VERSION ""

NS_ :

BS_:

BU_: WCM VPM VLM VKM UVM TIM TEST_TOOL_2 TEST_TOOL_1 TCP TCM TCCM3 TCCM STC SRR_SRR SRR_SLR SRR_RR SRR_RF SRR_LR_CR SRR_LF SIB SDM SCL SBZA_R SBZA_L SBM SADS RadioLow RSC RDCM PTM PDR PA NVM MTCM_R MTCM_L MSM_RR MSM_P MSM_LR MSM_D MSB2 MSB1 MRCM_R MRCM_L MFC LRR_HC LRR LIB1 IPC ICS_Info ICCM HVAC_FP_R HVAC_FP_F HUD_CAN HDLM FCM_LC FCM EPS EOCM_HCP2 EOCM_HCP1 EOCM ELM ECP_X1 ECP_MC ECP_E ECM EBCM DMS DEFC DCM CSM CMMb CMMa CGM BSM_MH BSM BCM ARS ARB APA AOS AMP ALC AHS AHL_AFL AGC

BO_ 212 C8_SRRSLRODP_First_Frame_PDU: 48 SRR_SLR
 SG_ SRRSLRODPB1P_MAC : 7|32@0+ (1,0) [0|4.29497e+009] "" EOCM_HCP1,EOCM_HCP2
 SG_ SRRSLRODPB1P_FCnt : 39|5@0+ (1,0) [0|31] "" EOCM_HCP1,EOCM_HCP2
 SG_ SRRSLRODPB1P_AcqTmStmAuth : 45|11@0+ (1,0) [0|2047] "ms" EOCM_HCP1,EOCM_HCP2
 SG_ SRRSLRODPB1P_BrstID : 47|2@0+ (1,0) [0|3] "" EOCM_HCP1,EOCM_HCP2
 SG_ SRRSLRODPB1P_CnstrArDtnCnfdAuth : 49|2@0+ (1,0) [0|3] "" EOCM_HCP1,EOCM_HCP2
 SG_ SRRSLRODPB1P_AcqTmStmAuth_Inv : 50|1@0+ (1,0) [0|1] "" EOCM_HCP1,EOCM_HCP2
 SG_ SRRSLRODPB1P_POTk1DynPrpAuth : 57|3@0+ (1,0) [0|4] "" EOCM_HCP1,EOCM_HCP2
 SG_ SRRSLRODPB1P_POTk1CnfdStsAuth : 59|2@0+ (1,0) [0|3] "" EOCM_HCP1,EOCM_HCP2
 SG_ SRRSLRODPB1P_MdCmdStsAuth : 61|2@0+ (1,0) [0|2] "" EOCM_HCP1,EOCM_HCP2
 SG_ SRRSLRODPB1P_CnstrArDtnStsAuth : 63|2@0+ (1,0) [0|2] "" EOCM_HCP1,EOCM_HCP2
 SG_ SRRSLRODPB1P_POTk1IDAuth : 70|7@0+ (1,0) [0|127] "" EOCM_HCP1,EOCM_HCP2
 SG_ SRRSLRODPB1P_POTk1MStsAuth : 73|2@0+ (1,0) [0|3] "" EOCM_HCP1,EOCM_HCP2
 SG_ SRRSLRODPB1P_POTk1InPthPotAuth : 79|6@0+ (2,0) [0|126] "%" EOCM_HCP1,EOCM_HCP2
 SG_ SRRSLRODPB1P_POTk1PoILAAuth : 87|9@0- (0.125,0) [-32|31.875] "m/s^2" EOCM_HCP1,EOCM_HCP2
 SG_ SRRSLRODPB1P_POTk1PoILgAAuth : 94|9@0- (0.125,0) [-32|31.875] "m/s^2" EOCM_HCP1,EOCM_HCP2
 SG_ SRRSLRODPB1P_POTk1PoILgPsAuth : 101|11@0- (0.125,0) [-128|127.875] "m" EOCM_HCP1,EOCM_HCP2
 SG_ SRRSLRODPB1P_POTk1PoILgVAuth : 106|10@0- (0.125,0) [-64|63.875] "m/s" EOCM_HCP1,EOCM_HCP2
 SG_ SRRSLRODPB1P_POTk1PoILPsAuth : 112|10@0- (0.125,0) [-64|63.875] "m" EOCM_HCP1,EOCM_HCP2
 SG_ SRRSLRODPB1P_POTk1PoILVAuth : 134|9@0- (0.125,0) [-32|31.875] "m/s" EOCM_HCP1,EOCM_HCP2
 SG_ SRRSLRODPB1P_POTk2CnfdStsAuth : 137|2@0+ (1,0) [0|3] "" EOCM_HCP1,EOCM_HCP2
 SG_ SRRSLRODPB1P_POTk1TypCnfdAuth : 139|2@0+ (1,0) [0|3] "" EOCM_HCP1,EOCM_HCP2
 SG_ SRRSLRODPB1P_POTk1TypAuth : 141|2@0+ (1,0) [0|2] "" EOCM_HCP1,EOCM_HCP2
 SG_ SRRSLRODPB1P_POTk2IDAuth : 148|7@0+ (1,0) [0|127] "" EOCM_HCP1,EOCM_HCP2
 SG_ SRRSLRODPB1P_POTk2DynPrpAuth : 151|3@0+ (1,0) [0|4] "" EOCM_HCP1,EOCM_HCP2
 SG_ SRRSLRODPB1P_POTk2InPthPotAuth : 157|6@0+ (2,0) [0|126] "%" EOCM_HCP1,EOCM_HCP2
 SG_ SRRSLRODPB1P_POTk2PoILAAuth : 165|9@0- (0.125,0) [-32|31.875] "m/s^2" EOCM_HCP1,EOCM_HCP2
 SG_ SRRSLRODPB1P_POTk2MStsAuth : 167|2@0+ (1,0) [0|3] "" EOCM_HCP1,EOCM_HCP2
 SG_ SRRSLRODPB1P_POTk2PoILgAAuth : 172|9@0- (0.125,0) [-32|31.875] "m/s^2" EOCM_HCP1,EOCM_HCP2
 SG_ SRRSLRODPB1P_POTk2PoILgPsAuth : 179|11@0- (0.125,0) [-128|127.875] "m" EOCM_HCP1,EOCM_HCP2
 SG_ SRRSLRODPB1P_POTk2PoILgVAuth : 184|10@0- (0.125,0) [-64|63.875] "m/s" EOCM_HCP1,EOCM_HCP2
 SG_ SRRSLRODPB1P_POTk2PoILPsAuth : 206|10@0- (0.125,0) [-64|63.875] "m" EOCM_HCP1,EOCM_HCP2
 SG_ SRRSLRODPB1P_POTk2PoILVAuth : 212|9@0- (0.125,0) [-32|31.875] "m/s" EOCM_HCP1,EOCM_HCP2
 SG_ SRRSLRODPB1P_POTk2TypCnfdAuth : 217|2@0+ (1,0) [0|3] "" EOCM_HCP1,EOCM_HCP2
 SG_ SRRSLRODPB1P_POTk2TypAuth : 219|2@0+ (1,0) [0|2] "" EOCM_HCP1,EOCM_HCP2
 SG_ SRRSLRODPB1P_SnsrUnvAuth : 224|1@0+ (1,0) [0|1] "" EOCM_HCP1,EOCM_HCP2
 SG_ SRRSLRODPB1P_SnsrBlckdAuth : 225|1@0+ (1,0) [0|1] "" EOCM_HCP1,EOCM_HCP2
 SG_ SRRSLRODPB1P_ServRqrdAuth : 226|1@0+ (1,0) [0|1] "" EOCM_HCP1,EOCM_HCP2
 SG_ SRRSLRODPB1P_RdTypCnfdAuth : 228|2@0+ (1,0) [0|3] "" EOCM_HCP1,EOCM_HCP2
 SG_ SRRSLRODPB1P_RdTypAuth : 231|3@0+ (1,0) [0|7] "" EOCM_HCP1,EOCM_HCP2
 SG_ SRRSLRODPB1P_VOTk1CICOPotAuth : 237|6@0+ (2,0) [0|126] "%" EOCM_HCP1,EOCM_HCP2
 SG_ SRRSLRODPB1P_SwpBndwdthStsAuth : 239|2@0+ (1,0) [0|3] "" EOCM_HCP1,EOCM_HCP2
 SG_ SRRSLRODPB1P_VOTk1IDAuth : 241|7@0+ (1,0) [0|127] "" EOCM_HCP1,EOCM_HCP2
 SG_ SRRSLRODPB1P_VOTk1DynPrpStsAuth : 242|1@0+ (1,0) [0|1] "" EOCM_HCP1,EOCM_HCP2
 SG_ SRRSLRODPB1P_VOTk1DynPrpAuth : 245|3@0+ (1,0) [0|4] "" EOCM_HCP1,EOCM_HCP2
 SG_ SRRSLRODPB1P_VOTk1CnfdStsAuth : 247|2@0+ (1,0) [0|3] "" EOCM_HCP1,EOCM_HCP2
 SG_ SRRSLRODPB1P_VOTk1PoILAAuth : 248|9@0- (0.125,0) [-32|31.875] "m/s^2" EOCM_HCP1,EOCM_HCP2
 SG_ SRRSLRODPB1P_VOTk1MStsAuth : 250|2@0+ (1,0) [0|3] "" EOCM_HCP1,EOCM_HCP2
 SG_ SRRSLRODPB1P_VOTk1PoILgAAuth : 271|9@0- (0.125,0) [-32|31.875] "m/s^2" EOCM_HCP1,EOCM_HCP2
 SG_ SRRSLRODPB1P_VOTk1PoILgPsAuth : 278|11@0- (0.125,0) [-128|127.875] "m" EOCM_HCP1,EOCM_HCP2
 SG_ SRRSLRODPB1P_VOTk1PoILgPsCAuth : 283|16@0+ (0.01,0) [0|655.35] "m^2" EOCM_HCP1,EOCM_HCP2
 SG_ SRRSLRODPB1P_VOTk1PoILgthAuth : 299|8@0+ (0.125,0) [0|31.875] "m" EOCM_HCP1,EOCM_HCP2
 SG_ SRRSLRODPB1P_VOTk1PoILgVAuth : 307|11@0- (0.125,0) [-128|127.875] "m/s" EOCM_HCP1,EOCM_HCP2
 SG_ SRRSLRODPB1P_VOTk1PoILgVCAuth : 312|10@0+ (0.125,0) [0|127.875] "(m/s)^2" EOCM_HCP1,EOCM_HCP2
 SG_ SRRSLRODPB1P_VOTk1PoILPsAuth : 334|10@0- (0.125,0) [-64|63.875] "m" EOCM_HCP1,EOCM_HCP2
 SG_ SRRSLRODPB1P_VOTk1PoILPsCAuth : 340|14@0+ (0.01,0) [0|163.83] "m^2" EOCM_HCP1,EOCM_HCP2
 SG_ SRRSLRODPB1P_VOTk1PoILVAuth : 358|9@0- (0.125,0) [-32|31.875] "m/s" EOCM_HCP1,EOCM_HCP2
 SG_ SRRSLRODPB1P_VOTk1PoILVCAuth : 365|10@0+ (0.125,0) [0|127.875] "(m/s)^2" EOCM_HCP1,EOCM_HCP2
 SG_ SRRSLRODPB1P_VOTk2PoILgthAuth : 369|8@0+ (0.125,0) [0|31.875] "m" EOCM_HCP1,EOCM_HCP2
 SG_ SRRSLRODPB1P_VOTk1TypCnfdAuth : 371|2@0+ (1,0) [0|3] "" EOCM_HCP1,EOCM_HCP2
 SG_ SRRSLRODPB1P_ARC : 377|2@0+ (1,0) [0|3] "" EOCM_HCP1,EOCM_HCP2

BO_ 217 C8_SRRSLRODP_Last_Frame_PDU: 48 SRR_SLR
 SG_ SRRSLRODPB6P_IOTk10PolLPsAuth : 5|10@0- (0.125,0) [-64|63.875] "m" EOCM_HCP1,EOCM_HCP2
 SG_ SRRSLRODPB6P_BrstID : 7|2@0+ (1,0) [0|3] "" EOCM_HCP1,EOCM_HCP2
 SG_ SRRSLRODPB6P_IOTk1PoILPsAuth : 11|10@0- (0.125,0) [-64|63.875] "m" EOCM_HCP1,EOCM_HCP2
 SG_ SRRSLRODPB6P_IOTk2PolLPsAuth : 17|10@0- (0.125,0) [-64|63.875] "m" EOCM_HCP1,EOCM_HCP2
 SG_ SRRSLRODPB6P_IOTk3PolLPsAuth : 39|10@0- (0.125,0) [-64|63.875] "m" EOCM_HCP1,EOCM_HCP2
 SG_ SRRSLRODPB6P_IOTk4PolLPsAuth : 45|10@0- (0.125,0) [-64|63.875] "m" EOCM_HCP1,EOCM_HCP2
 SG_ SRRSLRODPB6P_IOTk5PolLPsAuth : 51|10@0- (0.125,0) [-64|63.875] "m" EOCM_HCP1,EOCM_HCP2
 SG_ SRRSLRODPB6P_IOTk6PolLPsAuth : 57|10@0- (0.125,0) [-64|63.875] "m" EOCM_HCP1,EOCM_HCP2
 SG_ SRRSLRODPB6P_IOTk7PolLPsAuth : 79|10@0- (0.125,0) [-64|63.875] "m" EOCM_HCP1,EOCM_HCP2
 SG_ SRRSLRODPB6P_IOTk8PolLPsAuth : 85|10@0- (0.125,0) [-64|63.875] "m" EOCM_HCP1,EOCM_HCP2
 SG_ SRRSLRODPB6P_IOTk9PolLPsAuth : 91|10@0- (0.125,0) [-64|63.875] "m" EOCM_HCP1,EOCM_HCP2
 SG_ SRRSLRODPB6P_REOTk1CnfdStsAuth : 97|2@0+ (1,0) [0|3] "" EOCM_HCP1,EOCM_HCP2
 SG_ SRRSLRODPB6P_REOTk1CrvAuth : 111|16@0- (9.77e-07,0) [-0.0320143|0.0320134] "1/m" EOCM_HCP1,EOCM_HCP2
 SG_ SRRSLRODPB6P_REOTk1CrvDrvtAuth : 127|16@0- (3.73e-09,0) [-0.000122225|0.000122221] "1/m2" EOCM_HCP1,EOCM_HCP2
 SG_ SRRSLRODPB6P_REOTk1HdgAuth : 143|10@0- (0.000977,0) [-0.500224|0.499247] "rad" EOCM_HCP1,EOCM_HCP2
 SG_ SRRSLRODPB6P_REOTk1OfstAuth : 149|9@0- (0.125,0) [-32|31.875] "m" EOCM_HCP1,EOCM_HCP2
 SG_ SRRSLRODPB6P_REOTk1PsEndAuth : 156|11@0- (0.125,0) [-128|127.875] "m" EOCM_HCP1,EOCM_HCP2
 SG_ SRRSLRODPB6P_REOTk1PsStrtAuth : 161|11@0- (0.125,0) [-128|127.875] "m" EOCM_HCP1,EOCM_HCP2
 SG_ SRRSLRODPB6P_REOTk2CnfdStsAuth : 177|2@0+ (1,0) [0|3] "" EOCM_HCP1,EOCM_HCP2
 SG_ SRRSLRODPB6P_REOTk1TypCnfdAuth : 179|2@0+ (1,0) [0|3] "" EOCM_HCP1,EOCM_HCP2
 SG_ SRRSLRODPB6P_REOTk1TypAuth : 182|3@0+ (1,0) [0|5] "" EOCM_HCP1,EOCM_HCP2
 SG_ SRRSLRODPB6P_REOTk2CrvAuth : 191|16@0- (9.77e-07,0) [-0.0320143|0.0320134] "1/m" EOCM_HCP1,EOCM_HCP2
 SG_ SRRSLRODPB6P_REOTk2CrvDrvtAuth : 207|16@0- (3.73e-09,0) [-0.000122225|0.000122221] "1/m2" EOCM_HCP1,EOCM_HCP2
 SG_ SRRSLRODPB6P_REOTk2HdgAuth : 223|10@0- (0.000977,0) [-0.500224|0.499247] "rad" EOCM_HCP1,EOCM_HCP2
 SG_ SRRSLRODPB6P_REOTk2OfstAuth : 229|9@0- (0.125,0) [-32|31.875] "m" EOCM_HCP1,EOCM_HCP2
 SG_ SRRSLRODPB6P_REOTk2PsEndAuth : 236|11@0- (0.125,0) [-128|127.875] "m" EOCM_HCP1,EOCM_HCP2
 SG_ SRRSLRODPB6P_REOTk2PsStrtAuth : 241|11@0- (0.125,0) [-128|127.875] "m" EOCM_HCP1,EOCM_HCP2
 SG_ SRRSLRODPB6P_REOTk3CnfdStsAuth : 257|2@0+ (1,0) [0|3] "" EOCM_HCP1,EOCM_HCP2
 SG_ SRRSLRODPB6P_REOTk2TypCnfdAuth : 259|2@0+ (1,0) [0|3] "" EOCM_HCP1,EOCM_HCP2
 SG_ SRRSLRODPB6P_REOTk2TypAuth : 262|3@0+ (1,0) [0|5] "" EOCM_HCP1,EOCM_HCP2
 SG_ SRRSLRODPB6P_REOTk3CrvAuth : 271|16@0- (9.77e-07,0) [-0.0320143|0.0320134] "1/m" EOCM_HCP1,EOCM_HCP2
 SG_ SRRSLRODPB6P_REOTk3CrvDrvtAuth : 287|16@0- (3.73e-09,0) [-0.000122225|0.000122221] "1/m2" EOCM_HCP1,EOCM_HCP2
 SG_ SRRSLRODPB6P_REOTk3HdgAuth : 303|10@0- (0.000977,0) [-0.500224|0.499247] "rad" EOCM_HCP1,EOCM_HCP2
 SG_ SRRSLRODPB6P_REOTk3OfstAuth : 309|9@0- (0.125,0) [-32|31.875] "m" EOCM_HCP1,EOCM_HCP2
 SG_ SRRSLRODPB6P_REOTk3PsEndAuth : 316|11@0- (0.125,0) [-128|127.875] "m" EOCM_HCP1,EOCM_HCP2
 SG_ SRRSLRODPB6P_REOTk3PsStrtAuth : 321|11@0- (0.125,0) [-128|127.875] "m" EOCM_HCP1,EOCM_HCP2
 SG_ SRRSLRODPB6P_REOTk3TypCnfdAuth : 339|2@0+ (1,0) [0|3] "" EOCM_HCP1,EOCM_HCP2
 SG_ SRRSLRODPB6P_REOTk3TypAuth : 342|3@0+ (1,0) [0|5] "" EOCM_HCP1,EOCM_HCP2

BO_ 219 C8_SRRSRRODP_Consecutive_Frame_N: 64 SRR_SRR
 SG_ SRRSRRODPB2P_POTk3IDAuth : 0|7@0+ (1,0) [0|127] "" EOCM_HCP1,EOCM_HCP2
 SG_ SRRSRRODPB2P_POTk3DynPrpAuth : 3|3@0+ (1,0) [0|4] "" EOCM_HCP1,EOCM_HCP2
 SG_ SRRSRRODPB2P_POTk3CnfdStsAuth : 5|2@0+ (1,0) [0|3] "" EOCM_HCP1,EOCM_HCP2
 SG_ SRRSRRODPB2P_BrstID : 7|2@0+ (1,0) [0|3] "" EOCM_HCP1,EOCM_HCP2
 SG_ SRRSRRODPB2P_POTk3InPthPotAuth : 9|6@0+ (2,0) [0|126] "%" EOCM_HCP1,EOCM_HCP2
 SG_ SRRSRRODPB2P_POTk3PoILAAuth : 17|9@0- (0.125,0) [-32|31.875] "m/s^2" EOCM_HCP1,EOCM_HCP2
 SG_ SRRSRRODPB2P_POTk3MStsAuth : 19|2@0+ (1,0) [0|3] "" EOCM_HCP1,EOCM_HCP2
 SG_ SRRSRRODPB2P_POTk3PoILgAAuth : 24|9@0- (0.125,0) [-32|31.875] "m/s^2" EOCM_HCP1,EOCM_HCP2
 SG_ SRRSRRODPB2P_POTk3PoILgPsAuth : 47|11@0- (0.125,0) [-128|127.875] "m" EOCM_HCP1,EOCM_HCP2
 SG_ SRRSRRODPB2P_POTk3PoILgVAuth : 52|10@0- (0.125,0) [-64|63.875] "m/s" EOCM_HCP1,EOCM_HCP2
 SG_ SRRSRRODPB2P_POTk3PoILPsAuth : 58|10@0- (0.125,0) [-64|63.875] "m" EOCM_HCP1,EOCM_HCP2
 SG_ SRRSRRODPB2P_POTk3PoILVAuth : 64|9@0- (0.125,0) [-32|31.875] "m/s" EOCM_HCP1,EOCM_HCP2
 SG_ SRRSRRODPB2P_VOTk2CICOPotAuth : 83|6@0+ (2,0) [0|126] "%" EOCM_HCP1,EOCM_HCP2
 SG_ SRRSRRODPB2P_POTk3TypCnfdAuth : 85|2@0+ (1,0) [0|3] "" EOCM_HCP1,EOCM_HCP2
 SG_ SRRSRRODPB2P_POTk3TypAuth : 87|2@0+ (1,0) [0|2] "" EOCM_HCP1,EOCM_HCP2
 SG_ SRRSRRODPB2P_VOTk2DynPrpStsAuth : 88|1@0+ (1,0) [0|1] "" EOCM_HCP1,EOCM_HCP2
 SG_ SRRSRRODPB2P_VOTk2DynPrpAuth : 91|3@0+ (1,0) [0|4] "" EOCM_HCP1,EOCM_HCP2
 SG_ SRRSRRODPB2P_VOTk2CnfdStsAuth : 93|2@0+ (1,0) [0|3] "" EOCM_HCP1,EOCM_HCP2
 SG_ SRRSRRODPB2P_VOTk2MStsAuth : 96|2@0+ (1,0) [0|3] "" EOCM_HCP1,EOCM_HCP2
 SG_ SRRSRRODPB2P_VOTk2IDAuth : 103|7@0+ (1,0) [0|127] "" EOCM_HCP1,EOCM_HCP2
 SG_ SRRSRRODPB2P_VOTk2PoILAAuth : 110|9@0- (0.125,0) [-32|31.875] "m/s^2" EOCM_HCP1,EOCM_HCP2
 SG_ SRRSRRODPB2P_VOTk2PoILgAAuth : 117|9@0- (0.125,0) [-32|31.875] "m/s^2" EOCM_HCP1,EOCM_HCP2
 SG_ SRRSRRODPB2P_VOTk2PoILgPsAuth : 124|11@0- (0.125,0) [-128|127.875] "m" EOCM_HCP1,EOCM_HCP2
 SG_ SRRSRRODPB2P_VOTk2PoILgPsCAuth : 129|16@0+ (0.01,0) [0|655.35] "m^2" EOCM_HCP1,EOCM_HCP2
 SG_ SRRSRRODPB2P_VOTk2PoILgVAuth : 145|11@0- (0.125,0) [-128|127.875] "m/s" EOCM_HCP1,EOCM_HCP2
 SG_ SRRSRRODPB2P_VOTk2PoILgVCAuth : 166|10@0+ (0.125,0) [0|127.875] "(m/s)^2" EOCM_HCP1,EOCM_HCP2
 SG_ SRRSRRODPB2P_VOTk2PoILPsAuth : 172|10@0- (0.125,0) [-64|63.875] "m" EOCM_HCP1,EOCM_HCP2
 SG_ SRRSRRODPB2P_VOTk2PoILPsCAuth : 178|14@0+ (0.01,0) [0|163.83] "m^2" EOCM_HCP1,EOCM_HCP2
 SG_ SRRSRRODPB2P_VOTk2PoILVAuth : 196|9@0- (0.125,0) [-32|31.875] "m/s" EOCM_HCP1,EOCM_HCP2
 SG_ SRRSRRODPB2P_VOTk2PoILVCAuth : 203|10@0+ (0.125,0) [0|127.875] "(m/s)^2" EOCM_HCP1,EOCM_HCP2
 SG_ SRRSRRODPB2P_VOTk2TypCnfdAuth : 209|2@0+ (1,0) [0|3] "" EOCM_HCP1,EOCM_HCP2
 SG_ SRRSRRODPB2P_VOTk3CnfdStsAuth : 217|2@0+ (1,0) [0|3] "" EOCM_HCP1,EOCM_HCP2
 SG_ SRRSRRODPB2P_VOTk3CICOPotAuth : 223|6@0+ (2,0) [0|126] "%" EOCM_HCP1,EOCM_HCP2
 SG_ SRRSRRODPB2P_VOTk3IDAuth : 227|7@0+ (1,0) [0|127] "" EOCM_HCP1,EOCM_HCP2
 SG_ SRRSRRODPB2P_VOTk3DynPrpStsAuth : 228|1@0+ (1,0) [0|1] "" EOCM_HCP1,EOCM_HCP2
 SG_ SRRSRRODPB2P_VOTk3DynPrpAuth : 231|3@0+ (1,0) [0|4] "" EOCM_HCP1,EOCM_HCP2
 SG_ SRRSRRODPB2P_VOTk3PoILAAuth : 234|9@0- (0.125,0) [-32|31.875] "m/s^2" EOCM_HCP1,EOCM_HCP2
 SG_ SRRSRRODPB2P_VOTk3MStsAuth : 236|2@0+ (1,0) [0|3] "" EOCM_HCP1,EOCM_HCP2
 SG_ SRRSRRODPB2P_VOTk3PoILgAAuth : 241|9@0- (0.125,0) [-32|31.875] "m/s^2" EOCM_HCP1,EOCM_HCP2
 SG_ SRRSRRODPB2P_VOTk3PoILgPsAuth : 248|11@0- (0.125,0) [-128|127.875] "m" EOCM_HCP1,EOCM_HCP2
 SG_ SRRSRRODPB2P_VOTk3PoILgPsCAuth : 269|16@0+ (0.01,0) [0|655.35] "m^2" EOCM_HCP1,EOCM_HCP2
 SG_ SRRSRRODPB2P_VOTk3PoILgthAuth : 285|8@0+ (0.125,0) [0|31.875] "m" EOCM_HCP1,EOCM_HCP2
 SG_ SRRSRRODPB2P_VOTk3PoILgVAuth : 293|11@0- (0.125,0) [-128|127.875] "m/s" EOCM_HCP1,EOCM_HCP2
 SG_ SRRSRRODPB2P_VOTk3PoILgVCAuth : 298|10@0+ (0.125,0) [0|127.875] "(m/s)^2" EOCM_HCP1,EOCM_HCP2
 SG_ SRRSRRODPB2P_VOTk3PoILPsAuth : 304|10@0- (0.125,0) [-64|63.875] "m" EOCM_HCP1,EOCM_HCP2
 SG_ SRRSRRODPB2P_VOTk3PoILPsCAuth : 326|14@0+ (0.01,0) [0|163.83] "m^2" EOCM_HCP1,EOCM_HCP2
 SG_ SRRSRRODPB2P_VOTk3PoILVAuth : 328|9@0- (0.125,0) [-32|31.875] "m/s" EOCM_HCP1,EOCM_HCP2
 SG_ SRRSRRODPB2P_VOTk3PoILVCAuth : 351|10@0+ (0.125,0) [0|127.875] "(m/s)^2" EOCM_HCP1,EOCM_HCP2
 SG_ SRRSRRODPB2P_VOTk4CICOPotAuth : 355|6@0+ (2,0) [0|126] "%" EOCM_HCP1,EOCM_HCP2
 SG_ SRRSRRODPB2P_VOTk3TypCnfdAuth : 357|2@0+ (1,0) [0|3] "" EOCM_HCP1,EOCM_HCP2
 SG_ SRRSRRODPB2P_VOTk4DynPrpStsAuth : 360|1@0+ (1,0) [0|1] "" EOCM_HCP1,EOCM_HCP2
 SG_ SRRSRRODPB2P_VOTk4DynPrpAuth : 363|3@0+ (1,0) [0|4] "" EOCM_HCP1,EOCM_HCP2
 SG_ SRRSRRODPB2P_VOTk4CnfdStsAuth : 365|2@0+ (1,0) [0|3] "" EOCM_HCP1,EOCM_HCP2
 SG_ SRRSRRODPB2P_VOTk4MStsAuth : 368|2@0+ (1,0) [0|3] "" EOCM_HCP1,EOCM_HCP2
 SG_ SRRSRRODPB2P_VOTk4IDAuth : 375|7@0+ (1,0) [0|127] "" EOCM_HCP1,EOCM_HCP2
 SG_ SRRSRRODPB2P_VOTk4PoILAAuth : 382|9@0- (0.125,0) [-32|31.875] "m/s^2" EOCM_HCP1,EOCM_HCP2
 SG_ SRRSRRODPB2P_VOTk4PoILgAAuth : 389|9@0- (0.125,0) [-32|31.875] "m/s^2" EOCM_HCP1,EOCM_HCP2
 SG_ SRRSRRODPB2P_VOTk4PoILgPsAuth : 396|11@0- (0.125,0) [-128|127.875] "m" EOCM_HCP1,EOCM_HCP2
 SG_ SRRSRRODPB2P_VOTk4PoILgPsCAuth : 401|16@0+ (0.01,0) [0|655.35] "m^2" EOCM_HCP1,EOCM_HCP2
 SG_ SRRSRRODPB2P_VOTk4PoILgthAuth : 417|8@0+ (0.125,0) [0|31.875] "m" EOCM_HCP1,EOCM_HCP2
 SG_ SRRSRRODPB2P_VOTk4PoILgVAuth : 425|11@0- (0.125,0) [-128|127.875] "m/s" EOCM_HCP1,EOCM_HCP2
 SG_ SRRSRRODPB2P_VOTk4PoILgVCAuth : 446|10@0+ (0.125,0) [0|127.875] "(m/s)^2" EOCM_HCP1,EOCM_HCP2
 SG_ SRRSRRODPB2P_VOTk4PoILPsAuth : 452|10@0- (0.125,0) [-64|63.875] "m" EOCM_HCP1,EOCM_HCP2
 SG_ SRRSRRODPB2P_VOTk4PoILPsCAuth : 458|14@0+ (0.01,0) [0|163.83] "m^2" EOCM_HCP1,EOCM_HCP2
 SG_ SRRSRRODPB2P_VOTk4PoILVAuth : 476|9@0- (0.125,0) [-32|31.875] "m/s" EOCM_HCP1,EOCM_HCP2
 SG_ SRRSRRODPB2P_VOTk4PoILVCAuth : 483|10@0+ (0.125,0) [0|127.875] "(m/s)^2" EOCM_HCP1,EOCM_HCP2
 SG_ SRRSRRODPB2P_VOTk4TypCnfdAuth : 489|2@0+ (1,0) [0|3] "" EOCM_HCP1,EOCM_HCP2
 SG_ SRRSRRODPB2P_VOTk5PoILgthAuth : 503|8@0+ (0.125,0) [0|31.875] "m" EOCM_HCP1,EOCM_HCP2

BO_ 220 C8_SRRSRRODP_Consecutive_Frame01: 64 SRR_SRR
 SG_ SRRSRRODPB3P_POTk4IDAuth : 0|7@0+ (1,0) [0|127] "" EOCM_HCP1,EOCM_HCP2
 SG_ SRRSRRODPB3P_POTk4DynPrpAuth : 3|3@0+ (1,0) [0|4] "" EOCM_HCP1,EOCM_HCP2
 SG_ SRRSRRODPB3P_POTk4CnfdStsAuth : 5|2@0+ (1,0) [0|3] "" EOCM_HCP1,EOCM_HCP2
 SG_ SRRSRRODPB3P_BrstID : 7|2@0+ (1,0) [0|3] "" EOCM_HCP1,EOCM_HCP2
 SG_ SRRSRRODPB3P_POTk4InPthPotAuth : 9|6@0+ (2,0) [0|126] "%" EOCM_HCP1,EOCM_HCP2
 SG_ SRRSRRODPB3P_POTk4PoILAAuth : 17|9@0- (0.125,0) [-32|31.875] "m/s^2" EOCM_HCP1,EOCM_HCP2
 SG_ SRRSRRODPB3P_POTk4MStsAuth : 19|2@0+ (1,0) [0|3] "" EOCM_HCP1,EOCM_HCP2
 SG_ SRRSRRODPB3P_POTk4PoILgAAuth : 24|9@0- (0.125,0) [-32|31.875] "m/s^2" EOCM_HCP1,EOCM_HCP2
 SG_ SRRSRRODPB3P_POTk4PoILgPsAuth : 47|11@0- (0.125,0) [-128|127.875] "m" EOCM_HCP1,EOCM_HCP2
 SG_ SRRSRRODPB3P_POTk4PoILgVAuth : 52|10@0- (0.125,0) [-64|63.875] "m/s" EOCM_HCP1,EOCM_HCP2
 SG_ SRRSRRODPB3P_POTk4PoILPsAuth : 58|10@0- (0.125,0) [-64|63.875] "m" EOCM_HCP1,EOCM_HCP2
 SG_ SRRSRRODPB3P_POTk4PoILVAuth : 64|9@0- (0.125,0) [-32|31.875] "m/s" EOCM_HCP1,EOCM_HCP2
 SG_ SRRSRRODPB3P_VOTk5CICOPotAuth : 83|6@0+ (2,0) [0|126] "%" EOCM_HCP1,EOCM_HCP2
 SG_ SRRSRRODPB3P_POTk4TypCnfdAuth : 85|2@0+ (1,0) [0|3] "" EOCM_HCP1,EOCM_HCP2
 SG_ SRRSRRODPB3P_POTk4TypAuth : 87|2@0+ (1,0) [0|2] "" EOCM_HCP1,EOCM_HCP2
 SG_ SRRSRRODPB3P_VOTk5DynPrpStsAuth : 88|1@0+ (1,0) [0|1] "" EOCM_HCP1,EOCM_HCP2
 SG_ SRRSRRODPB3P_VOTk5DynPrpAuth : 91|3@0+ (1,0) [0|4] "" EOCM_HCP1,EOCM_HCP2
 SG_ SRRSRRODPB3P_VOTk5CnfdStsAuth : 93|2@0+ (1,0) [0|3] "" EOCM_HCP1,EOCM_HCP2
 SG_ SRRSRRODPB3P_VOTk5MStsAuth : 96|2@0+ (1,0) [0|3] "" EOCM_HCP1,EOCM_HCP2
 SG_ SRRSRRODPB3P_VOTk5IDAuth : 103|7@0+ (1,0) [0|127] "" EOCM_HCP1,EOCM_HCP2
 SG_ SRRSRRODPB3P_VOTk5PoILAAuth : 110|9@0- (0.125,0) [-32|31.875] "m/s^2" EOCM_HCP1,EOCM_HCP2
 SG_ SRRSRRODPB3P_VOTk5PoILgAAuth : 117|9@0- (0.125,0) [-32|31.875] "m/s^2" EOCM_HCP1,EOCM_HCP2
 SG_ SRRSRRODPB3P_VOTk5PoILgPsAuth : 124|11@0- (0.125,0) [-128|127.875] "m" EOCM_HCP1,EOCM_HCP2
 SG_ SRRSRRODPB3P_VOTk5PoILgPsCAuth : 129|16@0+ (0.01,0) [0|655.35] "m^2" EOCM_HCP1,EOCM_HCP2
 SG_ SRRSRRODPB3P_VOTk5PoILgVAuth : 145|11@0- (0.125,0) [-128|127.875] "m/s" EOCM_HCP1,EOCM_HCP2
 SG_ SRRSRRODPB3P_VOTk5PoILgVCAuth : 166|10@0+ (0.125,0) [0|127.875] "(m/s)^2" EOCM_HCP1,EOCM_HCP2
 SG_ SRRSRRODPB3P_VOTk5PoILPsAuth : 172|10@0- (0.125,0) [-64|63.875] "m" EOCM_HCP1,EOCM_HCP2
 SG_ SRRSRRODPB3P_VOTk5PoILPsCAuth : 178|14@0+ (0.01,0) [0|163.83] "m^2" EOCM_HCP1,EOCM_HCP2
 SG_ SRRSRRODPB3P_VOTk5PoILVAuth : 196|9@0- (0.125,0) [-32|31.875] "m/s" EOCM_HCP1,EOCM_HCP2
 SG_ SRRSRRODPB3P_VOTk5PoILVCAuth : 203|10@0+ (0.125,0) [0|127.875] "(m/s)^2" EOCM_HCP1,EOCM_HCP2
 SG_ SRRSRRODPB3P_VOTk5TypCnfdAuth : 209|2@0+ (1,0) [0|3] "" EOCM_HCP1,EOCM_HCP2
 SG_ SRRSRRODPB3P_VOTk6CnfdStsAuth : 217|2@0+ (1,0) [0|3] "" EOCM_HCP1,EOCM_HCP2
 SG_ SRRSRRODPB3P_VOTk6CICOPotAuth : 223|6@0+ (2,0) [0|126] "%" EOCM_HCP1,EOCM_HCP2
 SG_ SRRSRRODPB3P_VOTk6IDAuth : 227|7@0+ (1,0) [0|127] "" EOCM_HCP1,EOCM_HCP2
 SG_ SRRSRRODPB3P_VOTk6DynPrpStsAuth : 228|1@0+ (1,0) [0|1] "" EOCM_HCP1,EOCM_HCP2
 SG_ SRRSRRODPB3P_VOTk6DynPrpAuth : 231|3@0+ (1,0) [0|4] "" EOCM_HCP1,EOCM_HCP2
 SG_ SRRSRRODPB3P_VOTk6PoILAAuth : 234|9@0- (0.125,0) [-32|31.875] "m/s^2" EOCM_HCP1,EOCM_HCP2
 SG_ SRRSRRODPB3P_VOTk6MStsAuth : 236|2@0+ (1,0) [0|3] "" EOCM_HCP1,EOCM_HCP2
 SG_ SRRSRRODPB3P_VOTk6PoILgAAuth : 241|9@0- (0.125,0) [-32|31.875] "m/s^2" EOCM_HCP1,EOCM_HCP2
 SG_ SRRSRRODPB3P_VOTk6PoILgPsAuth : 248|11@0- (0.125,0) [-128|127.875] "m" EOCM_HCP1,EOCM_HCP2
 SG_ SRRSRRODPB3P_VOTk6PoILgPsCAuth : 269|16@0+ (0.01,0) [0|655.35] "m^2" EOCM_HCP1,EOCM_HCP2
 SG_ SRRSRRODPB3P_VOTk6PoILgthAuth : 285|8@0+ (0.125,0) [0|31.875] "m" EOCM_HCP1,EOCM_HCP2
 SG_ SRRSRRODPB3P_VOTk6PoILgVAuth : 293|11@0- (0.125,0) [-128|127.875] "m/s" EOCM_HCP1,EOCM_HCP2
 SG_ SRRSRRODPB3P_VOTk6PoILgVCAuth : 298|10@0+ (0.125,0) [0|127.875] "(m/s)^2" EOCM_HCP1,EOCM_HCP2
 SG_ SRRSRRODPB3P_VOTk6PoILPsAuth : 304|10@0- (0.125,0) [-64|63.875] "m" EOCM_HCP1,EOCM_HCP2
 SG_ SRRSRRODPB3P_VOTk6PoILPsCAuth : 326|14@0+ (0.01,0) [0|163.83] "m^2" EOCM_HCP1,EOCM_HCP2
 SG_ SRRSRRODPB3P_VOTk6PoILVAuth : 328|9@0- (0.125,0) [-32|31.875] "m/s" EOCM_HCP1,EOCM_HCP2
 SG_ SRRSRRODPB3P_VOTk6PoILVCAuth : 351|10@0+ (0.125,0) [0|127.875] "(m/s)^2" EOCM_HCP1,EOCM_HCP2
 SG_ SRRSRRODPB3P_VOTk7CICOPotAuth : 355|6@0+ (2,0) [0|126] "%" EOCM_HCP1,EOCM_HCP2
 SG_ SRRSRRODPB3P_VOTk6TypCnfdAuth : 357|2@0+ (1,0) [0|3] "" EOCM_HCP1,EOCM_HCP2
 SG_ SRRSRRODPB3P_VOTk7DynPrpStsAuth : 360|1@0+ (1,0) [0|1] "" EOCM_HCP1,EOCM_HCP2
 SG_ SRRSRRODPB3P_VOTk7DynPrpAuth : 363|3@0+ (1,0) [0|4] "" EOCM_HCP1,EOCM_HCP2
 SG_ SRRSRRODPB3P_VOTk7CnfdStsAuth : 365|2@0+ (1,0) [0|3] "" EOCM_HCP1,EOCM_HCP2
 SG_ SRRSRRODPB3P_VOTk7MStsAuth : 368|2@0+ (1,0) [0|3] "" EOCM_HCP1,EOCM_HCP2
 SG_ SRRSRRODPB3P_VOTk7IDAuth : 375|7@0+ (1,0) [0|127] "" EOCM_HCP1,EOCM_HCP2
 SG_ SRRSRRODPB3P_VOTk7PoILAAuth : 382|9@0- (0.125,0) [-32|31.875] "m/s^2" EOCM_HCP1,EOCM_HCP2
 SG_ SRRSRRODPB3P_VOTk7PoILgAAuth : 389|9@0- (0.125,0) [-32|31.875] "m/s^2" EOCM_HCP1,EOCM_HCP2
 SG_ SRRSRRODPB3P_VOTk7PoILgPsAuth : 396|11@0- (0.125,0) [-128|127.875] "m" EOCM_HCP1,EOCM_HCP2
 SG_ SRRSRRODPB3P_VOTk7PoILgPsCAuth : 401|16@0+ (0.01,0) [0|655.35] "m^2" EOCM_HCP1,EOCM_HCP2
 SG_ SRRSRRODPB3P_VOTk7PoILgthAuth : 417|8@0+ (0.125,0) [0|31.875] "m" EOCM_HCP1,EOCM_HCP2
 SG_ SRRSRRODPB3P_VOTk7PoILgVAuth : 425|11@0- (0.125,0) [-128|127.875] "m/s" EOCM_HCP1,EOCM_HCP2
 SG_ SRRSRRODPB3P_VOTk7PoILgVCAuth : 446|10@0+ (0.125,0) [0|127.875] "(m/s)^2" EOCM_HCP1,EOCM_HCP2
 SG_ SRRSRRODPB3P_VOTk7PoILPsAuth : 452|10@0- (0.125,0) [-64|63.875] "m" EOCM_HCP1,EOCM_HCP2
 SG_ SRRSRRODPB3P_VOTk7PoILPsCAuth : 458|14@0+ (0.01,0) [0|163.83] "m^2" EOCM_HCP1,EOCM_HCP2
 SG_ SRRSRRODPB3P_VOTk7PoILVAuth : 476|9@0- (0.125,0) [-32|31.875] "m/s" EOCM_HCP1,EOCM_HCP2
 SG_ SRRSRRODPB3P_VOTk7PoILVCAuth : 483|10@0+ (0.125,0) [0|127.875] "(m/s)^2" EOCM_HCP1,EOCM_HCP2
 SG_ SRRSRRODPB3P_VOTk7TypCnfdAuth : 489|2@0+ (1,0) [0|3] "" EOCM_HCP1,EOCM_HCP2
 SG_ SRRSRRODPB3P_VOTk8PoILgthAuth : 503|8@0+ (0.125,0) [0|31.875] "m" EOCM_HCP1,EOCM_HCP2

BO_ 221 C8_SRRSRRODP_Consecutive_Frame02: 64 SRR_SRR
 SG_ SRRSRRODPB4P_POTk5IDAuth : 0|7@0+ (1,0) [0|127] "" EOCM_HCP1,EOCM_HCP2
 SG_ SRRSRRODPB4P_POTk5DynPrpAuth : 3|3@0+ (1,0) [0|4] "" EOCM_HCP1,EOCM_HCP2
 SG_ SRRSRRODPB4P_POTk5CnfdStsAuth : 5|2@0+ (1,0) [0|3] "" EOCM_HCP1,EOCM_HCP2
 SG_ SRRSRRODPB4P_BrstID : 7|2@0+ (1,0) [0|3] "" EOCM_HCP1,EOCM_HCP2
 SG_ SRRSRRODPB4P_POTk5InPthPotAuth : 9|6@0+ (2,0) [0|126] "%" EOCM_HCP1,EOCM_HCP2
 SG_ SRRSRRODPB4P_POTk5PoILAAuth : 17|9@0- (0.125,0) [-32|31.875] "m/s^2" EOCM_HCP1,EOCM_HCP2
 SG_ SRRSRRODPB4P_POTk5MStsAuth : 19|2@0+ (1,0) [0|3] "" EOCM_HCP1,EOCM_HCP2
 SG_ SRRSRRODPB4P_POTk5PoILgAAuth : 24|9@0- (0.125,0) [-32|31.875] "m/s^2" EOCM_HCP1,EOCM_HCP2
 SG_ SRRSRRODPB4P_POTk5PoILgPsAuth : 47|11@0- (0.125,0) [-128|127.875] "m" EOCM_HCP1,EOCM_HCP2
 SG_ SRRSRRODPB4P_POTk5PoILgVAuth : 52|10@0- (0.125,0) [-64|63.875] "m/s" EOCM_HCP1,EOCM_HCP2
 SG_ SRRSRRODPB4P_POTk5PoILPsAuth : 58|10@0- (0.125,0) [-64|63.875] "m" EOCM_HCP1,EOCM_HCP2
 SG_ SRRSRRODPB4P_POTk5PoILVAuth : 64|9@0- (0.125,0) [-32|31.875] "m/s" EOCM_HCP1,EOCM_HCP2
 SG_ SRRSRRODPB4P_VOTk10CICOPotAuth : 83|6@0+ (2,0) [0|126] "%" EOCM_HCP1,EOCM_HCP2
 SG_ SRRSRRODPB4P_POTk5TypCnfdAuth : 85|2@0+ (1,0) [0|3] "" EOCM_HCP1,EOCM_HCP2
 SG_ SRRSRRODPB4P_POTk5TypAuth : 87|2@0+ (1,0) [0|2] "" EOCM_HCP1,EOCM_HCP2
 SG_ SRRSRRODPB4P_VOTk10DynPrpStAuth : 88|1@0+ (1,0) [0|1] "" EOCM_HCP1,EOCM_HCP2
 SG_ SRRSRRODPB4P_VOTk10DynPrpAuth : 91|3@0+ (1,0) [0|4] "" EOCM_HCP1,EOCM_HCP2
 SG_ SRRSRRODPB4P_VOTk10CnfdStsAuth : 93|2@0+ (1,0) [0|3] "" EOCM_HCP1,EOCM_HCP2
 SG_ SRRSRRODPB4P_VOTk10MStsAuth : 96|2@0+ (1,0) [0|3] "" EOCM_HCP1,EOCM_HCP2
 SG_ SRRSRRODPB4P_VOTk10IDAuth : 103|7@0+ (1,0) [0|127] "" EOCM_HCP1,EOCM_HCP2
 SG_ SRRSRRODPB4P_VOTk10PoILAAuth : 110|9@0- (0.125,0) [-32|31.875] "m/s^2" EOCM_HCP1,EOCM_HCP2
 SG_ SRRSRRODPB4P_VOTk10PoILgAAuth : 117|9@0- (0.125,0) [-32|31.875] "m/s^2" EOCM_HCP1,EOCM_HCP2
 SG_ SRRSRRODPB4P_VOTk10PoILgPsAuth : 124|11@0- (0.125,0) [-128|127.875] "m" EOCM_HCP1,EOCM_HCP2
 SG_ SRRSRRODPB4P_VOTk10PoILgPsCAuth : 129|16@0+ (0.01,0) [0|655.35] "m^2" EOCM_HCP1,EOCM_HCP2
 SG_ SRRSRRODPB4P_VOTk10PoILgthAuth : 145|8@0+ (0.125,0) [0|31.875] "m" EOCM_HCP1,EOCM_HCP2
 SG_ SRRSRRODPB4P_VOTk10PoILgVAuth : 153|11@0- (0.125,0) [-128|127.875] "m/s" EOCM_HCP1,EOCM_HCP2
 SG_ SRRSRRODPB4P_VOTk10PoILgVCAuth : 174|10@0+ (0.125,0) [0|127.875] "(m/s)^2" EOCM_HCP1,EOCM_HCP2
 SG_ SRRSRRODPB4P_VOTk10PoILPsAuth : 180|10@0- (0.125,0) [-64|63.875] "m" EOCM_HCP1,EOCM_HCP2
 SG_ SRRSRRODPB4P_VOTk10PoILPsCAuth : 186|14@0+ (0.01,0) [0|163.83] "m^2" EOCM_HCP1,EOCM_HCP2
 SG_ SRRSRRODPB4P_VOTk10PoILVAuth : 204|9@0- (0.125,0) [-32|31.875] "m/s" EOCM_HCP1,EOCM_HCP2
 SG_ SRRSRRODPB4P_VOTk10PoILVCAuth : 211|10@0+ (0.125,0) [0|127.875] "(m/s)^2" EOCM_HCP1,EOCM_HCP2
 SG_ SRRSRRODPB4P_VOTk10TypCnfdAuth : 217|2@0+ (1,0) [0|3] "" EOCM_HCP1,EOCM_HCP2
 SG_ SRRSRRODPB4P_VOTk8CnfdStsAuth : 225|2@0+ (1,0) [0|3] "" EOCM_HCP1,EOCM_HCP2
 SG_ SRRSRRODPB4P_VOTk8CICOPotAuth : 231|6@0+ (2,0) [0|126] "%" EOCM_HCP1,EOCM_HCP2
 SG_ SRRSRRODPB4P_VOTk8IDAuth : 235|7@0+ (1,0) [0|127] "" EOCM_HCP1,EOCM_HCP2
 SG_ SRRSRRODPB4P_VOTk8DynPrpStsAuth : 236|1@0+ (1,0) [0|1] "" EOCM_HCP1,EOCM_HCP2
 SG_ SRRSRRODPB4P_VOTk8DynPrpAuth : 239|3@0+ (1,0) [0|4] "" EOCM_HCP1,EOCM_HCP2
 SG_ SRRSRRODPB4P_VOTk8PoILAAuth : 242|9@0- (0.125,0) [-32|31.875] "m/s^2" EOCM_HCP1,EOCM_HCP2
 SG_ SRRSRRODPB4P_VOTk8MStsAuth : 244|2@0+ (1,0) [0|3] "" EOCM_HCP1,EOCM_HCP2
 SG_ SRRSRRODPB4P_VOTk8PoILgAAuth : 249|9@0- (0.125,0) [-32|31.875] "m/s^2" EOCM_HCP1,EOCM_HCP2
 SG_ SRRSRRODPB4P_VOTk8PoILgPsAuth : 256|11@0- (0.125,0) [-128|127.875] "m" EOCM_HCP1,EOCM_HCP2
 SG_ SRRSRRODPB4P_VOTk8PoILgPsCAuth : 277|16@0+ (0.01,0) [0|655.35] "m^2" EOCM_HCP1,EOCM_HCP2
 SG_ SRRSRRODPB4P_VOTk8PoILgVAuth : 293|11@0- (0.125,0) [-128|127.875] "m/s" EOCM_HCP1,EOCM_HCP2
 SG_ SRRSRRODPB4P_VOTk8PoILgVCAuth : 298|10@0+ (0.125,0) [0|127.875] "(m/s)^2" EOCM_HCP1,EOCM_HCP2
 SG_ SRRSRRODPB4P_VOTk8PoILPsAuth : 304|10@0- (0.125,0) [-64|63.875] "m" EOCM_HCP1,EOCM_HCP2
 SG_ SRRSRRODPB4P_VOTk8PoILPsCAuth : 326|14@0+ (0.01,0) [0|163.83] "m^2" EOCM_HCP1,EOCM_HCP2
 SG_ SRRSRRODPB4P_VOTk8PoILVAuth : 328|9@0- (0.125,0) [-32|31.875] "m/s" EOCM_HCP1,EOCM_HCP2
 SG_ SRRSRRODPB4P_VOTk8PoILVCAuth : 351|10@0+ (0.125,0) [0|127.875] "(m/s)^2" EOCM_HCP1,EOCM_HCP2
 SG_ SRRSRRODPB4P_VOTk9CICOPotAuth : 355|6@0+ (2,0) [0|126] "%" EOCM_HCP1,EOCM_HCP2
 SG_ SRRSRRODPB4P_VOTk8TypCnfdAuth : 357|2@0+ (1,0) [0|3] "" EOCM_HCP1,EOCM_HCP2
 SG_ SRRSRRODPB4P_VOTk9DynPrpStsAuth : 360|1@0+ (1,0) [0|1] "" EOCM_HCP1,EOCM_HCP2
 SG_ SRRSRRODPB4P_VOTk9DynPrpAuth : 363|3@0+ (1,0) [0|4] "" EOCM_HCP1,EOCM_HCP2
 SG_ SRRSRRODPB4P_VOTk9CnfdStsAuth : 365|2@0+ (1,0) [0|3] "" EOCM_HCP1,EOCM_HCP2
 SG_ SRRSRRODPB4P_VOTk9MStsAuth : 368|2@0+ (1,0) [0|3] "" EOCM_HCP1,EOCM_HCP2
 SG_ SRRSRRODPB4P_VOTk9IDAuth : 375|7@0+ (1,0) [0|127] "" EOCM_HCP1,EOCM_HCP2
 SG_ SRRSRRODPB4P_VOTk9PoILAAuth : 382|9@0- (0.125,0) [-32|31.875] "m/s^2" EOCM_HCP1,EOCM_HCP2
 SG_ SRRSRRODPB4P_VOTk9PoILgAAuth : 389|9@0- (0.125,0) [-32|31.875] "m/s^2" EOCM_HCP1,EOCM_HCP2
 SG_ SRRSRRODPB4P_VOTk9PoILgPsAuth : 396|11@0- (0.125,0) [-128|127.875] "m" EOCM_HCP1,EOCM_HCP2
 SG_ SRRSRRODPB4P_VOTk9PoILgPsCAuth : 401|16@0+ (0.01,0) [0|655.35] "m^2" EOCM_HCP1,EOCM_HCP2
 SG_ SRRSRRODPB4P_VOTk9PoILgthAuth : 417|8@0+ (0.125,0) [0|31.875] "m" EOCM_HCP1,EOCM_HCP2
 SG_ SRRSRRODPB4P_VOTk9PoILgVAuth : 425|11@0- (0.125,0) [-128|127.875] "m/s" EOCM_HCP1,EOCM_HCP2
 SG_ SRRSRRODPB4P_VOTk9PoILgVCAuth : 446|10@0+ (0.125,0) [0|127.875] "(m/s)^2" EOCM_HCP1,EOCM_HCP2
 SG_ SRRSRRODPB4P_VOTk9PoILPsAuth : 452|10@0- (0.125,0) [-64|63.875] "m" EOCM_HCP1,EOCM_HCP2
 SG_ SRRSRRODPB4P_VOTk9PoILPsCAuth : 458|14@0+ (0.01,0) [0|163.83] "m^2" EOCM_HCP1,EOCM_HCP2
 SG_ SRRSRRODPB4P_VOTk9PoILVAuth : 476|9@0- (0.125,0) [-32|31.875] "m/s" EOCM_HCP1,EOCM_HCP2
 SG_ SRRSRRODPB4P_VOTk9PoILVCAuth : 483|10@0+ (0.125,0) [0|127.875] "(m/s)^2" EOCM_HCP1,EOCM_HCP2
 SG_ SRRSRRODPB4P_VOTk9TypCnfdAuth : 489|2@0+ (1,0) [0|3] "" EOCM_HCP1,EOCM_HCP2

BO_ 222 C8_SRRSRRODP_Consecutive_Frame03: 64 SRR_SRR
 SG_ SRRSRRODPB5P_IOTk10IDAuth : 1|7@0+ (1,0) [0|127] "" EOCM_HCP1,EOCM_HCP2
 SG_ SRRSRRODPB5P_IOTk10ElvtnAuth : 3|2@0+ (1,0) [0|3] "" EOCM_HCP1,EOCM_HCP2
 SG_ SRRSRRODPB5P_IOTk10CnfdStsAuth : 5|2@0+ (1,0) [0|3] "" EOCM_HCP1,EOCM_HCP2
 SG_ SRRSRRODPB5P_BrstID : 7|2@0+ (1,0) [0|3] "" EOCM_HCP1,EOCM_HCP2
 SG_ SRRSRRODPB5P_IOTk10PolLgPsAuth : 8|11@0- (0.125,0) [-128|127.875] "m" EOCM_HCP1,EOCM_HCP2
 SG_ SRRSRRODPB5P_IOTk10MStsAuth : 10|2@0+ (1,0) [0|3] "" EOCM_HCP1,EOCM_HCP2
 SG_ SRRSRRODPB5P_IOTk1CnfdStsAuth : 24|2@0+ (1,0) [0|3] "" EOCM_HCP1,EOCM_HCP2
 SG_ SRRSRRODPB5P_IOTk10TypCnfdAuth : 26|2@0+ (1,0) [0|3] "" EOCM_HCP1,EOCM_HCP2
 SG_ SRRSRRODPB5P_IOTk10TypAuth : 29|3@0+ (1,0) [0|5] "" EOCM_HCP1,EOCM_HCP2
 SG_ SRRSRRODPB5P_IOTk1IDAuth : 36|7@0+ (1,0) [0|127] "" EOCM_HCP1,EOCM_HCP2
 SG_ SRRSRRODPB5P_IOTk1ElvtnAuth : 38|2@0+ (1,0) [0|3] "" EOCM_HCP1,EOCM_HCP2
 SG_ SRRSRRODPB5P_IOTk1PoILgPsAuth : 43|11@0- (0.125,0) [-128|127.875] "m" EOCM_HCP1,EOCM_HCP2
 SG_ SRRSRRODPB5P_IOTk1MStsAuth : 45|2@0+ (1,0) [0|3] "" EOCM_HCP1,EOCM_HCP2
 SG_ SRRSRRODPB5P_IOTk1TypAuth : 48|3@0+ (1,0) [0|5] "" EOCM_HCP1,EOCM_HCP2
 SG_ SRRSRRODPB5P_IOTk2ElvtnAuth : 57|2@0+ (1,0) [0|3] "" EOCM_HCP1,EOCM_HCP2
 SG_ SRRSRRODPB5P_IOTk2CnfdStsAuth : 59|2@0+ (1,0) [0|3] "" EOCM_HCP1,EOCM_HCP2
 SG_ SRRSRRODPB5P_IOTk1TypCnfdAuth : 61|2@0+ (1,0) [0|3] "" EOCM_HCP1,EOCM_HCP2
 SG_ SRRSRRODPB5P_IOTk2MStsAuth : 64|2@0+ (1,0) [0|3] "" EOCM_HCP1,EOCM_HCP2
 SG_ SRRSRRODPB5P_IOTk2IDAuth : 71|7@0+ (1,0) [0|127] "" EOCM_HCP1,EOCM_HCP2
 SG_ SRRSRRODPB5P_IOTk2PolLgPsAuth : 78|11@0- (0.125,0) [-128|127.875] "m" EOCM_HCP1,EOCM_HCP2
 SG_ SRRSRRODPB5P_IOTk2TypCnfdAuth : 80|2@0+ (1,0) [0|3] "" EOCM_HCP1,EOCM_HCP2
 SG_ SRRSRRODPB5P_IOTk2TypAuth : 83|3@0+ (1,0) [0|5] "" EOCM_HCP1,EOCM_HCP2
 SG_ SRRSRRODPB5P_IOTk3IDAuth : 90|7@0+ (1,0) [0|127] "" EOCM_HCP1,EOCM_HCP2
 SG_ SRRSRRODPB5P_IOTk3ElvtnAuth : 92|2@0+ (1,0) [0|3] "" EOCM_HCP1,EOCM_HCP2
 SG_ SRRSRRODPB5P_IOTk3CnfdStsAuth : 94|2@0+ (1,0) [0|3] "" EOCM_HCP1,EOCM_HCP2
 SG_ SRRSRRODPB5P_IOTk3PolLgPsAuth : 97|11@0- (0.125,0) [-128|127.875] "m" EOCM_HCP1,EOCM_HCP2
 SG_ SRRSRRODPB5P_IOTk3MStsAuth : 99|2@0+ (1,0) [0|3] "" EOCM_HCP1,EOCM_HCP2
 SG_ SRRSRRODPB5P_IOTk4CnfdStsAuth : 113|2@0+ (1,0) [0|3] "" EOCM_HCP1,EOCM_HCP2
 SG_ SRRSRRODPB5P_IOTk3TypCnfdAuth : 115|2@0+ (1,0) [0|3] "" EOCM_HCP1,EOCM_HCP2
 SG_ SRRSRRODPB5P_IOTk3TypAuth : 118|3@0+ (1,0) [0|5] "" EOCM_HCP1,EOCM_HCP2
 SG_ SRRSRRODPB5P_IOTk4IDAuth : 125|7@0+ (1,0) [0|127] "" EOCM_HCP1,EOCM_HCP2
 SG_ SRRSRRODPB5P_IOTk4ElvtnAuth : 127|2@0+ (1,0) [0|3] "" EOCM_HCP1,EOCM_HCP2
 SG_ SRRSRRODPB5P_IOTk4PolLgPsAuth : 132|11@0- (0.125,0) [-128|127.875] "m" EOCM_HCP1,EOCM_HCP2
 SG_ SRRSRRODPB5P_IOTk4MStsAuth : 134|2@0+ (1,0) [0|3] "" EOCM_HCP1,EOCM_HCP2
 SG_ SRRSRRODPB5P_IOTk4TypAuth : 137|3@0+ (1,0) [0|5] "" EOCM_HCP1,EOCM_HCP2
 SG_ SRRSRRODPB5P_IOTk5IDAuth : 144|7@0+ (1,0) [0|127] "" EOCM_HCP1,EOCM_HCP2
 SG_ SRRSRRODPB5P_IOTk5ElvtnAuth : 146|2@0+ (1,0) [0|3] "" EOCM_HCP1,EOCM_HCP2
 SG_ SRRSRRODPB5P_IOTk5CnfdStsAuth : 148|2@0+ (1,0) [0|3] "" EOCM_HCP1,EOCM_HCP2
 SG_ SRRSRRODPB5P_IOTk4TypCnfdAuth : 150|2@0+ (1,0) [0|3] "" EOCM_HCP1,EOCM_HCP2
 SG_ SRRSRRODPB5P_IOTk5MStsAuth : 153|2@0+ (1,0) [0|3] "" EOCM_HCP1,EOCM_HCP2
 SG_ SRRSRRODPB5P_IOTk5PolLgPsAuth : 167|11@0- (0.125,0) [-128|127.875] "m" EOCM_HCP1,EOCM_HCP2
 SG_ SRRSRRODPB5P_IOTk5TypCnfdAuth : 169|2@0+ (1,0) [0|3] "" EOCM_HCP1,EOCM_HCP2
 SG_ SRRSRRODPB5P_IOTk5TypAuth : 172|3@0+ (1,0) [0|5] "" EOCM_HCP1,EOCM_HCP2
 SG_ SRRSRRODPB5P_IOTk6IDAuth : 179|7@0+ (1,0) [0|127] "" EOCM_HCP1,EOCM_HCP2
 SG_ SRRSRRODPB5P_IOTk6ElvtnAuth : 181|2@0+ (1,0) [0|3] "" EOCM_HCP1,EOCM_HCP2
 SG_ SRRSRRODPB5P_IOTk6CnfdStsAuth : 183|2@0+ (1,0) [0|3] "" EOCM_HCP1,EOCM_HCP2
 SG_ SRRSRRODPB5P_IOTk6PolLgPsAuth : 186|11@0- (0.125,0) [-128|127.875] "m" EOCM_HCP1,EOCM_HCP2
 SG_ SRRSRRODPB5P_IOTk6MStsAuth : 188|2@0+ (1,0) [0|3] "" EOCM_HCP1,EOCM_HCP2
 SG_ SRRSRRODPB5P_IOTk7ElvtnAuth : 200|2@0+ (1,0) [0|3] "" EOCM_HCP1,EOCM_HCP2
 SG_ SRRSRRODPB5P_IOTk7CnfdStsAuth : 202|2@0+ (1,0) [0|3] "" EOCM_HCP1,EOCM_HCP2
 SG_ SRRSRRODPB5P_IOTk6TypCnfdAuth : 204|2@0+ (1,0) [0|3] "" EOCM_HCP1,EOCM_HCP2
 SG_ SRRSRRODPB5P_IOTk6TypAuth : 207|3@0+ (1,0) [0|5] "" EOCM_HCP1,EOCM_HCP2
 SG_ SRRSRRODPB5P_IOTk7IDAuth : 214|7@0+ (1,0) [0|127] "" EOCM_HCP1,EOCM_HCP2
 SG_ SRRSRRODPB5P_IOTk7PolLgPsAuth : 221|11@0- (0.125,0) [-128|127.875] "m" EOCM_HCP1,EOCM_HCP2
 SG_ SRRSRRODPB5P_IOTk7MStsAuth : 223|2@0+ (1,0) [0|3] "" EOCM_HCP1,EOCM_HCP2
 SG_ SRRSRRODPB5P_IOTk7TypAuth : 226|3@0+ (1,0) [0|5] "" EOCM_HCP1,EOCM_HCP2
 SG_ SRRSRRODPB5P_IOTk8IDAuth : 233|7@0+ (1,0) [0|127] "" EOCM_HCP1,EOCM_HCP2
 SG_ SRRSRRODPB5P_IOTk8ElvtnAuth : 235|2@0+ (1,0) [0|3] "" EOCM_HCP1,EOCM_HCP2
 SG_ SRRSRRODPB5P_IOTk8CnfdStsAuth : 237|2@0+ (1,0) [0|3] "" EOCM_HCP1,EOCM_HCP2
 SG_ SRRSRRODPB5P_IOTk7TypCnfdAuth : 239|2@0+ (1,0) [0|3] "" EOCM_HCP1,EOCM_HCP2
 SG_ SRRSRRODPB5P_IOTk8PolLgPsAuth : 240|11@0- (0.125,0) [-128|127.875] "m" EOCM_HCP1,EOCM_HCP2
 SG_ SRRSRRODPB5P_IOTk8MStsAuth : 242|2@0+ (1,0) [0|3] "" EOCM_HCP1,EOCM_HCP2
 SG_ SRRSRRODPB5P_IOTk9CnfdStsAuth : 256|2@0+ (1,0) [0|3] "" EOCM_HCP1,EOCM_HCP2
 SG_ SRRSRRODPB5P_IOTk8TypCnfdAuth : 258|2@0+ (1,0) [0|3] "" EOCM_HCP1,EOCM_HCP2
 SG_ SRRSRRODPB5P_IOTk8TypAuth : 261|3@0+ (1,0) [0|5] "" EOCM_HCP1,EOCM_HCP2
 SG_ SRRSRRODPB5P_IOTk9IDAuth : 268|7@0+ (1,0) [0|127] "" EOCM_HCP1,EOCM_HCP2
 SG_ SRRSRRODPB5P_IOTk9ElvtnAuth : 270|2@0+ (1,0) [0|3] "" EOCM_HCP1,EOCM_HCP2
 SG_ SRRSRRODPB5P_IOTk9PolLgPsAuth : 275|11@0- (0.125,0) [-128|127.875] "m" EOCM_HCP1,EOCM_HCP2
 SG_ SRRSRRODPB5P_IOTk9MStsAuth : 277|2@0+ (1,0) [0|3] "" EOCM_HCP1,EOCM_HCP2
 SG_ SRRSRRODPB5P_IOTk9TypAuth : 280|3@0+ (1,0) [0|5] "" EOCM_HCP1,EOCM_HCP2
 SG_ SRRSRRODPB5P_VOTk9PoI2LgPsAuth : 291|11@0- (0.125,0) [-128|127.875] "m" EOCM_HCP1,EOCM_HCP2
 SG_ SRRSRRODPB5P_IOTk9TypCnfdAuth : 293|2@0+ (1,0) [0|3] "" EOCM_HCP1,EOCM_HCP2
 SG_ SRRSRRODPB5P_VOTk9PoI2LPsAuth : 296|10@0- (0.125,0) [-64|63.875] "m" EOCM_HCP1,EOCM_HCP2
 SG_ SRRSRRODPB5P_VOTk1PoI2LgPsAuth : 318|11@0- (0.125,0) [-128|127.875] "m" EOCM_HCP1,EOCM_HCP2
 SG_ SRRSRRODPB5P_VOTk1PoI2LPsAuth : 323|10@0- (0.125,0) [-64|63.875] "m" EOCM_HCP1,EOCM_HCP2
 SG_ SRRSRRODPB5P_VOTk2PoI2LgPsAuth : 329|11@0- (0.125,0) [-128|127.875] "m" EOCM_HCP1,EOCM_HCP2
 SG_ SRRSRRODPB5P_VOTk2PoI2LPsAuth : 350|10@0- (0.125,0) [-64|63.875] "m" EOCM_HCP1,EOCM_HCP2
 SG_ SRRSRRODPB5P_VOTk3PoI2LgPsAuth : 356|11@0- (0.125,0) [-128|127.875] "m" EOCM_HCP1,EOCM_HCP2
 SG_ SRRSRRODPB5P_VOTk3PoI2LPsAuth : 361|10@0- (0.125,0) [-64|63.875] "m" EOCM_HCP1,EOCM_HCP2
 SG_ SRRSRRODPB5P_VOTk4PoI2LgPsAuth : 383|11@0- (0.125,0) [-128|127.875] "m" EOCM_HCP1,EOCM_HCP2
 SG_ SRRSRRODPB5P_VOTk4PoI2LPsAuth : 388|10@0- (0.125,0) [-64|63.875] "m" EOCM_HCP1,EOCM_HCP2
 SG_ SRRSRRODPB5P_VOTk5Pol2LgPsAuth : 394|11@0- (0.125,0) [-128|127.875] "m" EOCM_HCP1,EOCM_HCP2
 SG_ SRRSRRODPB5P_VOTk5Pol2LPsAuth : 415|10@0- (0.125,0) [-64|63.875] "m" EOCM_HCP1,EOCM_HCP2
 SG_ SRRSRRODPB5P_VOTk6PoI2LgPsAuth : 421|11@0- (0.125,0) [-128|127.875] "m" EOCM_HCP1,EOCM_HCP2
 SG_ SRRSRRODPB5P_VOTk6PoI2LPsAuth : 426|10@0- (0.125,0) [-64|63.875] "m" EOCM_HCP1,EOCM_HCP2
 SG_ SRRSRRODPB5P_VOTk7PoI2LgPsAuth : 432|11@0- (0.125,0) [-128|127.875] "m" EOCM_HCP1,EOCM_HCP2
 SG_ SRRSRRODPB5P_VOTk7PoI2LPsAuth : 453|10@0- (0.125,0) [-64|63.875] "m" EOCM_HCP1,EOCM_HCP2
 SG_ SRRSRRODPB5P_VOTk8PoI2LgPsAuth : 459|11@0- (0.125,0) [-128|127.875] "m" EOCM_HCP1,EOCM_HCP2
 SG_ SRRSRRODPB5P_VOTk8PoI2LPsAuth : 464|10@0- (0.125,0) [-64|63.875] "m" EOCM_HCP1,EOCM_HCP2
 SG_ SRRSRRODPB5P_VOTk10PoI2LgPsAuth : 486|11@0- (0.125,0) [-128|127.875] "m" EOCM_HCP1,EOCM_HCP2
 SG_ SRRSRRODPB5P_VOTk10PoI2LPsAuth : 491|10@0- (0.125,0) [-64|63.875] "m" EOCM_HCP1,EOCM_HCP2

BO_ 218 C8_SRRSRRODP_First_Frame_PDU: 48 SRR_SRR
 SG_ SRRSRRODPB1P_MAC : 7|32@0+ (1,0) [0|4.29497e+009] "" EOCM_HCP1,EOCM_HCP2
 SG_ SRRSRRODPB1P_FCnt : 39|5@0+ (1,0) [0|31] "" EOCM_HCP1,EOCM_HCP2
 SG_ SRRSRRODPB1P_AcqTmStmAuth : 45|11@0+ (1,0) [0|2047] "ms" EOCM_HCP1,EOCM_HCP2
 SG_ SRRSRRODPB1P_BrstID : 47|2@0+ (1,0) [0|3] "" EOCM_HCP1,EOCM_HCP2
 SG_ SRRSRRODPB1P_CnstrArDtnCnfdAuth : 49|2@0+ (1,0) [0|3] "" EOCM_HCP1,EOCM_HCP2
 SG_ SRRSRRODPB1P_AcqTmStmAuth_Inv : 50|1@0+ (1,0) [0|1] "" EOCM_HCP1,EOCM_HCP2
 SG_ SRRSRRODPB1P_POTk1DynPrpAuth : 57|3@0+ (1,0) [0|4] "" EOCM_HCP1,EOCM_HCP2
 SG_ SRRSRRODPB1P_POTk1CnfdStsAuth : 59|2@0+ (1,0) [0|3] "" EOCM_HCP1,EOCM_HCP2
 SG_ SRRSRRODPB1P_MdCmdStsAuth : 61|2@0+ (1,0) [0|2] "" EOCM_HCP1,EOCM_HCP2
 SG_ SRRSRRODPB1P_CnstrArDtnStsAuth : 63|2@0+ (1,0) [0|2] "" EOCM_HCP1,EOCM_HCP2
 SG_ SRRSRRODPB1P_POTk1IDAuth : 70|7@0+ (1,0) [0|127] "" EOCM_HCP1,EOCM_HCP2
 SG_ SRRSRRODPB1P_POTk1MStsAuth : 73|2@0+ (1,0) [0|3] "" EOCM_HCP1,EOCM_HCP2
 SG_ SRRSRRODPB1P_POTk1InPthPotAuth : 79|6@0+ (2,0) [0|126] "%" EOCM_HCP1,EOCM_HCP2
 SG_ SRRSRRODPB1P_POTk1PoILAAuth : 87|9@0- (0.125,0) [-32|31.875] "m/s^2" EOCM_HCP1,EOCM_HCP2
 SG_ SRRSRRODPB1P_POTk1PoILgAAuth : 94|9@0- (0.125,0) [-32|31.875] "m/s^2" EOCM_HCP1,EOCM_HCP2
 SG_ SRRSRRODPB1P_POTk1PoILgPsAuth : 101|11@0- (0.125,0) [-128|127.875] "m" EOCM_HCP1,EOCM_HCP2
 SG_ SRRSRRODPB1P_POTk1PoILgVAuth : 106|10@0- (0.125,0) [-64|63.875] "m/s" EOCM_HCP1,EOCM_HCP2
 SG_ SRRSRRODPB1P_POTk1PoILPsAuth : 112|10@0- (0.125,0) [-64|63.875] "m" EOCM_HCP1,EOCM_HCP2
 SG_ SRRSRRODPB1P_POTk1PoILVAuth : 134|9@0- (0.125,0) [-32|31.875] "m/s" EOCM_HCP1,EOCM_HCP2
 SG_ SRRSRRODPB1P_POTk2CnfdStsAuth : 137|2@0+ (1,0) [0|3] "" EOCM_HCP1,EOCM_HCP2
 SG_ SRRSRRODPB1P_POTk1TypCnfdAuth : 139|2@0+ (1,0) [0|3] "" EOCM_HCP1,EOCM_HCP2
 SG_ SRRSRRODPB1P_POTk1TypAuth : 141|2@0+ (1,0) [0|2] "" EOCM_HCP1,EOCM_HCP2
 SG_ SRRSRRODPB1P_POTk2IDAuth : 148|7@0+ (1,0) [0|127] "" EOCM_HCP1,EOCM_HCP2
 SG_ SRRSRRODPB1P_POTk2DynPrpAuth : 151|3@0+ (1,0) [0|4] "" EOCM_HCP1,EOCM_HCP2
 SG_ SRRSRRODPB1P_POTk2InPthPotAuth : 157|6@0+ (2,0) [0|126] "%" EOCM_HCP1,EOCM_HCP2
 SG_ SRRSRRODPB1P_POTk2PoILAAuth : 165|9@0- (0.125,0) [-32|31.875] "m/s^2" EOCM_HCP1,EOCM_HCP2
 SG_ SRRSRRODPB1P_POTk2MStsAuth : 167|2@0+ (1,0) [0|3] "" EOCM_HCP1,EOCM_HCP2
 SG_ SRRSRRODPB1P_POTk2PoILgAAuth : 172|9@0- (0.125,0) [-32|31.875] "m/s^2" EOCM_HCP1,EOCM_HCP2
 SG_ SRRSRRODPB1P_POTk2PoILgPsAuth : 179|11@0- (0.125,0) [-128|127.875] "m" EOCM_HCP1,EOCM_HCP2
 SG_ SRRSRRODPB1P_POTk2PoILgVAuth : 184|10@0- (0.125,0) [-64|63.875] "m/s" EOCM_HCP1,EOCM_HCP2
 SG_ SRRSRRODPB1P_POTk2PoILPsAuth : 206|10@0- (0.125,0) [-64|63.875] "m" EOCM_HCP1,EOCM_HCP2
 SG_ SRRSRRODPB1P_POTk2PoILVAuth : 212|9@0- (0.125,0) [-32|31.875] "m/s" EOCM_HCP1,EOCM_HCP2
 SG_ SRRSRRODPB1P_POTk2TypCnfdAuth : 217|2@0+ (1,0) [0|3] "" EOCM_HCP1,EOCM_HCP2
 SG_ SRRSRRODPB1P_POTk2TypAuth : 219|2@0+ (1,0) [0|2] "" EOCM_HCP1,EOCM_HCP2
 SG_ SRRSRRODPB1P_SnsrUnvAuth : 224|1@0+ (1,0) [0|1] "" EOCM_HCP1,EOCM_HCP2
 SG_ SRRSRRODPB1P_SnsrBlckdAuth : 225|1@0+ (1,0) [0|1] "" EOCM_HCP1,EOCM_HCP2
 SG_ SRRSRRODPB1P_ServRqrdAuth : 226|1@0+ (1,0) [0|1] "" EOCM_HCP1,EOCM_HCP2
 SG_ SRRSRRODPB1P_RdTypCnfdAuth : 228|2@0+ (1,0) [0|3] "" EOCM_HCP1,EOCM_HCP2
 SG_ SRRSRRODPB1P_RdTypAuth : 231|3@0+ (1,0) [0|7] "" EOCM_HCP1,EOCM_HCP2
 SG_ SRRSRRODPB1P_VOTk1CICOPotAuth : 237|6@0+ (2,0) [0|126] "%" EOCM_HCP1,EOCM_HCP2
 SG_ SRRSRRODPB1P_SwpBndwdthStsAuth : 239|2@0+ (1,0) [0|3] "" EOCM_HCP1,EOCM_HCP2
 SG_ SRRSRRODPB1P_VOTk1IDAuth : 241|7@0+ (1,0) [0|127] "" EOCM_HCP1,EOCM_HCP2
 SG_ SRRSRRODPB1P_VOTk1DynPrpStsAuth : 242|1@0+ (1,0) [0|1] "" EOCM_HCP1,EOCM_HCP2
 SG_ SRRSRRODPB1P_VOTk1DynPrpAuth : 245|3@0+ (1,0) [0|4] "" EOCM_HCP1,EOCM_HCP2
 SG_ SRRSRRODPB1P_VOTk1CnfdStsAuth : 247|2@0+ (1,0) [0|3] "" EOCM_HCP1,EOCM_HCP2
 SG_ SRRSRRODPB1P_VOTk1PoILAAuth : 248|9@0- (0.125,0) [-32|31.875] "m/s^2" EOCM_HCP1,EOCM_HCP2
 SG_ SRRSRRODPB1P_VOTk1MStsAuth : 250|2@0+ (1,0) [0|3] "" EOCM_HCP1,EOCM_HCP2
 SG_ SRRSRRODPB1P_VOTk1PoILgAAuth : 271|9@0- (0.125,0) [-32|31.875] "m/s^2" EOCM_HCP1,EOCM_HCP2
 SG_ SRRSRRODPB1P_VOTk1PoILgPsAuth : 278|11@0- (0.125,0) [-128|127.875] "m" EOCM_HCP1,EOCM_HCP2
 SG_ SRRSRRODPB1P_VOTk1PoILgPsCAuth : 283|16@0+ (0.01,0) [0|655.35] "m^2" EOCM_HCP1,EOCM_HCP2
 SG_ SRRSRRODPB1P_VOTk1PoILgthAuth : 299|8@0+ (0.125,0) [0|31.875] "m" EOCM_HCP1,EOCM_HCP2
 SG_ SRRSRRODPB1P_VOTk1PoILgVAuth : 307|11@0- (0.125,0) [-128|127.875] "m/s" EOCM_HCP1,EOCM_HCP2
 SG_ SRRSRRODPB1P_VOTk1PoILgVCAuth : 312|10@0+ (0.125,0) [0|127.875] "(m/s)^2" EOCM_HCP1,EOCM_HCP2
 SG_ SRRSRRODPB1P_VOTk1PoILPsAuth : 334|10@0- (0.125,0) [-64|63.875] "m" EOCM_HCP1,EOCM_HCP2
 SG_ SRRSRRODPB1P_VOTk1PoILPsCAuth : 340|14@0+ (0.01,0) [0|163.83] "m^2" EOCM_HCP1,EOCM_HCP2
 SG_ SRRSRRODPB1P_VOTk1PoILVAuth : 358|9@0- (0.125,0) [-32|31.875] "m/s" EOCM_HCP1,EOCM_HCP2
 SG_ SRRSRRODPB1P_VOTk1PoILVCAuth : 365|10@0+ (0.125,0) [0|127.875] "(m/s)^2" EOCM_HCP1,EOCM_HCP2
 SG_ SRRSRRODPB1P_VOTk2PoILgthAuth : 369|8@0+ (0.125,0) [0|31.875] "m" EOCM_HCP1,EOCM_HCP2
 SG_ SRRSRRODPB1P_VOTk1TypCnfdAuth : 371|2@0+ (1,0) [0|3] "" EOCM_HCP1,EOCM_HCP2
 SG_ SRRSRRODPB1P_ARC : 377|2@0+ (1,0) [0|3] "" EOCM_HCP1,EOCM_HCP2

BO_ 223 C8_SRRSRRODP_Last_Frame_PDU: 48 SRR_SRR
 SG_ SRRSRRODPB6P_IOTk10PolLPsAuth : 5|10@0- (0.125,0) [-64|63.875] "m" EOCM_HCP1,EOCM_HCP2
 SG_ SRRSRRODPB6P_BrstID : 7|2@0+ (1,0) [0|3] "" EOCM_HCP1,EOCM_HCP2
 SG_ SRRSRRODPB6P_IOTk1PoILPsAuth : 11|10@0- (0.125,0) [-64|63.875] "m" EOCM_HCP1,EOCM_HCP2
 SG_ SRRSRRODPB6P_IOTk2PolLPsAuth : 17|10@0- (0.125,0) [-64|63.875] "m" EOCM_HCP1,EOCM_HCP2
 SG_ SRRSRRODPB6P_IOTk3PolLPsAuth : 39|10@0- (0.125,0) [-64|63.875] "m" EOCM_HCP1,EOCM_HCP2
 SG_ SRRSRRODPB6P_IOTk4PolLPsAuth : 45|10@0- (0.125,0) [-64|63.875] "m" EOCM_HCP1,EOCM_HCP2
 SG_ SRRSRRODPB6P_IOTk5PolLPsAuth : 51|10@0- (0.125,0) [-64|63.875] "m" EOCM_HCP1,EOCM_HCP2
 SG_ SRRSRRODPB6P_IOTk6PolLPsAuth : 57|10@0- (0.125,0) [-64|63.875] "m" EOCM_HCP1,EOCM_HCP2
 SG_ SRRSRRODPB6P_IOTk7PolLPsAuth : 79|10@0- (0.125,0) [-64|63.875] "m" EOCM_HCP1,EOCM_HCP2
 SG_ SRRSRRODPB6P_IOTk8PolLPsAuth : 85|10@0- (0.125,0) [-64|63.875] "m" EOCM_HCP1,EOCM_HCP2
 SG_ SRRSRRODPB6P_IOTk9PolLPsAuth : 91|10@0- (0.125,0) [-64|63.875] "m" EOCM_HCP1,EOCM_HCP2
 SG_ SRRSRRODPB6P_REOTk1CnfdStsAuth : 97|2@0+ (1,0) [0|3] "" EOCM_HCP1,EOCM_HCP2
 SG_ SRRSRRODPB6P_REOTk1CrvAuth : 111|16@0- (9.77e-07,0) [-0.0320143|0.0320134] "1/m" EOCM_HCP1,EOCM_HCP2
 SG_ SRRSRRODPB6P_REOTk1CrvDrvtAuth : 127|16@0- (3.73e-09,0) [-0.000122225|0.000122221] "1/m2" EOCM_HCP1,EOCM_HCP2
 SG_ SRRSRRODPB6P_REOTk1HdgAuth : 143|10@0- (0.000977,0) [-0.500224|0.499247] "rad" EOCM_HCP1,EOCM_HCP2
 SG_ SRRSRRODPB6P_REOTk1OfstAuth : 149|9@0- (0.125,0) [-32|31.875] "m" EOCM_HCP1,EOCM_HCP2
 SG_ SRRSRRODPB6P_REOTk1PsEndAuth : 156|11@0- (0.125,0) [-128|127.875] "m" EOCM_HCP1,EOCM_HCP2
 SG_ SRRSRRODPB6P_REOTk1PsStrtAuth : 161|11@0- (0.125,0) [-128|127.875] "m" EOCM_HCP1,EOCM_HCP2
 SG_ SRRSRRODPB6P_REOTk2CnfdStsAuth : 177|2@0+ (1,0) [0|3] "" EOCM_HCP1,EOCM_HCP2
 SG_ SRRSRRODPB6P_REOTk1TypCnfdAuth : 179|2@0+ (1,0) [0|3] "" EOCM_HCP1,EOCM_HCP2
 SG_ SRRSRRODPB6P_REOTk1TypAuth : 182|3@0+ (1,0) [0|5] "" EOCM_HCP1,EOCM_HCP2
 SG_ SRRSRRODPB6P_REOTk2CrvAuth : 191|16@0- (9.77e-07,0) [-0.0320143|0.0320134] "1/m" EOCM_HCP1,EOCM_HCP2
 SG_ SRRSRRODPB6P_REOTk2CrvDrvtAuth : 207|16@0- (3.73e-09,0) [-0.000122225|0.000122221] "1/m2" EOCM_HCP1,EOCM_HCP2
 SG_ SRRSRRODPB6P_REOTk2HdgAuth : 223|10@0- (0.000977,0) [-0.500224|0.499247] "rad" EOCM_HCP1,EOCM_HCP2
 SG_ SRRSRRODPB6P_REOTk2OfstAuth : 229|9@0- (0.125,0) [-32|31.875] "m" EOCM_HCP1,EOCM_HCP2
 SG_ SRRSRRODPB6P_REOTk2PsEndAuth : 236|11@0- (0.125,0) [-128|127.875] "m" EOCM_HCP1,EOCM_HCP2
 SG_ SRRSRRODPB6P_REOTk2PsStrtAuth : 241|11@0- (0.125,0) [-128|127.875] "m" EOCM_HCP1,EOCM_HCP2
 SG_ SRRSRRODPB6P_REOTk3CnfdStsAuth : 257|2@0+ (1,0) [0|3] "" EOCM_HCP1,EOCM_HCP2
 SG_ SRRSRRODPB6P_REOTk2TypCnfdAuth : 259|2@0+ (1,0) [0|3] "" EOCM_HCP1,EOCM_HCP2
 SG_ SRRSRRODPB6P_REOTk2TypAuth : 262|3@0+ (1,0) [0|5] "" EOCM_HCP1,EOCM_HCP2
 SG_ SRRSRRODPB6P_REOTk3CrvAuth : 271|16@0- (9.77e-07,0) [-0.0320143|0.0320134] "1/m" EOCM_HCP1,EOCM_HCP2
 SG_ SRRSRRODPB6P_REOTk3CrvDrvtAuth : 287|16@0- (3.73e-09,0) [-0.000122225|0.000122221] "1/m2" EOCM_HCP1,EOCM_HCP2
 SG_ SRRSRRODPB6P_REOTk3HdgAuth : 303|10@0- (0.000977,0) [-0.500224|0.499247] "rad" EOCM_HCP1,EOCM_HCP2
 SG_ SRRSRRODPB6P_REOTk3OfstAuth : 309|9@0- (0.125,0) [-32|31.875] "m" EOCM_HCP1,EOCM_HCP2
 SG_ SRRSRRODPB6P_REOTk3PsEndAuth : 316|11@0- (0.125,0) [-128|127.875] "m" EOCM_HCP1,EOCM_HCP2
 SG_ SRRSRRODPB6P_REOTk3PsStrtAuth : 321|11@0- (0.125,0) [-128|127.875] "m" EOCM_HCP1,EOCM_HCP2
 SG_ SRRSRRODPB6P_REOTk3TypCnfdAuth : 339|2@0+ (1,0) [0|3] "" EOCM_HCP1,EOCM_HCP2
 SG_ SRRSRRODPB6P_REOTk3TypAuth : 342|3@0+ (1,0) [0|5] "" EOCM_HCP1,EOCM_HCP2

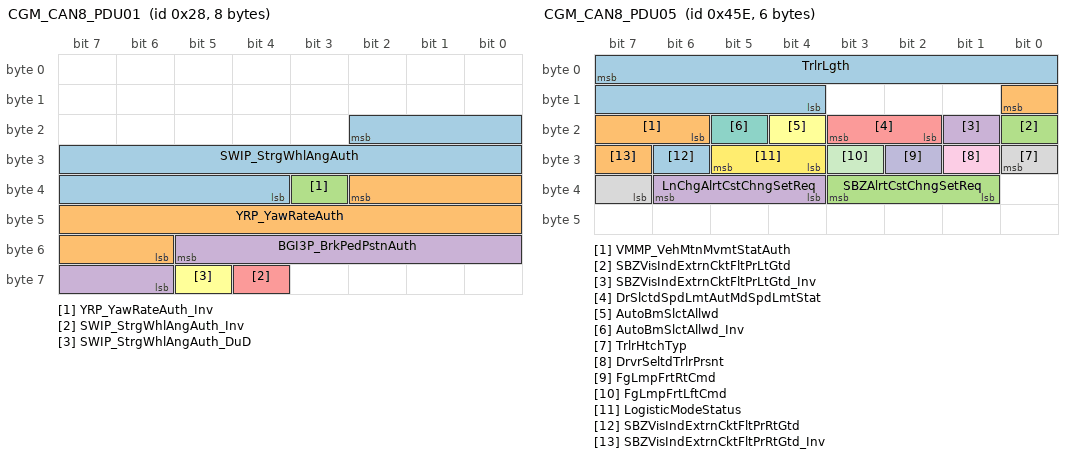
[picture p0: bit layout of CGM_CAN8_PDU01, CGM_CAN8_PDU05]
BO_ 40 CGM_CAN8_PDU01: 8 CGM
 SG_ SWIP_StrgWhlAngAuth : 18|15@0- (0.0625,0) [-1024|1023.94] "deg" FCM_LC,SRR_LR_CR,SRR_RR,SRR_SLR,SRR_SRR
 SG_ YRP_YawRateAuth : 34|13@0- (0.024,0) [-98.304|98.28] "Deg/Sec" FCM_LC,SRR_LR_CR,SRR_RR,SRR_SLR,SRR_SRR
 SG_ YRP_YawRateAuth_Inv : 35|1@0+ (1,0) [0|1] "" FCM_LC,SRR_LR_CR,SRR_RR
 SG_ BGI3P_BrkPedPstnAuth : 53|8@0+ (0.392157,0) [0|100] "%" FCM_LC
 SG_ SWIP_StrgWhlAngAuth_Inv : 60|1@0+ (1,0) [0|1] "" FCM_LC
 SG_ SWIP_StrgWhlAngAuth_DuD : 61|1@0+ (1,0) [0|1] "" FCM_LC

BO_ 607 CGM_CAN8_PDU02: 6 CGM
 SG_ DRCDNDP_DRCAvgDrvnAuth : 23|13@0+ (0.125,0) [0|1023.88] "m" SRR_LR_CR,SRR_RR,SRR_SLR,SRR_SRR
 SG_ DRCDNDP_DRCAvgDrvnAuth_Inv : 26|1@0+ (1,0) [0|1] "" SRR_LR_CR,SRR_RR,SRR_SLR,SRR_SRR

BO_ 1116 CGM_CAN8_PDU03: 16 CGM
 SG_ TmSyncMsg : 7|40@0+ (100,0) [0|1.09951e+014] "ms" EOCM_HCP2,FCM_LC,HDLM,LRR,LRR_HC,SRR_LF,SRR_LR_CR,SRR_RF,SRR_RR,SRR_SLR,SRR_SRR
 SG_ VODVP_VehOdoDispValAuth : 47|28@0+ (0.015625,0) [0|4.1943e+006] "km" FCM_LC,LRR,SRR_LF,SRR_LR_CR,SRR_RF,SRR_RR,SRR_SLR,SRR_SRR
 SG_ CldrYr : 67|8@0+ (1,2000) [2000|2255] "year" FCM_LC
 SG_ OATP_OtsAirTmpCrValAuth : 75|8@0+ (0.5,-40) [-40|87.5] "Deg C" FCM_LC,LRR,SRR_LF,SRR_LR_CR,SRR_RF,SRR_RR,SRR_SLR,SRR_SRR
 SG_ MinOfHr : 83|6@0+ (1,0) [0|63] "minutes" FCM_LC
 SG_ SecOfMin : 93|6@0+ (1,0) [0|63] "seconds" FCM_LC
 SG_ HrOfDay : 98|5@0+ (1,0) [0|31] "hour" FCM_LC
 SG_ CldrDay : 103|5@0+ (1,0) [0|31] "day" FCM_LC
 SG_ VODVP_VehOdoDispValAuth_Inv : 104|1@0+ (1,0) [0|1] "" FCM_LC
 SG_ OATP_OtsAirTmpCrValAuth_Inv : 105|1@0+ (1,0) [0|1] "" FCM_LC,LRR
 SG_ CldrMth : 109|4@0+ (1,0) [0|12] "" FCM_LC

BO_ 1117 CGM_CAN8_PDU04: 6 CGM
 SG_ ELWWIP_WprFrtFtrReqAuth : 7|4@0+ (1,0) [0|12] "" FCM_LC,LRR,SRR_LF,SRR_LR_CR,SRR_RF,SRR_RR,SRR_SLR,SRR_SRR

BO_ 1118 CGM_CAN8_PDU05: 6 CGM
 SG_ TrlrLgth : 7|12@0+ (1,0) [0|4095] "cm" SRR_LR_CR,SRR_RR,SRR_SLR,SRR_SRR
 SG_ VMMP_VehMtnMvmtStatAuth : 8|3@0+ (1,0) [0|4] "" FCM_LC,SRR_LR_CR,SRR_RR,SRR_SLR,SRR_SRR
 SG_ SBZVisIndExtrnCktFltPrLtGtd : 16|1@0+ (1,0) [0|1] "" SRR_SLR
 SG_ SBZVisIndExtrnCktFltPrLtGtd_Inv : 17|1@0+ (1,0) [0|1] "" SRR_SLR
 SG_ DrSlctdSpdLmtAutMdSpdLmtStat : 19|2@0+ (1,0) [0|3] "" FCM_LC
 SG_ AutoBmSlctAllwd : 20|1@0+ (1,0) [0|1] "" FCM_LC
 SG_ AutoBmSlctAllwd_Inv : 21|1@0+ (1,0) [0|1] "" FCM_LC
 SG_ TrlrHtchTyp : 24|2@0+ (1,0) [0|3] "" SRR_LR_CR,SRR_RR,SRR_SLR,SRR_SRR
 SG_ DrvrSeltdTrlrPrsnt : 25|1@0+ (1,0) [0|1] "" SRR_LR_CR,SRR_RR,SRR_SLR,SRR_SRR
 SG_ FgLmpFrtRtCmd : 26|1@0+ (1,0) [0|1] "" FCM_LC
 SG_ FgLmpFrtLftCmd : 27|1@0+ (1,0) [0|1] "" FCM_LC
 SG_ LogisticModeStatus : 29|2@0+ (1,0) [0|3] "" HDLM
 SG_ SBZVisIndExtrnCktFltPrRtGtd : 30|1@0+ (1,0) [0|1] "" SRR_SRR
 SG_ SBZVisIndExtrnCktFltPrRtGtd_Inv : 31|1@0+ (1,0) [0|1] "" SRR_SRR
 SG_ SBZAlrtCstChngSetReq : 35|3@0+ (1,0) [0|7] "" SRR_SLR
 SG_ LnChgAlrtCstChngSetReq : 38|3@0+ (1,0) [0|7] "" SRR_SLR

BO_ 1121 CGM_CAN8_PDU06: 6 CGM
 SG_ APASP_APAStsAuth : 2|3@0+ (1,0) [0|7] "" Vector__XXX
 SG_ HSP_DrvAlrtTypCstCurrSetValAuth : 5|3@0+ (1,0) [0|2] "" SRR_SLR,SRR_SRR
 SG_ HSP_HptcStOprtlStsAuth : 7|2@0+ (1,0) [0|2] "" SRR_SLR,SRR_SRR
 SG_ TrffcLgtAsstCstChgSetReq : 9|3@0+ (1,0) [0|7] "" FCM_LC
 SG_ RrCrsTrfcAlrtCstChngSetReq : 12|3@0+ (1,0) [0|7] "" SRR_SLR
 SG_ GlrFrHgBmRspTypCstChgSetReq : 15|3@0+ (1,0) [0|7] "" FCM_LC
 SG_ TSMWrngPopUpSts : 16|1@0+ (1,0) [0|1] "" FCM_LC
 SG_ TSMSgnNtfnWrnDispd : 17|1@0+ (1,0) [0|1] "" FCM_LC
 SG_ TSMPageDispActv : 18|1@0+ (1,0) [0|1] "" FCM_LC
 SG_ TSMCustRstReq : 19|1@0+ (1,0) [0|1] "" FCM_LC
 SG_ RstrCstDfltReq : 20|1@0+ (1,0) [0|1] "" FCM_LC,SRR_SLR
 SG_ DispMeasSysExtnd : 22|2@0+ (1,0) [0|3] "" FCM_LC
 SG_ BGI1P_OutsdAmbtLgtLvlStsAuth : 24|2@0+ (1,0) [0|2] "" FCM_LC
 SG_ LowBmAct : 25|1@0+ (1,0) [0|1] "" FCM_LC
 SG_ HighBmAct : 26|1@0+ (1,0) [0|1] "" FCM_LC
 SG_ TrnSigSwRtActv : 27|1@0+ (1,0) [0|1] "" FCM_LC,SRR_SRR
 SG_ TrnSigSwLtActv : 28|1@0+ (1,0) [0|1] "" FCM_LC,SRR_SLR
 SG_ TrlrConnStat : 29|1@0+ (1,0) [0|1] "" FCM_LC,SRR_LR_CR,SRR_RR,SRR_SLR,SRR_SRR
 SG_ TimeDispFormat : 30|1@0+ (1,0) [0|1] "" FCM_LC
 SG_ TDAP_TeenDrvrActvAuth : 31|1@0+ (1,0) [0|1] "" FCM_LC,SRR_SLR
 SG_ RrCrsTrfcBrkgSysSts : 35|2@0+ (1,0) [0|2] "" SRR_SLR
 SG_ TDAP_DrvrIdfrAuth : 38|3@0+ (1,0) [0|7] "" FCM_LC

BO_ 608 CGM_CAN8_PDU08: 6 CGM
 SG_ VSANDP_VehSpdAvgNDrvnAuth : 7|15@0+ (0.015625,0) [0|511.984] "Km/h" FCM_LC

BO_ 609 CGM_CAN8_PDU09: 6 CGM
 SG_ BkUpPwrMdRnCrnkOutSt : 1|1@0+ (1,0) [0|1] "" FCM_LC,LRR,SRR_LF,SRR_LR_CR,SRR_RF,SRR_RR

BO_ 325 CGM_NM_PDU_On_CAN_8_Cluster: 8 CGM
 SG_ ISignal_CGM_CAN_8_Cluster : 23|48@0+ (1,0) [0|281474976710655] "" EOCM,EOCM_HCP1,EOCM_HCP2,FCM_LC,HDLM,LRR,LRR_HC,SRR_LF,SRR_LR_CR,SRR_RF,SRR_RR,SRR_SLR,SRR_SRR

BA_DEF_ SG_  "SignalType" STRING ;
BA_DEF_ SG_  "SignalLongName" STRING ;
BA_DEF_ BO_  "GenMsgCycleTime" INT 0 10000;
BA_DEF_ BO_  "GenMsgSendType" ENUM "cyclicX","spontanX","cyclicIfActiveX","spontanWithDelay","cyclicAndSpontanX","cyclicAndSpontanWithDelay","spontanWithRepetition","cyclicIfActiveAndSpontanWD";
BA_DEF_ BO_  "VFrameFormat" ENUM  "StandardCAN","ExtendedCAN","reserved","reserved","reserved","reserved","reserved","reserved","reserved","reserved","reserved","reserved","reserved","reserved","StandardCAN_FD","ExtendedCAN_FD";
BA_DEF_DEF_  "SignalType" "";
BA_DEF_DEF_  "SignalLongName" "";
BA_DEF_DEF_  "GenMsgCycleTime" 0;
BA_DEF_DEF_  "GenMsgSendType" "cyclicX";
BA_DEF_DEF_  "VFrameFormat" "StandardCAN";
BA_ "VFrameFormat" BO_ 212 14;
BA_ "VFrameFormat" BO_ 217 14;
BA_ "VFrameFormat" BO_ 219 14;
BA_ "VFrameFormat" BO_ 220 14;
BA_ "VFrameFormat" BO_ 221 14;
BA_ "VFrameFormat" BO_ 222 14;
BA_ "VFrameFormat" BO_ 218 14;
BA_ "VFrameFormat" BO_ 223 14;
BA_ "GenMsgCycleTime" BO_ 40 10;
BA_ "VFrameFormat" BO_ 40 14;
BA_ "GenMsgCycleTime" BO_ 607 100;
BA_ "VFrameFormat" BO_ 607 14;
BA_ "GenMsgCycleTime" BO_ 1116 1000;
BA_ "VFrameFormat" BO_ 1116 14;
BA_ "GenMsgCycleTime" BO_ 1117 1000;
BA_ "VFrameFormat" BO_ 1117 14;
BA_ "GenMsgCycleTime" BO_ 1118 1000;
BA_ "VFrameFormat" BO_ 1118 14;
BA_ "GenMsgCycleTime" BO_ 1121 1000;
BA_ "VFrameFormat" BO_ 1121 14;
BA_ "GenMsgCycleTime" BO_ 608 250;
BA_ "VFrameFormat" BO_ 608 14;
BA_ "GenMsgCycleTime" BO_ 609 250;
BA_ "VFrameFormat" BO_ 609 14;
BA_ "SignalLongName" SG_ 212 SRRSLRODPB1P_MAC "Short Range Radar Side Left Rear Object Detection and Processing Burst 1 Protected : MAC";
BA_ "SignalLongName" SG_ 212 SRRSLRODPB1P_FCnt "Short Range Radar Side Left Rear Object Detection and Processing Burst 1 Protected : Freshness Counter";
BA_ "SignalLongName" SG_ 212 SRRSLRODPB1P_AcqTmStmAuth "Short Range Radar Side Left Rear Object Detection and Processing Burst 1 Protected : Acquisition Time Stamp Authenticated";
BA_ "SignalLongName" SG_ 212 SRRSLRODPB1P_BrstID "Short Range Radar Side Left Rear Object Detection and Processing Burst 1 Protected : Burst ID";
BA_ "SignalType" SG_ 212 SRRSLRODPB1P_CnstrArDtnCnfdAuth "ENM";
BA_ "SignalLongName" SG_ 212 SRRSLRODPB1P_CnstrArDtnCnfdAuth "Short Range Radar Side Left Rear Object Detection and Processing Burst 1 Protected : Construction Area Detection Confidence Authenticated";
BA_ "SignalType" SG_ 212 SRRSLRODPB1P_AcqTmStmAuth_Inv "ENM";
BA_ "SignalLongName" SG_ 212 SRRSLRODPB1P_AcqTmStmAuth_Inv "Short Range Radar Side Left Rear Object Detection and Processing Burst 1 Protected : Acquisition Time Stamp Authenticated Invalid";
BA_ "SignalType" SG_ 212 SRRSLRODPB1P_POTk1DynPrpAuth "ENM";
BA_ "SignalLongName" SG_ 212 SRRSLRODPB1P_POTk1DynPrpAuth "Short Range Radar Side Left Rear Object Detection and Processing Burst 1 Protected : Pedestrian Object Track 1 Dynamic Property Authenticated";
BA_ "SignalType" SG_ 212 SRRSLRODPB1P_POTk1CnfdStsAuth "ENM";
BA_ "SignalLongName" SG_ 212 SRRSLRODPB1P_POTk1CnfdStsAuth "Short Range Radar Side Left Rear Object Detection and Processing Burst 1 Protected : Pedestrian Object Track 1 Confidence Status Authenticated";
BA_ "SignalType" SG_ 212 SRRSLRODPB1P_MdCmdStsAuth "ENM";
BA_ "SignalLongName" SG_ 212 SRRSLRODPB1P_MdCmdStsAuth "Short Range Radar Side Left Rear Object Detection and Processing Burst 1 Protected : Mode Command Status Authenticated";
BA_ "SignalType" SG_ 212 SRRSLRODPB1P_CnstrArDtnStsAuth "ENM";
BA_ "SignalLongName" SG_ 212 SRRSLRODPB1P_CnstrArDtnStsAuth "Short Range Radar Side Left Rear Object Detection and Processing Burst 1 Protected : Construction Area Detection Status Authenticated";
BA_ "SignalLongName" SG_ 212 SRRSLRODPB1P_POTk1IDAuth "Short Range Radar Side Left Rear Object Detection and Processing Burst 1 Protected : Pedestrian Object Track 1 ID Authenticated";
BA_ "SignalType" SG_ 212 SRRSLRODPB1P_POTk1MStsAuth "ENM";
BA_ "SignalLongName" SG_ 212 SRRSLRODPB1P_POTk1MStsAuth "Short Range Radar Side Left Rear Object Detection and Processing Burst 1 Protected : Pedestrian Object Track 1 Measurement Status Authenticated";
BA_ "SignalLongName" SG_ 212 SRRSLRODPB1P_POTk1InPthPotAuth "Short Range Radar Side Left Rear Object Detection and Processing Burst 1 Protected : Pedestrian Object Track 1 In Path Potential Authenticated";
BA_ "SignalLongName" SG_ 212 SRRSLRODPB1P_POTk1PoILAAuth "Short Range Radar Side Left Rear Object Detection and Processing Burst 1 Protected : Pedestrian Object Track 1 Point of Interest Lateral Acceleration Authenticated";
BA_ "SignalLongName" SG_ 212 SRRSLRODPB1P_POTk1PoILgAAuth "Short Range Radar Side Left Rear Object Detection and Processing Burst 1 Protected : Pedestrian Object Track 1 Point of Interest Longitudinal Acceleration Authenticated";
BA_ "SignalLongName" SG_ 212 SRRSLRODPB1P_POTk1PoILgPsAuth "Short Range Radar Side Left Rear Object Detection and Processing Burst 1 Protected : Pedestrian Object Track 1 Point of Interest Longitudinal Position Authenticated";
BA_ "SignalLongName" SG_ 212 SRRSLRODPB1P_POTk1PoILgVAuth "Short Range Radar Side Left Rear Object Detection and Processing Burst 1 Protected : Pedestrian Object Track 1 Point of Interest Longitudinal Velocity Authenticated";
BA_ "SignalLongName" SG_ 212 SRRSLRODPB1P_POTk1PoILPsAuth "Short Range Radar Side Left Rear Object Detection and Processing Burst 1 Protected : Pedestrian Object Track 1 Point of Interest Lateral Position Authenticated";
BA_ "SignalLongName" SG_ 212 SRRSLRODPB1P_POTk1PoILVAuth "Short Range Radar Side Left Rear Object Detection and Processing Burst 1 Protected : Pedestrian Object Track 1 Point of Interest Lateral Velocity Authenticated";
BA_ "SignalType" SG_ 212 SRRSLRODPB1P_POTk2CnfdStsAuth "ENM";
BA_ "SignalLongName" SG_ 212 SRRSLRODPB1P_POTk2CnfdStsAuth "Short Range Radar Side Left Rear Object Detection and Processing Burst 1 Protected : Pedestrian Object Track 2 Confidence Status Authenticated";
BA_ "SignalType" SG_ 212 SRRSLRODPB1P_POTk1TypCnfdAuth "ENM";
BA_ "SignalLongName" SG_ 212 SRRSLRODPB1P_POTk1TypCnfdAuth "Short Range Radar Side Left Rear Object Detection and Processing Burst 1 Protected : Pedestrian Object Track 1 Type Confidence Authenticated";
BA_ "SignalType" SG_ 212 SRRSLRODPB1P_POTk1TypAuth "ENM";
BA_ "SignalLongName" SG_ 212 SRRSLRODPB1P_POTk1TypAuth "Short Range Radar Side Left Rear Object Detection and Processing Burst 1 Protected : Pedestrian Object Track 1 Type Authenticated";
BA_ "SignalLongName" SG_ 212 SRRSLRODPB1P_POTk2IDAuth "Short Range Radar Side Left Rear Object Detection and Processing Burst 1 Protected : Pedestrian Object Track 2 ID Authenticated";
BA_ "SignalType" SG_ 212 SRRSLRODPB1P_POTk2DynPrpAuth "ENM";
BA_ "SignalLongName" SG_ 212 SRRSLRODPB1P_POTk2DynPrpAuth "Short Range Radar Side Left Rear Object Detection and Processing Burst 1 Protected : Pedestrian Object Track 2 Dynamic Property Authenticated";
BA_ "SignalLongName" SG_ 212 SRRSLRODPB1P_POTk2InPthPotAuth "Short Range Radar Side Left Rear Object Detection and Processing Burst 1 Protected : Pedestrian Object Track 2 In Path Potential Authenticated";
BA_ "SignalLongName" SG_ 212 SRRSLRODPB1P_POTk2PoILAAuth "Short Range Radar Side Left Rear Object Detection and Processing Burst 1 Protected : Pedestrian Object Track 2 Point of Interest Lateral Acceleration Authenticated";
BA_ "SignalType" SG_ 212 SRRSLRODPB1P_POTk2MStsAuth "ENM";
BA_ "SignalLongName" SG_ 212 SRRSLRODPB1P_POTk2MStsAuth "Short Range Radar Side Left Rear Object Detection and Processing Burst 1 Protected : Pedestrian Object Track 2 Measurement Status Authenticated";
BA_ "SignalLongName" SG_ 212 SRRSLRODPB1P_POTk2PoILgAAuth "Short Range Radar Side Left Rear Object Detection and Processing Burst 1 Protected : Pedestrian Object Track 2 Point of Interest Longitudinal Acceleration Authenticated";
BA_ "SignalLongName" SG_ 212 SRRSLRODPB1P_POTk2PoILgPsAuth "Short Range Radar Side Left Rear Object Detection and Processing Burst 1 Protected : Pedestrian Object Track 2 Point of Interest Longitudinal Position Authenticated";
BA_ "SignalLongName" SG_ 212 SRRSLRODPB1P_POTk2PoILgVAuth "Short Range Radar Side Left Rear Object Detection and Processing Burst 1 Protected : Pedestrian Object Track 2 Point of Interest Longitudinal Velocity Authenticated";
BA_ "SignalLongName" SG_ 212 SRRSLRODPB1P_POTk2PoILPsAuth "Short Range Radar Side Left Rear Object Detection and Processing Burst 1 Protected : Pedestrian Object Track 2 Point of Interest Lateral Position Authenticated";
BA_ "SignalLongName" SG_ 212 SRRSLRODPB1P_POTk2PoILVAuth "Short Range Radar Side Left Rear Object Detection and Processing Burst 1 Protected : Pedestrian Object Track 2 Point of Interest Lateral Velocity Authenticated";
BA_ "SignalType" SG_ 212 SRRSLRODPB1P_POTk2TypCnfdAuth "ENM";
BA_ "SignalLongName" SG_ 212 SRRSLRODPB1P_POTk2TypCnfdAuth "Short Range Radar Side Left Rear Object Detection and Processing Burst 1 Protected : Pedestrian Object Track 2 Type Confidence Authenticated";
BA_ "SignalType" SG_ 212 SRRSLRODPB1P_POTk2TypAuth "ENM";
BA_ "SignalLongName" SG_ 212 SRRSLRODPB1P_POTk2TypAuth "Short Range Radar Side Left Rear Object Detection and Processing Burst 1 Protected : Pedestrian Object Track 2 Type Authenticated";
BA_ "SignalType" SG_ 212 SRRSLRODPB1P_SnsrUnvAuth "ENM";
BA_ "SignalLongName" SG_ 212 SRRSLRODPB1P_SnsrUnvAuth "Short Range Radar Side Left Rear Object Detection and Processing Burst 1 Protected : Sensor Unavailable Authenticated";
BA_ "SignalType" SG_ 212 SRRSLRODPB1P_SnsrBlckdAuth "ENM";
BA_ "SignalLongName" SG_ 212 SRRSLRODPB1P_SnsrBlckdAuth "Short Range Radar Side Left Rear Object Detection and Processing Burst 1 Protected : Sensor Blocked Authenticated";
BA_ "SignalType" SG_ 212 SRRSLRODPB1P_ServRqrdAuth "ENM";
BA_ "SignalLongName" SG_ 212 SRRSLRODPB1P_ServRqrdAuth "Short Range Radar Side Left Rear Object Detection and Processing Burst 1 Protected : Service Required Authenticated";
BA_ "SignalType" SG_ 212 SRRSLRODPB1P_RdTypCnfdAuth "ENM";
BA_ "SignalLongName" SG_ 212 SRRSLRODPB1P_RdTypCnfdAuth "Short Range Radar Side Left Rear Object Detection and Processing Burst 1 Protected : Road Type Confidence Authenticated";
BA_ "SignalType" SG_ 212 SRRSLRODPB1P_RdTypAuth "ENM";
BA_ "SignalLongName" SG_ 212 SRRSLRODPB1P_RdTypAuth "Short Range Radar Side Left Rear Object Detection and Processing Burst 1 Protected : Road Type Authenticated";
BA_ "SignalLongName" SG_ 212 SRRSLRODPB1P_VOTk1CICOPotAuth "Short Range Radar Side Left Rear Object Detection and Processing Burst 1 Protected : Vehicle Object Track 1 Cut In Cut Out Potential Authenticated";
BA_ "SignalType" SG_ 212 SRRSLRODPB1P_SwpBndwdthStsAuth "ENM";
BA_ "SignalLongName" SG_ 212 SRRSLRODPB1P_SwpBndwdthStsAuth "Short Range Radar Side Left Rear Object Detection and Processing Burst 1 Protected : Sweep Bandwidth Status Authenticated";
BA_ "SignalLongName" SG_ 212 SRRSLRODPB1P_VOTk1IDAuth "Short Range Radar Side Left Rear Object Detection and Processing Burst 1 Protected : Vehicle Object Track 1 ID Authenticated";
BA_ "SignalType" SG_ 212 SRRSLRODPB1P_VOTk1DynPrpStsAuth "ENM";
BA_ "SignalLongName" SG_ 212 SRRSLRODPB1P_VOTk1DynPrpStsAuth "Short Range Radar Side Left Rear Object Detection and Processing Burst 1 Protected : Vehicle Object Track 1 Dynamic Property Status Authenticated";
BA_ "SignalType" SG_ 212 SRRSLRODPB1P_VOTk1DynPrpAuth "ENM";
BA_ "SignalLongName" SG_ 212 SRRSLRODPB1P_VOTk1DynPrpAuth "Short Range Radar Side Left Rear Object Detection and Processing Burst 1 Protected : Vehicle Object Track 1 Dynamic Property Authenticated";
BA_ "SignalType" SG_ 212 SRRSLRODPB1P_VOTk1CnfdStsAuth "ENM";
BA_ "SignalLongName" SG_ 212 SRRSLRODPB1P_VOTk1CnfdStsAuth "Short Range Radar Side Left Rear Object Detection and Processing Burst 1 Protected : Vehicle Object Track 1 Confidence Status Authenticated";
BA_ "SignalLongName" SG_ 212 SRRSLRODPB1P_VOTk1PoILAAuth "Short Range Radar Side Left Rear Object Detection and Processing Burst 1 Protected : Vehicle Object Track 1 Point of Interest Lateral Acceleration Authenticated";
BA_ "SignalType" SG_ 212 SRRSLRODPB1P_VOTk1MStsAuth "ENM";
BA_ "SignalLongName" SG_ 212 SRRSLRODPB1P_VOTk1MStsAuth "Short Range Radar Side Left Rear Object Detection and Processing Burst 1 Protected : Vehicle Object Track 1 Measurement Status Authenticated";
BA_ "SignalLongName" SG_ 212 SRRSLRODPB1P_VOTk1PoILgAAuth "Short Range Radar Side Left Rear Object Detection and Processing Burst 1 Protected : Vehicle Object Track 1 Point of Interest Longitudinal Acceleration Authenticated";
BA_ "SignalLongName" SG_ 212 SRRSLRODPB1P_VOTk1PoILgPsAuth "Short Range Radar Side Left Rear Object Detection and Processing Burst 1 Protected : Vehicle Object Track 1 Point of Interest Longitudinal Position Authenticated";
BA_ "SignalLongName" SG_ 212 SRRSLRODPB1P_VOTk1PoILgPsCAuth "Short Range Radar Side Left Rear Object Detection and Processing Burst 1 Protected : Vehicle Object Track 1 Point of Interest Longitudinal Position Covariance Authenticated";
BA_ "SignalLongName" SG_ 212 SRRSLRODPB1P_VOTk1PoILgthAuth "Short Range Radar Side Left Rear Object Detection and Processing Burst 1 Protected : Vehicle Object Track 1 Point of Interest Length Authenticated";
BA_ "SignalLongName" SG_ 212 SRRSLRODPB1P_VOTk1PoILgVAuth "Short Range Radar Side Left Rear Object Detection and Processing Burst 1 Protected : Vehicle Object Track 1 Point of Interest Longitudinal Velocity Authenticated";
BA_ "SignalLongName" SG_ 212 SRRSLRODPB1P_VOTk1PoILgVCAuth "Short Range Radar Side Left Rear Object Detection and Processing Burst 1 Protected : Vehicle Object Track 1 Point of Interest Longitudinal Velocity Covariance Authenticated";
BA_ "SignalLongName" SG_ 212 SRRSLRODPB1P_VOTk1PoILPsAuth "Short Range Radar Side Left Rear Object Detection and Processing Burst 1 Protected : Vehicle Object Track 1 Point of Interest Lateral Position Authenticated";
BA_ "SignalLongName" SG_ 212 SRRSLRODPB1P_VOTk1PoILPsCAuth "Short Range Radar Side Left Rear Object Detection and Processing Burst 1 Protected : Vehicle Object Track 1 Point of Interest Lateral Position Covariance Authenticated";
BA_ "SignalLongName" SG_ 212 SRRSLRODPB1P_VOTk1PoILVAuth "Short Range Radar Side Left Rear Object Detection and Processing Burst 1 Protected : Vehicle Object Track 1 Point of Interest Lateral Velocity Authenticated";
BA_ "SignalLongName" SG_ 212 SRRSLRODPB1P_VOTk1PoILVCAuth "Short Range Radar Side Left Rear Object Detection and Processing Burst 1 Protected : Vehicle Object Track 1 Point of Interest Lateral Velocity Covariance Authenticated";
BA_ "SignalLongName" SG_ 212 SRRSLRODPB1P_VOTk2PoILgthAuth "Short Range Radar Side Left Rear Object Detection and Processing Burst 1 Protected : Vehicle Object Track 2 Point of Interest Length Authenticated";
BA_ "SignalType" SG_ 212 SRRSLRODPB1P_VOTk1TypCnfdAuth "ENM";
BA_ "SignalLongName" SG_ 212 SRRSLRODPB1P_VOTk1TypCnfdAuth "Short Range Radar Side Left Rear Object Detection and Processing Burst 1 Protected : Vehicle Object Track 1 Type Confidence Authenticated";
BA_ "SignalLongName" SG_ 212 SRRSLRODPB1P_ARC "Short Range Radar Side Left Rear Object Detection and Processing Burst 1 Protected : Alive Rolling Count";
BA_ "SignalLongName" SG_ 217 SRRSLRODPB6P_IOTk10PolLPsAuth "Short Range Radar Side Left Rear Object Detection and Processing Burst 6 Protected : Infrastructure Object Track 10 Point of Interest Lateral Position Authenticated";
BA_ "SignalLongName" SG_ 217 SRRSLRODPB6P_BrstID "Short Range Radar Side Left Rear Object Detection and Processing Burst 6 Protected : Burst ID";
BA_ "SignalLongName" SG_ 217 SRRSLRODPB6P_IOTk1PoILPsAuth "Short Range Radar Side Left Rear Object Detection and Processing Burst 6 Protected : Infrastructure Object Track 1 Point of Interest Lateral Position Authenticated";
BA_ "SignalLongName" SG_ 217 SRRSLRODPB6P_IOTk2PolLPsAuth "Short Range Radar Side Left Rear Object Detection and Processing Burst 6 Protected : Infrastructure Object Track 2 Point of Interest Lateral Position Authenticated";
BA_ "SignalLongName" SG_ 217 SRRSLRODPB6P_IOTk3PolLPsAuth "Short Range Radar Side Left Rear Object Detection and Processing Burst 6 Protected : Infrastructure Object Track 3 Point of Interest Lateral Position Authenticated";
BA_ "SignalLongName" SG_ 217 SRRSLRODPB6P_IOTk4PolLPsAuth "Short Range Radar Side Left Rear Object Detection and Processing Burst 6 Protected : Infrastructure Object Track 4 Point of Interest Lateral Position Authenticated";
BA_ "SignalLongName" SG_ 217 SRRSLRODPB6P_IOTk5PolLPsAuth "Short Range Radar Side Left Rear Object Detection and Processing Burst 6 Protected : Infrastructure Object Track 5 Point of Interest Lateral Position Authenticated";
BA_ "SignalLongName" SG_ 217 SRRSLRODPB6P_IOTk6PolLPsAuth "Short Range Radar Side Left Rear Object Detection and Processing Burst 6 Protected : Infrastructure Object Track 6 Point of Interest Lateral Position Authenticated";
BA_ "SignalLongName" SG_ 217 SRRSLRODPB6P_IOTk7PolLPsAuth "Short Range Radar Side Left Rear Object Detection and Processing Burst 6 Protected : Infrastructure Object Track 7 Point of Interest Lateral Position Authenticated";
BA_ "SignalLongName" SG_ 217 SRRSLRODPB6P_IOTk8PolLPsAuth "Short Range Radar Side Left Rear Object Detection and Processing Burst 6 Protected : Infrastructure Object Track 8 Point of Interest Lateral Position Authenticated";
BA_ "SignalLongName" SG_ 217 SRRSLRODPB6P_IOTk9PolLPsAuth "Short Range Radar Side Left Rear Object Detection and Processing Burst 6 Protected : Infrastructure Object Track 9 Point of Interest Lateral Position Authenticated";
BA_ "SignalType" SG_ 217 SRRSLRODPB6P_REOTk1CnfdStsAuth "ENM";
BA_ "SignalLongName" SG_ 217 SRRSLRODPB6P_REOTk1CnfdStsAuth "Short Range Radar Side Left Rear Object Detection and Processing Burst 6 Protected : Road Edge Object Track 1 Confidence Status Authenticated";
BA_ "SignalLongName" SG_ 217 SRRSLRODPB6P_REOTk1CrvAuth "Short Range Radar Side Left Rear Object Detection and Processing Burst 6 Protected : Road Edge Object Track 1 Curvature Authenticated";
BA_ "SignalLongName" SG_ 217 SRRSLRODPB6P_REOTk1CrvDrvtAuth "Short Range Radar Side Left Rear Object Detection and Processing Burst 6 Protected : Road Edge Object Track 1 Curvature Derivative Authenticated";
BA_ "SignalLongName" SG_ 217 SRRSLRODPB6P_REOTk1HdgAuth "Short Range Radar Side Left Rear Object Detection and Processing Burst 6 Protected : Road Edge Object Track 1 Heading Authenticated";
BA_ "SignalLongName" SG_ 217 SRRSLRODPB6P_REOTk1OfstAuth "Short Range Radar Side Left Rear Object Detection and Processing Burst 6 Protected : Road Edge Object Track 1 Offset Authenticated";
BA_ "SignalLongName" SG_ 217 SRRSLRODPB6P_REOTk1PsEndAuth "Short Range Radar Side Left Rear Object Detection and Processing Burst 6 Protected : Road Edge Object Track 1 Position End Authenticated";
BA_ "SignalLongName" SG_ 217 SRRSLRODPB6P_REOTk1PsStrtAuth "Short Range Radar Side Left Rear Object Detection and Processing Burst 6 Protected : Road Edge Object Track 1 Position Start Authenticated";
BA_ "SignalType" SG_ 217 SRRSLRODPB6P_REOTk2CnfdStsAuth "ENM";
BA_ "SignalLongName" SG_ 217 SRRSLRODPB6P_REOTk2CnfdStsAuth "Short Range Radar Side Left Rear Object Detection and Processing Burst 6 Protected : Road Edge Object Track 2 Confidence Status Authenticated";
BA_ "SignalType" SG_ 217 SRRSLRODPB6P_REOTk1TypCnfdAuth "ENM";
BA_ "SignalLongName" SG_ 217 SRRSLRODPB6P_REOTk1TypCnfdAuth "Short Range Radar Side Left Rear Object Detection and Processing Burst 6 Protected : Road Edge Object Track 1 Type Confidence Authenticated";
BA_ "SignalType" SG_ 217 SRRSLRODPB6P_REOTk1TypAuth "ENM";
BA_ "SignalLongName" SG_ 217 SRRSLRODPB6P_REOTk1TypAuth "Short Range Radar Side Left Rear Object Detection and Processing Burst 6 Protected : Road Edge Object Track 1 Type Authenticated";
BA_ "SignalLongName" SG_ 217 SRRSLRODPB6P_REOTk2CrvAuth "Short Range Radar Side Left Rear Object Detection and Processing Burst 6 Protected : Road Edge Object Track 2 Curvature Authenticated";
BA_ "SignalLongName" SG_ 217 SRRSLRODPB6P_REOTk2CrvDrvtAuth "Short Range Radar Side Left Rear Object Detection and Processing Burst 6 Protected : Road Edge Object Track 2 Curvature Derivative Authenticated";
BA_ "SignalLongName" SG_ 217 SRRSLRODPB6P_REOTk2HdgAuth "Short Range Radar Side Left Rear Object Detection and Processing Burst 6 Protected : Road Edge Object Track 2 Heading Authenticated";
BA_ "SignalLongName" SG_ 217 SRRSLRODPB6P_REOTk2OfstAuth "Short Range Radar Side Left Rear Object Detection and Processing Burst 6 Protected : Road Edge Object Track 2 Offset Authenticated";
BA_ "SignalLongName" SG_ 217 SRRSLRODPB6P_REOTk2PsEndAuth "Short Range Radar Side Left Rear Object Detection and Processing Burst 6 Protected : Road Edge Object Track 2 Position End Authenticated";
BA_ "SignalLongName" SG_ 217 SRRSLRODPB6P_REOTk2PsStrtAuth "Short Range Radar Side Left Rear Object Detection and Processing Burst 6 Protected : Road Edge Object Track 2 Position Start Authenticated";
BA_ "SignalType" SG_ 217 SRRSLRODPB6P_REOTk3CnfdStsAuth "ENM";
BA_ "SignalLongName" SG_ 217 SRRSLRODPB6P_REOTk3CnfdStsAuth "Short Range Radar Side Left Rear Object Detection and Processing Burst 6 Protected : Road Edge Object Track 3 Confidence Status Authenticated";
BA_ "SignalType" SG_ 217 SRRSLRODPB6P_REOTk2TypCnfdAuth "ENM";
BA_ "SignalLongName" SG_ 217 SRRSLRODPB6P_REOTk2TypCnfdAuth "Short Range Radar Side Left Rear Object Detection and Processing Burst 6 Protected : Road Edge Object Track 2 Type Confidence Authenticated";
BA_ "SignalType" SG_ 217 SRRSLRODPB6P_REOTk2TypAuth "ENM";
BA_ "SignalLongName" SG_ 217 SRRSLRODPB6P_REOTk2TypAuth "Short Range Radar Side Left Rear Object Detection and Processing Burst 6 Protected : Road Edge Object Track 2 Type Authenticated";
BA_ "SignalLongName" SG_ 217 SRRSLRODPB6P_REOTk3CrvAuth "Short Range Radar Side Left Rear Object Detection and Processing Burst 6 Protected : Road Edge Object Track 3 Curvature Authenticated";
BA_ "SignalLongName" SG_ 217 SRRSLRODPB6P_REOTk3CrvDrvtAuth "Short Range Radar Side Left Rear Object Detection and Processing Burst 6 Protected : Road Edge Object Track 3 Curvature Derivative Authenticated";
BA_ "SignalLongName" SG_ 217 SRRSLRODPB6P_REOTk3HdgAuth "Short Range Radar Side Left Rear Object Detection and Processing Burst 6 Protected : Road Edge Object Track 3 Heading Authenticated";
BA_ "SignalLongName" SG_ 217 SRRSLRODPB6P_REOTk3OfstAuth "Short Range Radar Side Left Rear Object Detection and Processing Burst 6 Protected : Road Edge Object Track 3 Offset Authenticated";
BA_ "SignalLongName" SG_ 217 SRRSLRODPB6P_REOTk3PsEndAuth "Short Range Radar Side Left Rear Object Detection and Processing Burst 6 Protected : Road Edge Object Track 3 Position End Authenticated";
BA_ "SignalLongName" SG_ 217 SRRSLRODPB6P_REOTk3PsStrtAuth "Short Range Radar Side Left Rear Object Detection and Processing Burst 6 Protected : Road Edge Object Track 3 Position Start Authenticated";
BA_ "SignalType" SG_ 217 SRRSLRODPB6P_REOTk3TypCnfdAuth "ENM";
BA_ "SignalLongName" SG_ 217 SRRSLRODPB6P_REOTk3TypCnfdAuth "Short Range Radar Side Left Rear Object Detection and Processing Burst 6 Protected : Road Edge Object Track 3 Type Confidence Authenticated";
BA_ "SignalType" SG_ 217 SRRSLRODPB6P_REOTk3TypAuth "ENM";
BA_ "SignalLongName" SG_ 217 SRRSLRODPB6P_REOTk3TypAuth "Short Range Radar Side Left Rear Object Detection and Processing Burst 6 Protected : Road Edge Object Track 3 Type Authenticated";
BA_ "SignalLongName" SG_ 219 SRRSRRODPB2P_POTk3IDAuth "Short Range Radar Side Right Rear Object Detection and Processing Burst 2 Protected : Pedestrian Object Track 3 ID Authenticated";
BA_ "SignalType" SG_ 219 SRRSRRODPB2P_POTk3DynPrpAuth "ENM";
BA_ "SignalLongName" SG_ 219 SRRSRRODPB2P_POTk3DynPrpAuth "Short Range Radar Side Right Rear Object Detection and Processing Burst 2 Protected : Pedestrian Object Track 3 Dynamic Property Authenticated";
BA_ "SignalType" SG_ 219 SRRSRRODPB2P_POTk3CnfdStsAuth "ENM";
BA_ "SignalLongName" SG_ 219 SRRSRRODPB2P_POTk3CnfdStsAuth "Short Range Radar Side Right Rear Object Detection and Processing Burst 2 Protected : Pedestrian Object Track 3 Confidence Status Authenticated";
BA_ "SignalLongName" SG_ 219 SRRSRRODPB2P_BrstID "Short Range Radar Side Right Rear Object Detection and Processing Burst 2 Protected : Burst ID";
BA_ "SignalLongName" SG_ 219 SRRSRRODPB2P_POTk3InPthPotAuth "Short Range Radar Side Right Rear Object Detection and Processing Burst 2 Protected : Pedestrian Object Track 3 In Path Potential Authenticated";
BA_ "SignalLongName" SG_ 219 SRRSRRODPB2P_POTk3PoILAAuth "Short Range Radar Side Right Rear Object Detection and Processing Burst 2 Protected : Pedestrian Object Track 3 Point of Interest Lateral Acceleration Authenticated";
BA_ "SignalType" SG_ 219 SRRSRRODPB2P_POTk3MStsAuth "ENM";
BA_ "SignalLongName" SG_ 219 SRRSRRODPB2P_POTk3MStsAuth "Short Range Radar Side Right Rear Object Detection and Processing Burst 2 Protected : Pedestrian Object Track 3 Measurement Status Authenticated";
BA_ "SignalLongName" SG_ 219 SRRSRRODPB2P_POTk3PoILgAAuth "Short Range Radar Side Right Rear Object Detection and Processing Burst 2 Protected : Pedestrian Object Track 3 Point of Interest Longitudinal Acceleration Authenticated";
BA_ "SignalLongName" SG_ 219 SRRSRRODPB2P_POTk3PoILgPsAuth "Short Range Radar Side Right Rear Object Detection and Processing Burst 2 Protected : Pedestrian Object Track 3 Point of Interest Longitudinal Position Authenticated";
BA_ "SignalLongName" SG_ 219 SRRSRRODPB2P_POTk3PoILgVAuth "Short Range Radar Side Right Rear Object Detection and Processing Burst 2 Protected : Pedestrian Object Track 3 Point of Interest Longitudinal Velocity Authenticated";
BA_ "SignalLongName" SG_ 219 SRRSRRODPB2P_POTk3PoILPsAuth "Short Range Radar Side Right Rear Object Detection and Processing Burst 2 Protected : Pedestrian Object Track 3 Point of Interest Lateral Position Authenticated";
BA_ "SignalLongName" SG_ 219 SRRSRRODPB2P_POTk3PoILVAuth "Short Range Radar Side Right Rear Object Detection and Processing Burst 2 Protected : Pedestrian Object Track 3 Point of Interest Lateral Velocity Authenticated";
BA_ "SignalLongName" SG_ 219 SRRSRRODPB2P_VOTk2CICOPotAuth "Short Range Radar Side Right Rear Object Detection and Processing Burst 2 Protected : Vehicle Object Track 2 Cut In Cut Out Potential Authenticated";
BA_ "SignalType" SG_ 219 SRRSRRODPB2P_POTk3TypCnfdAuth "ENM";
BA_ "SignalLongName" SG_ 219 SRRSRRODPB2P_POTk3TypCnfdAuth "Short Range Radar Side Right Rear Object Detection and Processing Burst 2 Protected : Pedestrian Object Track 3 Type Confidence Authenticated";
BA_ "SignalType" SG_ 219 SRRSRRODPB2P_POTk3TypAuth "ENM";
BA_ "SignalLongName" SG_ 219 SRRSRRODPB2P_POTk3TypAuth "Short Range Radar Side Right Rear Object Detection and Processing Burst 2 Protected : Pedestrian Object Track 3 Type Authenticated";
BA_ "SignalType" SG_ 219 SRRSRRODPB2P_VOTk2DynPrpStsAuth "ENM";
BA_ "SignalLongName" SG_ 219 SRRSRRODPB2P_VOTk2DynPrpStsAuth "Short Range Radar Side Right Rear Object Detection and Processing Burst 2 Protected : Vehicle Object Track 2 Dynamic Property Status Authenticated";
BA_ "SignalType" SG_ 219 SRRSRRODPB2P_VOTk2DynPrpAuth "ENM";
BA_ "SignalLongName" SG_ 219 SRRSRRODPB2P_VOTk2DynPrpAuth "Short Range Radar Side Right Rear Object Detection and Processing Burst 2 Protected : Vehicle Object Track 2 Dynamic Property Authenticated";
BA_ "SignalType" SG_ 219 SRRSRRODPB2P_VOTk2CnfdStsAuth "ENM";
BA_ "SignalLongName" SG_ 219 SRRSRRODPB2P_VOTk2CnfdStsAuth "Short Range Radar Side Right Rear Object Detection and Processing Burst 2 Protected : Vehicle Object Track 2 Confidence Status Authenticated";
BA_ "SignalType" SG_ 219 SRRSRRODPB2P_VOTk2MStsAuth "ENM";
BA_ "SignalLongName" SG_ 219 SRRSRRODPB2P_VOTk2MStsAuth "Short Range Radar Side Right Rear Object Detection and Processing Burst 2 Protected : Vehicle Object Track 2 Measurement Status Authenticated";
BA_ "SignalLongName" SG_ 219 SRRSRRODPB2P_VOTk2IDAuth "Short Range Radar Side Right Rear Object Detection and Processing Burst 2 Protected : Vehicle Object Track 2 ID Authenticated";
BA_ "SignalLongName" SG_ 219 SRRSRRODPB2P_VOTk2PoILAAuth "Short Range Radar Side Right Rear Object Detection and Processing Burst 2 Protected : Vehicle Object Track 2 Point of Interest Lateral Acceleration Authenticated";
BA_ "SignalLongName" SG_ 219 SRRSRRODPB2P_VOTk2PoILgAAuth "Short Range Radar Side Right Rear Object Detection and Processing Burst 2 Protected : Vehicle Object Track 2 Point of Interest Longitudinal Acceleration Authenticated";
BA_ "SignalLongName" SG_ 219 SRRSRRODPB2P_VOTk2PoILgPsAuth "Short Range Radar Side Right Rear Object Detection and Processing Burst 2 Protected : Vehicle Object Track 2 Point of Interest Longitudinal Position Authenticated";
BA_ "SignalLongName" SG_ 219 SRRSRRODPB2P_VOTk2PoILgPsCAuth "Short Range Radar Side Right Rear Object Detection and Processing Burst 2 Protected : Vehicle Object Track 2 Point of Interest Longitudinal Position Covariance Authenticated";
BA_ "SignalLongName" SG_ 219 SRRSRRODPB2P_VOTk2PoILgVAuth "Short Range Radar Side Right Rear Object Detection and Processing Burst 2 Protected : Vehicle Object Track 2 Point of Interest Longitudinal Velocity Authenticated";
BA_ "SignalLongName" SG_ 219 SRRSRRODPB2P_VOTk2PoILgVCAuth "Short Range Radar Side Right Rear Object Detection and Processing Burst 2 Protected : Vehicle Object Track 2 Point of Interest Longitudinal Velocity Covariance Authenticated";
BA_ "SignalLongName" SG_ 219 SRRSRRODPB2P_VOTk2PoILPsAuth "Short Range Radar Side Right Rear Object Detection and Processing Burst 2 Protected : Vehicle Object Track 2 Point of Interest Lateral Position Authenticated";
BA_ "SignalLongName" SG_ 219 SRRSRRODPB2P_VOTk2PoILPsCAuth "Short Range Radar Side Right Rear Object Detection and Processing Burst 2 Protected : Vehicle Object Track 2 Point of Interest Lateral Position Covariance Authenticated";
BA_ "SignalLongName" SG_ 219 SRRSRRODPB2P_VOTk2PoILVAuth "Short Range Radar Side Right Rear Object Detection and Processing Burst 2 Protected : Vehicle Object Track 2 Point of Interest Lateral Velocity Authenticated";
BA_ "SignalLongName" SG_ 219 SRRSRRODPB2P_VOTk2PoILVCAuth "Short Range Radar Side Right Rear Object Detection and Processing Burst 2 Protected : Vehicle Object Track 2 Point of Interest Lateral Velocity Covariance Authenticated";
BA_ "SignalType" SG_ 219 SRRSRRODPB2P_VOTk2TypCnfdAuth "ENM";
BA_ "SignalLongName" SG_ 219 SRRSRRODPB2P_VOTk2TypCnfdAuth "Short Range Radar Side Right Rear Object Detection and Processing Burst 2 Protected : Vehicle Object Track 2 Type Confidence Authenticated";
BA_ "SignalType" SG_ 219 SRRSRRODPB2P_VOTk3CnfdStsAuth "ENM";
BA_ "SignalLongName" SG_ 219 SRRSRRODPB2P_VOTk3CnfdStsAuth "Short Range Radar Side Right Rear Object Detection and Processing Burst 2 Protected : Vehicle Object Track 3 Confidence Status Authenticated";
BA_ "SignalLongName" SG_ 219 SRRSRRODPB2P_VOTk3CICOPotAuth "Short Range Radar Side Right Rear Object Detection and Processing Burst 2 Protected : Vehicle Object Track 3 Cut In Cut Out Potential Authenticated";
BA_ "SignalLongName" SG_ 219 SRRSRRODPB2P_VOTk3IDAuth "Short Range Radar Side Right Rear Object Detection and Processing Burst 2 Protected : Vehicle Object Track 3 ID Authenticated";
BA_ "SignalType" SG_ 219 SRRSRRODPB2P_VOTk3DynPrpStsAuth "ENM";
BA_ "SignalLongName" SG_ 219 SRRSRRODPB2P_VOTk3DynPrpStsAuth "Short Range Radar Side Right Rear Object Detection and Processing Burst 2 Protected : Vehicle Object Track 3 Dynamic Property Status Authenticated";
BA_ "SignalType" SG_ 219 SRRSRRODPB2P_VOTk3DynPrpAuth "ENM";
BA_ "SignalLongName" SG_ 219 SRRSRRODPB2P_VOTk3DynPrpAuth "Short Range Radar Side Right Rear Object Detection and Processing Burst 2 Protected : Vehicle Object Track 3 Dynamic Property Authenticated";
BA_ "SignalLongName" SG_ 219 SRRSRRODPB2P_VOTk3PoILAAuth "Short Range Radar Side Right Rear Object Detection and Processing Burst 2 Protected : Vehicle Object Track 3 Point of Interest Lateral Acceleration Authenticated";
BA_ "SignalType" SG_ 219 SRRSRRODPB2P_VOTk3MStsAuth "ENM";
BA_ "SignalLongName" SG_ 219 SRRSRRODPB2P_VOTk3MStsAuth "Short Range Radar Side Right Rear Object Detection and Processing Burst 2 Protected : Vehicle Object Track 3 Measurement Status Authenticated";
BA_ "SignalLongName" SG_ 219 SRRSRRODPB2P_VOTk3PoILgAAuth "Short Range Radar Side Right Rear Object Detection and Processing Burst 2 Protected : Vehicle Object Track 3 Point of Interest Longitudinal Acceleration Authenticated";
BA_ "SignalLongName" SG_ 219 SRRSRRODPB2P_VOTk3PoILgPsAuth "Short Range Radar Side Right Rear Object Detection and Processing Burst 2 Protected : Vehicle Object Track 3 Point of Interest Longitudinal Position Authenticated";
BA_ "SignalLongName" SG_ 219 SRRSRRODPB2P_VOTk3PoILgPsCAuth "Short Range Radar Side Right Rear Object Detection and Processing Burst 2 Protected : Vehicle Object Track 3 Point of Interest Longitudinal Position Covariance Authenticated";
BA_ "SignalLongName" SG_ 219 SRRSRRODPB2P_VOTk3PoILgthAuth "Short Range Radar Side Right Rear Object Detection and Processing Burst 2 Protected : Vehicle Object Track 3 Point of Interest Length Authenticated";
BA_ "SignalLongName" SG_ 219 SRRSRRODPB2P_VOTk3PoILgVAuth "Short Range Radar Side Right Rear Object Detection and Processing Burst 2 Protected : Vehicle Object Track 3 Point of Interest Longitudinal Velocity Authenticated";
BA_ "SignalLongName" SG_ 219 SRRSRRODPB2P_VOTk3PoILgVCAuth "Short Range Radar Side Right Rear Object Detection and Processing Burst 2 Protected : Vehicle Object Track 3 Point of Interest Longitudinal Velocity Covariance Authenticated";
BA_ "SignalLongName" SG_ 219 SRRSRRODPB2P_VOTk3PoILPsAuth "Short Range Radar Side Right Rear Object Detection and Processing Burst 2 Protected : Vehicle Object Track 3 Point of Interest Lateral Position Authenticated";
BA_ "SignalLongName" SG_ 219 SRRSRRODPB2P_VOTk3PoILPsCAuth "Short Range Radar Side Right Rear Object Detection and Processing Burst 2 Protected : Vehicle Object Track 3 Point of Interest Lateral Position Covariance Authenticated";
BA_ "SignalLongName" SG_ 219 SRRSRRODPB2P_VOTk3PoILVAuth "Short Range Radar Side Right Rear Object Detection and Processing Burst 2 Protected : Vehicle Object Track 3 Point of Interest Lateral Velocity Authenticated";
BA_ "SignalLongName" SG_ 219 SRRSRRODPB2P_VOTk3PoILVCAuth "Short Range Radar Side Right Rear Object Detection and Processing Burst 2 Protected : Vehicle Object Track 3 Point of Interest Lateral Velocity Covariance Authenticated";
BA_ "SignalLongName" SG_ 219 SRRSRRODPB2P_VOTk4CICOPotAuth "Short Range Radar Side Right Rear Object Detection and Processing Burst 2 Protected : Vehicle Object Track 4 Cut In Cut Out Potential Authenticated";
BA_ "SignalType" SG_ 219 SRRSRRODPB2P_VOTk3TypCnfdAuth "ENM";
BA_ "SignalLongName" SG_ 219 SRRSRRODPB2P_VOTk3TypCnfdAuth "Short Range Radar Side Right Rear Object Detection and Processing Burst 2 Protected : Vehicle Object Track 3 Type Confidence Authenticated";
BA_ "SignalType" SG_ 219 SRRSRRODPB2P_VOTk4DynPrpStsAuth "ENM";
BA_ "SignalLongName" SG_ 219 SRRSRRODPB2P_VOTk4DynPrpStsAuth "Short Range Radar Side Right Rear Object Detection and Processing Burst 2 Protected : Vehicle Object Track 4 Dynamic Property Status Authenticated";
BA_ "SignalType" SG_ 219 SRRSRRODPB2P_VOTk4DynPrpAuth "ENM";
BA_ "SignalLongName" SG_ 219 SRRSRRODPB2P_VOTk4DynPrpAuth "Short Range Radar Side Right Rear Object Detection and Processing Burst 2 Protected : Vehicle Object Track 4 Dynamic Property Authenticated";
BA_ "SignalType" SG_ 219 SRRSRRODPB2P_VOTk4CnfdStsAuth "ENM";
BA_ "SignalLongName" SG_ 219 SRRSRRODPB2P_VOTk4CnfdStsAuth "Short Range Radar Side Right Rear Object Detection and Processing Burst 2 Protected : Vehicle Object Track 4 Confidence Status Authenticated";
BA_ "SignalType" SG_ 219 SRRSRRODPB2P_VOTk4MStsAuth "ENM";
BA_ "SignalLongName" SG_ 219 SRRSRRODPB2P_VOTk4MStsAuth "Short Range Radar Side Right Rear Object Detection and Processing Burst 2 Protected : Vehicle Object Track 4 Measurement Status Authenticated";
BA_ "SignalLongName" SG_ 219 SRRSRRODPB2P_VOTk4IDAuth "Short Range Radar Side Right Rear Object Detection and Processing Burst 2 Protected : Vehicle Object Track 4 ID Authenticated";
BA_ "SignalLongName" SG_ 219 SRRSRRODPB2P_VOTk4PoILAAuth "Short Range Radar Side Right Rear Object Detection and Processing Burst 2 Protected : Vehicle Object Track 4 Point of Interest Lateral Acceleration Authenticated";
BA_ "SignalLongName" SG_ 219 SRRSRRODPB2P_VOTk4PoILgAAuth "Short Range Radar Side Right Rear Object Detection and Processing Burst 2 Protected : Vehicle Object Track 4 Point of Interest Longitudinal Acceleration Authenticated";
BA_ "SignalLongName" SG_ 219 SRRSRRODPB2P_VOTk4PoILgPsAuth "Short Range Radar Side Right Rear Object Detection and Processing Burst 2 Protected : Vehicle Object Track 4 Point of Interest Longitudinal Position Authenticated";
BA_ "SignalLongName" SG_ 219 SRRSRRODPB2P_VOTk4PoILgPsCAuth "Short Range Radar Side Right Rear Object Detection and Processing Burst 2 Protected : Vehicle Object Track 4 Point of Interest Longitudinal Position Covariance Authenticated";
BA_ "SignalLongName" SG_ 219 SRRSRRODPB2P_VOTk4PoILgthAuth "Short Range Radar Side Right Rear Object Detection and Processing Burst 2 Protected : Vehicle Object Track 4 Point of Interest Length Authenticated";
BA_ "SignalLongName" SG_ 219 SRRSRRODPB2P_VOTk4PoILgVAuth "Short Range Radar Side Right Rear Object Detection and Processing Burst 2 Protected : Vehicle Object Track 4 Point of Interest Longitudinal Velocity Authenticated";
BA_ "SignalLongName" SG_ 219 SRRSRRODPB2P_VOTk4PoILgVCAuth "Short Range Radar Side Right Rear Object Detection and Processing Burst 2 Protected : Vehicle Object Track 4 Point of Interest Longitudinal Velocity Covariance Authenticated";
BA_ "SignalLongName" SG_ 219 SRRSRRODPB2P_VOTk4PoILPsAuth "Short Range Radar Side Right Rear Object Detection and Processing Burst 2 Protected : Vehicle Object Track 4 Point of Interest Lateral Position Authenticated";
BA_ "SignalLongName" SG_ 219 SRRSRRODPB2P_VOTk4PoILPsCAuth "Short Range Radar Side Right Rear Object Detection and Processing Burst 2 Protected : Vehicle Object Track 4 Point of Interest Lateral Position Covariance Authenticated";
BA_ "SignalLongName" SG_ 219 SRRSRRODPB2P_VOTk4PoILVAuth "Short Range Radar Side Right Rear Object Detection and Processing Burst 2 Protected : Vehicle Object Track 4 Point of Interest Lateral Velocity Authenticated";
BA_ "SignalLongName" SG_ 219 SRRSRRODPB2P_VOTk4PoILVCAuth "Short Range Radar Side Right Rear Object Detection and Processing Burst 2 Protected : Vehicle Object Track 4 Point of Interest Lateral Velocity Covariance Authenticated";
BA_ "SignalType" SG_ 219 SRRSRRODPB2P_VOTk4TypCnfdAuth "ENM";
BA_ "SignalLongName" SG_ 219 SRRSRRODPB2P_VOTk4TypCnfdAuth "Short Range Radar Side Right Rear Object Detection and Processing Burst 2 Protected : Vehicle Object Track 4 Type Confidence Authenticated";
BA_ "SignalLongName" SG_ 219 SRRSRRODPB2P_VOTk5PoILgthAuth "Short Range Radar Side Right Rear Object Detection and Processing Burst 2 Protected : Vehicle Object Track 5 Point of Interest Length Authenticated";
BA_ "SignalLongName" SG_ 220 SRRSRRODPB3P_POTk4IDAuth "Short Range Radar Side Right Rear Object Detection and Processing Burst 3 Protected : Pedestrian Object Track 4 ID Authenticated";
BA_ "SignalType" SG_ 220 SRRSRRODPB3P_POTk4DynPrpAuth "ENM";
BA_ "SignalLongName" SG_ 220 SRRSRRODPB3P_POTk4DynPrpAuth "Short Range Radar Side Right Rear Object Detection and Processing Burst 3 Protected : Pedestrian Object Track 4 Dynamic Property Authenticated";
BA_ "SignalType" SG_ 220 SRRSRRODPB3P_POTk4CnfdStsAuth "ENM";
BA_ "SignalLongName" SG_ 220 SRRSRRODPB3P_POTk4CnfdStsAuth "Short Range Radar Side Right Rear Object Detection and Processing Burst 3 Protected : Pedestrian Object Track 4 Confidence Status Authenticated";
BA_ "SignalLongName" SG_ 220 SRRSRRODPB3P_BrstID "Short Range Radar Side Right Rear Object Detection and Processing Burst 3 Protected : Burst ID";
BA_ "SignalLongName" SG_ 220 SRRSRRODPB3P_POTk4InPthPotAuth "Short Range Radar Side Right Rear Object Detection and Processing Burst 3 Protected : Pedestrian Object Track 4 In Path Potential Authenticated";
BA_ "SignalLongName" SG_ 220 SRRSRRODPB3P_POTk4PoILAAuth "Short Range Radar Side Right Rear Object Detection and Processing Burst 3 Protected : Pedestrian Object Track 4 Point of Interest Lateral Acceleration Authenticated";
BA_ "SignalType" SG_ 220 SRRSRRODPB3P_POTk4MStsAuth "ENM";
BA_ "SignalLongName" SG_ 220 SRRSRRODPB3P_POTk4MStsAuth "Short Range Radar Side Right Rear Object Detection and Processing Burst 3 Protected : Pedestrian Object Track 4 Measurement Status Authenticated";
BA_ "SignalLongName" SG_ 220 SRRSRRODPB3P_POTk4PoILgAAuth "Short Range Radar Side Right Rear Object Detection and Processing Burst 3 Protected : Pedestrian Object Track 4 Point of Interest Longitudinal Acceleration Authenticated";
BA_ "SignalLongName" SG_ 220 SRRSRRODPB3P_POTk4PoILgPsAuth "Short Range Radar Side Right Rear Object Detection and Processing Burst 3 Protected : Pedestrian Object Track 4 Point of Interest Longitudinal Position Authenticated";
BA_ "SignalLongName" SG_ 220 SRRSRRODPB3P_POTk4PoILgVAuth "Short Range Radar Side Right Rear Object Detection and Processing Burst 3 Protected : Pedestrian Object Track 4 Point of Interest Longitudinal Velocity Authenticated";
BA_ "SignalLongName" SG_ 220 SRRSRRODPB3P_POTk4PoILPsAuth "Short Range Radar Side Right Rear Object Detection and Processing Burst 3 Protected : Pedestrian Object Track 4 Point of Interest Lateral Position Authenticated";
BA_ "SignalLongName" SG_ 220 SRRSRRODPB3P_POTk4PoILVAuth "Short Range Radar Side Right Rear Object Detection and Processing Burst 3 Protected : Pedestrian Object Track 4 Point of Interest Lateral Velocity Authenticated";
BA_ "SignalLongName" SG_ 220 SRRSRRODPB3P_VOTk5CICOPotAuth "Short Range Radar Side Right Rear Object Detection and Processing Burst 3 Protected : Vehicle Object Track 5 Cut In Cut Out Potential Authenticated";
BA_ "SignalType" SG_ 220 SRRSRRODPB3P_POTk4TypCnfdAuth "ENM";
BA_ "SignalLongName" SG_ 220 SRRSRRODPB3P_POTk4TypCnfdAuth "Short Range Radar Side Right Rear Object Detection and Processing Burst 3 Protected : Pedestrian Object Track 4 Type Confidence Authenticated";
BA_ "SignalType" SG_ 220 SRRSRRODPB3P_POTk4TypAuth "ENM";
BA_ "SignalLongName" SG_ 220 SRRSRRODPB3P_POTk4TypAuth "Short Range Radar Side Right Rear Object Detection and Processing Burst 3 Protected : Pedestrian Object Track 4 Type Authenticated";
BA_ "SignalType" SG_ 220 SRRSRRODPB3P_VOTk5DynPrpStsAuth "ENM";
BA_ "SignalLongName" SG_ 220 SRRSRRODPB3P_VOTk5DynPrpStsAuth "Short Range Radar Side Right Rear Object Detection and Processing Burst 3 Protected : Vehicle Object Track 5 Dynamic Property Status Authenticated";
BA_ "SignalType" SG_ 220 SRRSRRODPB3P_VOTk5DynPrpAuth "ENM";
BA_ "SignalLongName" SG_ 220 SRRSRRODPB3P_VOTk5DynPrpAuth "Short Range Radar Side Right Rear Object Detection and Processing Burst 3 Protected : Vehicle Object Track 5 Dynamic Property Authenticated";
BA_ "SignalType" SG_ 220 SRRSRRODPB3P_VOTk5CnfdStsAuth "ENM";
BA_ "SignalLongName" SG_ 220 SRRSRRODPB3P_VOTk5CnfdStsAuth "Short Range Radar Side Right Rear Object Detection and Processing Burst 3 Protected : Vehicle Object Track 5 Confidence Status Authenticated";
BA_ "SignalType" SG_ 220 SRRSRRODPB3P_VOTk5MStsAuth "ENM";
BA_ "SignalLongName" SG_ 220 SRRSRRODPB3P_VOTk5MStsAuth "Short Range Radar Side Right Rear Object Detection and Processing Burst 3 Protected : Vehicle Object Track 5 Measurement Status Authenticated";
BA_ "SignalLongName" SG_ 220 SRRSRRODPB3P_VOTk5IDAuth "Short Range Radar Side Right Rear Object Detection and Processing Burst 3 Protected : Vehicle Object Track 5 ID Authenticated";
BA_ "SignalLongName" SG_ 220 SRRSRRODPB3P_VOTk5PoILAAuth "Short Range Radar Side Right Rear Object Detection and Processing Burst 3 Protected : Vehicle Object Track 5 Point of Interest Lateral Acceleration Authenticated";
BA_ "SignalLongName" SG_ 220 SRRSRRODPB3P_VOTk5PoILgAAuth "Short Range Radar Side Right Rear Object Detection and Processing Burst 3 Protected : Vehicle Object Track 5 Point of Interest Longitudinal Acceleration Authenticated";
BA_ "SignalLongName" SG_ 220 SRRSRRODPB3P_VOTk5PoILgPsAuth "Short Range Radar Side Right Rear Object Detection and Processing Burst 3 Protected : Vehicle Object Track 5 Point of Interest Longitudinal Position Authenticated";
BA_ "SignalLongName" SG_ 220 SRRSRRODPB3P_VOTk5PoILgPsCAuth "Short Range Radar Side Right Rear Object Detection and Processing Burst 3 Protected : Vehicle Object Track 5 Point of Interest Longitudinal Position Covariance Authenticated";
BA_ "SignalLongName" SG_ 220 SRRSRRODPB3P_VOTk5PoILgVAuth "Short Range Radar Side Right Rear Object Detection and Processing Burst 3 Protected : Vehicle Object Track 5 Point of Interest Longitudinal Velocity Authenticated";
BA_ "SignalLongName" SG_ 220 SRRSRRODPB3P_VOTk5PoILgVCAuth "Short Range Radar Side Right Rear Object Detection and Processing Burst 3 Protected : Vehicle Object Track 5 Point of Interest Longitudinal Velocity Covariance Authenticated";
BA_ "SignalLongName" SG_ 220 SRRSRRODPB3P_VOTk5PoILPsAuth "Short Range Radar Side Right Rear Object Detection and Processing Burst 3 Protected : Vehicle Object Track 5 Point of Interest Lateral Position Authenticated";
BA_ "SignalLongName" SG_ 220 SRRSRRODPB3P_VOTk5PoILPsCAuth "Short Range Radar Side Right Rear Object Detection and Processing Burst 3 Protected : Vehicle Object Track 5 Point of Interest Lateral Position Covariance Authenticated";
BA_ "SignalLongName" SG_ 220 SRRSRRODPB3P_VOTk5PoILVAuth "Short Range Radar Side Right Rear Object Detection and Processing Burst 3 Protected : Vehicle Object Track 5 Point of Interest Lateral Velocity Authenticated";
BA_ "SignalLongName" SG_ 220 SRRSRRODPB3P_VOTk5PoILVCAuth "Short Range Radar Side Right Rear Object Detection and Processing Burst 3 Protected : Vehicle Object Track 5 Point of Interest Lateral Velocity Covariance Authenticated";
BA_ "SignalType" SG_ 220 SRRSRRODPB3P_VOTk5TypCnfdAuth "ENM";
BA_ "SignalLongName" SG_ 220 SRRSRRODPB3P_VOTk5TypCnfdAuth "Short Range Radar Side Right Rear Object Detection and Processing Burst 3 Protected : Vehicle Object Track 5 Type Confidence Authenticated";
BA_ "SignalType" SG_ 220 SRRSRRODPB3P_VOTk6CnfdStsAuth "ENM";
BA_ "SignalLongName" SG_ 220 SRRSRRODPB3P_VOTk6CnfdStsAuth "Short Range Radar Side Right Rear Object Detection and Processing Burst 3 Protected : Vehicle Object Track 6 Confidence Status Authenticated";
BA_ "SignalLongName" SG_ 220 SRRSRRODPB3P_VOTk6CICOPotAuth "Short Range Radar Side Right Rear Object Detection and Processing Burst 3 Protected : Vehicle Object Track 6 Cut In Cut Out Potential Authenticated";
BA_ "SignalLongName" SG_ 220 SRRSRRODPB3P_VOTk6IDAuth "Short Range Radar Side Right Rear Object Detection and Processing Burst 3 Protected : Vehicle Object Track 6 ID Authenticated";
BA_ "SignalType" SG_ 220 SRRSRRODPB3P_VOTk6DynPrpStsAuth "ENM";
BA_ "SignalLongName" SG_ 220 SRRSRRODPB3P_VOTk6DynPrpStsAuth "Short Range Radar Side Right Rear Object Detection and Processing Burst 3 Protected : Vehicle Object Track 6 Dynamic Property Status Authenticated";
BA_ "SignalType" SG_ 220 SRRSRRODPB3P_VOTk6DynPrpAuth "ENM";
BA_ "SignalLongName" SG_ 220 SRRSRRODPB3P_VOTk6DynPrpAuth "Short Range Radar Side Right Rear Object Detection and Processing Burst 3 Protected : Vehicle Object Track 6 Dynamic Property Authenticated";
BA_ "SignalLongName" SG_ 220 SRRSRRODPB3P_VOTk6PoILAAuth "Short Range Radar Side Right Rear Object Detection and Processing Burst 3 Protected : Vehicle Object Track 6 Point of Interest Lateral Acceleration Authenticated";
BA_ "SignalType" SG_ 220 SRRSRRODPB3P_VOTk6MStsAuth "ENM";
BA_ "SignalLongName" SG_ 220 SRRSRRODPB3P_VOTk6MStsAuth "Short Range Radar Side Right Rear Object Detection and Processing Burst 3 Protected : Vehicle Object Track 6 Measurement Status Authenticated";
BA_ "SignalLongName" SG_ 220 SRRSRRODPB3P_VOTk6PoILgAAuth "Short Range Radar Side Right Rear Object Detection and Processing Burst 3 Protected : Vehicle Object Track 6 Point of Interest Longitudinal Acceleration Authenticated";
BA_ "SignalLongName" SG_ 220 SRRSRRODPB3P_VOTk6PoILgPsAuth "Short Range Radar Side Right Rear Object Detection and Processing Burst 3 Protected : Vehicle Object Track 6 Point of Interest Longitudinal Position Authenticated";
BA_ "SignalLongName" SG_ 220 SRRSRRODPB3P_VOTk6PoILgPsCAuth "Short Range Radar Side Right Rear Object Detection and Processing Burst 3 Protected : Vehicle Object Track 6 Point of Interest Longitudinal Position Covariance Authenticated";
BA_ "SignalLongName" SG_ 220 SRRSRRODPB3P_VOTk6PoILgthAuth "Short Range Radar Side Right Rear Object Detection and Processing Burst 3 Protected : Vehicle Object Track 6 Point of Interest Length Authenticated";
BA_ "SignalLongName" SG_ 220 SRRSRRODPB3P_VOTk6PoILgVAuth "Short Range Radar Side Right Rear Object Detection and Processing Burst 3 Protected : Vehicle Object Track 6 Point of Interest Longitudinal Velocity Authenticated";
BA_ "SignalLongName" SG_ 220 SRRSRRODPB3P_VOTk6PoILgVCAuth "Short Range Radar Side Right Rear Object Detection and Processing Burst 3 Protected : Vehicle Object Track 6 Point of Interest Longitudinal Velocity Covariance Authenticated";
BA_ "SignalLongName" SG_ 220 SRRSRRODPB3P_VOTk6PoILPsAuth "Short Range Radar Side Right Rear Object Detection and Processing Burst 3 Protected : Vehicle Object Track 6 Point of Interest Lateral Position Authenticated";
BA_ "SignalLongName" SG_ 220 SRRSRRODPB3P_VOTk6PoILPsCAuth "Short Range Radar Side Right Rear Object Detection and Processing Burst 3 Protected : Vehicle Object Track 6 Point of Interest Lateral Position Covariance Authenticated";
BA_ "SignalLongName" SG_ 220 SRRSRRODPB3P_VOTk6PoILVAuth "Short Range Radar Side Right Rear Object Detection and Processing Burst 3 Protected : Vehicle Object Track 6 Point of Interest Lateral Velocity Authenticated";
BA_ "SignalLongName" SG_ 220 SRRSRRODPB3P_VOTk6PoILVCAuth "Short Range Radar Side Right Rear Object Detection and Processing Burst 3 Protected : Vehicle Object Track 6 Point of Interest Lateral Velocity Covariance Authenticated";
BA_ "SignalLongName" SG_ 220 SRRSRRODPB3P_VOTk7CICOPotAuth "Short Range Radar Side Right Rear Object Detection and Processing Burst 3 Protected : Vehicle Object Track 7 Cut In Cut Out Potential Authenticated";
BA_ "SignalType" SG_ 220 SRRSRRODPB3P_VOTk6TypCnfdAuth "ENM";
BA_ "SignalLongName" SG_ 220 SRRSRRODPB3P_VOTk6TypCnfdAuth "Short Range Radar Side Right Rear Object Detection and Processing Burst 3 Protected : Vehicle Object Track 6 Type Confidence Authenticated";
BA_ "SignalType" SG_ 220 SRRSRRODPB3P_VOTk7DynPrpStsAuth "ENM";
BA_ "SignalLongName" SG_ 220 SRRSRRODPB3P_VOTk7DynPrpStsAuth "Short Range Radar Side Right Rear Object Detection and Processing Burst 3 Protected : Vehicle Object Track 7 Dynamic Property Status Authenticated";
BA_ "SignalType" SG_ 220 SRRSRRODPB3P_VOTk7DynPrpAuth "ENM";
BA_ "SignalLongName" SG_ 220 SRRSRRODPB3P_VOTk7DynPrpAuth "Short Range Radar Side Right Rear Object Detection and Processing Burst 3 Protected : Vehicle Object Track 7 Dynamic Property Authenticated";
BA_ "SignalType" SG_ 220 SRRSRRODPB3P_VOTk7CnfdStsAuth "ENM";
BA_ "SignalLongName" SG_ 220 SRRSRRODPB3P_VOTk7CnfdStsAuth "Short Range Radar Side Right Rear Object Detection and Processing Burst 3 Protected : Vehicle Object Track 7 Confidence Status Authenticated";
BA_ "SignalType" SG_ 220 SRRSRRODPB3P_VOTk7MStsAuth "ENM";
BA_ "SignalLongName" SG_ 220 SRRSRRODPB3P_VOTk7MStsAuth "Short Range Radar Side Right Rear Object Detection and Processing Burst 3 Protected : Vehicle Object Track 7 Measurement Status Authenticated";
BA_ "SignalLongName" SG_ 220 SRRSRRODPB3P_VOTk7IDAuth "Short Range Radar Side Right Rear Object Detection and Processing Burst 3 Protected : Vehicle Object Track 7 ID Authenticated";
BA_ "SignalLongName" SG_ 220 SRRSRRODPB3P_VOTk7PoILAAuth "Short Range Radar Side Right Rear Object Detection and Processing Burst 3 Protected : Vehicle Object Track 7 Point of Interest Lateral Acceleration Authenticated";
BA_ "SignalLongName" SG_ 220 SRRSRRODPB3P_VOTk7PoILgAAuth "Short Range Radar Side Right Rear Object Detection and Processing Burst 3 Protected : Vehicle Object Track 7 Point of Interest Longitudinal Acceleration Authenticated";
BA_ "SignalLongName" SG_ 220 SRRSRRODPB3P_VOTk7PoILgPsAuth "Short Range Radar Side Right Rear Object Detection and Processing Burst 3 Protected : Vehicle Object Track 7 Point of Interest Longitudinal Position Authenticated";
BA_ "SignalLongName" SG_ 220 SRRSRRODPB3P_VOTk7PoILgPsCAuth "Short Range Radar Side Right Rear Object Detection and Processing Burst 3 Protected : Vehicle Object Track 7 Point of Interest Longitudinal Position Covariance Authenticated";
BA_ "SignalLongName" SG_ 220 SRRSRRODPB3P_VOTk7PoILgthAuth "Short Range Radar Side Right Rear Object Detection and Processing Burst 3 Protected : Vehicle Object Track 7 Point of Interest Length Authenticated";
BA_ "SignalLongName" SG_ 220 SRRSRRODPB3P_VOTk7PoILgVAuth "Short Range Radar Side Right Rear Object Detection and Processing Burst 3 Protected : Vehicle Object Track 7 Point of Interest Longitudinal Velocity Authenticated";
BA_ "SignalLongName" SG_ 220 SRRSRRODPB3P_VOTk7PoILgVCAuth "Short Range Radar Side Right Rear Object Detection and Processing Burst 3 Protected : Vehicle Object Track 7 Point of Interest Longitudinal Velocity Covariance Authenticated";
BA_ "SignalLongName" SG_ 220 SRRSRRODPB3P_VOTk7PoILPsAuth "Short Range Radar Side Right Rear Object Detection and Processing Burst 3 Protected : Vehicle Object Track 7 Point of Interest Lateral Position Authenticated";
BA_ "SignalLongName" SG_ 220 SRRSRRODPB3P_VOTk7PoILPsCAuth "Short Range Radar Side Right Rear Object Detection and Processing Burst 3 Protected : Vehicle Object Track 7 Point of Interest Lateral Position Covariance Authenticated";
BA_ "SignalLongName" SG_ 220 SRRSRRODPB3P_VOTk7PoILVAuth "Short Range Radar Side Right Rear Object Detection and Processing Burst 3 Protected : Vehicle Object Track 7 Point of Interest Lateral Velocity Authenticated";
BA_ "SignalLongName" SG_ 220 SRRSRRODPB3P_VOTk7PoILVCAuth "Short Range Radar Side Right Rear Object Detection and Processing Burst 3 Protected : Vehicle Object Track 7 Point of Interest Lateral Velocity Covariance Authenticated";
BA_ "SignalType" SG_ 220 SRRSRRODPB3P_VOTk7TypCnfdAuth "ENM";
BA_ "SignalLongName" SG_ 220 SRRSRRODPB3P_VOTk7TypCnfdAuth "Short Range Radar Side Right Rear Object Detection and Processing Burst 3 Protected : Vehicle Object Track 7 Type Confidence Authenticated";
BA_ "SignalLongName" SG_ 220 SRRSRRODPB3P_VOTk8PoILgthAuth "Short Range Radar Side Right Rear Object Detection and Processing Burst 3 Protected : Vehicle Object Track 8 Point of Interest Length Authenticated";
BA_ "SignalLongName" SG_ 221 SRRSRRODPB4P_POTk5IDAuth "Short Range Radar Side Right Rear Object Detection and Processing Burst 4 Protected : Pedestrian Object Track 5 ID Authenticated";
BA_ "SignalType" SG_ 221 SRRSRRODPB4P_POTk5DynPrpAuth "ENM";
BA_ "SignalLongName" SG_ 221 SRRSRRODPB4P_POTk5DynPrpAuth "Short Range Radar Side Right Rear Object Detection and Processing Burst 4 Protected : Pedestrian Object Track 5 Dynamic Property Authenticated";
BA_ "SignalType" SG_ 221 SRRSRRODPB4P_POTk5CnfdStsAuth "ENM";
BA_ "SignalLongName" SG_ 221 SRRSRRODPB4P_POTk5CnfdStsAuth "Short Range Radar Side Right Rear Object Detection and Processing Burst 4 Protected : Pedestrian Object Track 5 Confidence Status Authenticated";
BA_ "SignalLongName" SG_ 221 SRRSRRODPB4P_BrstID "Short Range Radar Side Right Rear Object Detection and Processing Burst 4 Protected : Burst ID";
BA_ "SignalLongName" SG_ 221 SRRSRRODPB4P_POTk5InPthPotAuth "Short Range Radar Side Right Rear Object Detection and Processing Burst 4 Protected : Pedestrian Object Track 5 In Path Potential Authenticated";
BA_ "SignalLongName" SG_ 221 SRRSRRODPB4P_POTk5PoILAAuth "Short Range Radar Side Right Rear Object Detection and Processing Burst 4 Protected : Pedestrian Object Track 5 Point of Interest Lateral Acceleration Authenticated";
BA_ "SignalType" SG_ 221 SRRSRRODPB4P_POTk5MStsAuth "ENM";
BA_ "SignalLongName" SG_ 221 SRRSRRODPB4P_POTk5MStsAuth "Short Range Radar Side Right Rear Object Detection and Processing Burst 4 Protected : Pedestrian Object Track 5 Measurement Status Authenticated";
BA_ "SignalLongName" SG_ 221 SRRSRRODPB4P_POTk5PoILgAAuth "Short Range Radar Side Right Rear Object Detection and Processing Burst 4 Protected : Pedestrian Object Track 5 Point of Interest Longitudinal Acceleration Authenticated";
BA_ "SignalLongName" SG_ 221 SRRSRRODPB4P_POTk5PoILgPsAuth "Short Range Radar Side Right Rear Object Detection and Processing Burst 4 Protected : Pedestrian Object Track 5 Point of Interest Longitudinal Position Authenticated";
BA_ "SignalLongName" SG_ 221 SRRSRRODPB4P_POTk5PoILgVAuth "Short Range Radar Side Right Rear Object Detection and Processing Burst 4 Protected : Pedestrian Object Track 5 Point of Interest Longitudinal Velocity Authenticated";
BA_ "SignalLongName" SG_ 221 SRRSRRODPB4P_POTk5PoILPsAuth "Short Range Radar Side Right Rear Object Detection and Processing Burst 4 Protected : Pedestrian Object Track 5 Point of Interest Lateral Position Authenticated";
BA_ "SignalLongName" SG_ 221 SRRSRRODPB4P_POTk5PoILVAuth "Short Range Radar Side Right Rear Object Detection and Processing Burst 4 Protected : Pedestrian Object Track 5 Point of Interest Lateral Velocity Authenticated";
BA_ "SignalLongName" SG_ 221 SRRSRRODPB4P_VOTk10CICOPotAuth "Short Range Radar Side Right Rear Object Detection and Processing Burst 4 Protected : Vehicle Object Track 10 Cut In Cut Out Potential Authenticated";
BA_ "SignalType" SG_ 221 SRRSRRODPB4P_POTk5TypCnfdAuth "ENM";
BA_ "SignalLongName" SG_ 221 SRRSRRODPB4P_POTk5TypCnfdAuth "Short Range Radar Side Right Rear Object Detection and Processing Burst 4 Protected : Pedestrian Object Track 5 Type Confidence Authenticated";
BA_ "SignalType" SG_ 221 SRRSRRODPB4P_POTk5TypAuth "ENM";
BA_ "SignalLongName" SG_ 221 SRRSRRODPB4P_POTk5TypAuth "Short Range Radar Side Right Rear Object Detection and Processing Burst 4 Protected : Pedestrian Object Track 5 Type Authenticated";
BA_ "SignalType" SG_ 221 SRRSRRODPB4P_VOTk10DynPrpStAuth "ENM";
BA_ "SignalLongName" SG_ 221 SRRSRRODPB4P_VOTk10DynPrpStAuth "Short Range Radar Side Right Rear Object Detection and Processing Burst 4 Protected : Vehicle Object Track 10 Dynamic Property Status Authenticated";
BA_ "SignalType" SG_ 221 SRRSRRODPB4P_VOTk10DynPrpAuth "ENM";
BA_ "SignalLongName" SG_ 221 SRRSRRODPB4P_VOTk10DynPrpAuth "Short Range Radar Side Right Rear Object Detection and Processing Burst 4 Protected : Vehicle Object Track 10 Dynamic Property Authenticated";
BA_ "SignalType" SG_ 221 SRRSRRODPB4P_VOTk10CnfdStsAuth "ENM";
BA_ "SignalLongName" SG_ 221 SRRSRRODPB4P_VOTk10CnfdStsAuth "Short Range Radar Side Right Rear Object Detection and Processing Burst 4 Protected : Vehicle Object Track 10 Confidence Status Authenticated";
BA_ "SignalType" SG_ 221 SRRSRRODPB4P_VOTk10MStsAuth "ENM";
BA_ "SignalLongName" SG_ 221 SRRSRRODPB4P_VOTk10MStsAuth "Short Range Radar Side Right Rear Object Detection and Processing Burst 4 Protected : Vehicle Object Track 10 Measurement Status Authenticated";
BA_ "SignalLongName" SG_ 221 SRRSRRODPB4P_VOTk10IDAuth "Short Range Radar Side Right Rear Object Detection and Processing Burst 4 Protected : Vehicle Object Track 10 ID Authenticated";
BA_ "SignalLongName" SG_ 221 SRRSRRODPB4P_VOTk10PoILAAuth "Short Range Radar Side Right Rear Object Detection and Processing Burst 4 Protected : Vehicle Object Track 10 Point of Interest Lateral Acceleration Authenticated";
BA_ "SignalLongName" SG_ 221 SRRSRRODPB4P_VOTk10PoILgAAuth "Short Range Radar Side Right Rear Object Detection and Processing Burst 4 Protected : Vehicle Object Track 10 Point of Interest Longitudinal Acceleration Authenticated";
BA_ "SignalLongName" SG_ 221 SRRSRRODPB4P_VOTk10PoILgPsAuth "Short Range Radar Side Right Rear Object Detection and Processing Burst 4 Protected : Vehicle Object Track 10 Point of Interest Longitudinal Position Authenticated";
BA_ "SignalLongName" SG_ 221 SRRSRRODPB4P_VOTk10PoILgPsCAuth "Short Range Radar Side Right Rear Object Detection and Processing Burst 4 Protected : Vehicle Object Track 10 Point of Interest Longitudinal Position Covariance Authenticated";
BA_ "SignalLongName" SG_ 221 SRRSRRODPB4P_VOTk10PoILgthAuth "Short Range Radar Side Right Rear Object Detection and Processing Burst 4 Protected : Vehicle Object Track 10 Point of Interest Length Authenticated";
BA_ "SignalLongName" SG_ 221 SRRSRRODPB4P_VOTk10PoILgVAuth "Short Range Radar Side Right Rear Object Detection and Processing Burst 4 Protected : Vehicle Object Track 10 Point of Interest Longitudinal Velocity Authenticated";
BA_ "SignalLongName" SG_ 221 SRRSRRODPB4P_VOTk10PoILgVCAuth "Short Range Radar Side Right Rear Object Detection and Processing Burst 4 Protected : Vehicle Object Track 10 Point of Interest Longitudinal Velocity Covariance Authenticated";
BA_ "SignalLongName" SG_ 221 SRRSRRODPB4P_VOTk10PoILPsAuth "Short Range Radar Side Right Rear Object Detection and Processing Burst 4 Protected : Vehicle Object Track 10 Point of Interest Lateral Position Authenticated";
BA_ "SignalLongName" SG_ 221 SRRSRRODPB4P_VOTk10PoILPsCAuth "Short Range Radar Side Right Rear Object Detection and Processing Burst 4 Protected : Vehicle Object Track 10 Point of Interest Lateral Position Covariance Authenticated";
BA_ "SignalLongName" SG_ 221 SRRSRRODPB4P_VOTk10PoILVAuth "Short Range Radar Side Right Rear Object Detection and Processing Burst 4 Protected : Vehicle Object Track 10 Point of Interest Lateral Velocity Authenticated";
BA_ "SignalLongName" SG_ 221 SRRSRRODPB4P_VOTk10PoILVCAuth "Short Range Radar Side Right Rear Object Detection and Processing Burst 4 Protected : Vehicle Object Track 10 Point of Interest Lateral Velocity Covariance Authenticated";
BA_ "SignalType" SG_ 221 SRRSRRODPB4P_VOTk10TypCnfdAuth "ENM";
BA_ "SignalLongName" SG_ 221 SRRSRRODPB4P_VOTk10TypCnfdAuth "Short Range Radar Side Right Rear Object Detection and Processing Burst 4 Protected : Vehicle Object Track 10 Type Confidence Authenticated";
BA_ "SignalType" SG_ 221 SRRSRRODPB4P_VOTk8CnfdStsAuth "ENM";
BA_ "SignalLongName" SG_ 221 SRRSRRODPB4P_VOTk8CnfdStsAuth "Short Range Radar Side Right Rear Object Detection and Processing Burst 4 Protected : Vehicle Object Track 8 Confidence Status Authenticated";
BA_ "SignalLongName" SG_ 221 SRRSRRODPB4P_VOTk8CICOPotAuth "Short Range Radar Side Right Rear Object Detection and Processing Burst 4 Protected : Vehicle Object Track 8 Cut In Cut Out Potential Authenticated";
BA_ "SignalLongName" SG_ 221 SRRSRRODPB4P_VOTk8IDAuth "Short Range Radar Side Right Rear Object Detection and Processing Burst 4 Protected : Vehicle Object Track 8 ID Authenticated";
BA_ "SignalType" SG_ 221 SRRSRRODPB4P_VOTk8DynPrpStsAuth "ENM";
BA_ "SignalLongName" SG_ 221 SRRSRRODPB4P_VOTk8DynPrpStsAuth "Short Range Radar Side Right Rear Object Detection and Processing Burst 4 Protected : Vehicle Object Track 8 Dynamic Property Status Authenticated";
BA_ "SignalType" SG_ 221 SRRSRRODPB4P_VOTk8DynPrpAuth "ENM";
BA_ "SignalLongName" SG_ 221 SRRSRRODPB4P_VOTk8DynPrpAuth "Short Range Radar Side Right Rear Object Detection and Processing Burst 4 Protected : Vehicle Object Track 8 Dynamic Property Authenticated";
BA_ "SignalLongName" SG_ 221 SRRSRRODPB4P_VOTk8PoILAAuth "Short Range Radar Side Right Rear Object Detection and Processing Burst 4 Protected : Vehicle Object Track 8 Point of Interest Lateral Acceleration Authenticated";
BA_ "SignalType" SG_ 221 SRRSRRODPB4P_VOTk8MStsAuth "ENM";
BA_ "SignalLongName" SG_ 221 SRRSRRODPB4P_VOTk8MStsAuth "Short Range Radar Side Right Rear Object Detection and Processing Burst 4 Protected : Vehicle Object Track 8 Measurement Status Authenticated";
BA_ "SignalLongName" SG_ 221 SRRSRRODPB4P_VOTk8PoILgAAuth "Short Range Radar Side Right Rear Object Detection and Processing Burst 4 Protected : Vehicle Object Track 8 Point of Interest Longitudinal Acceleration Authenticated";
BA_ "SignalLongName" SG_ 221 SRRSRRODPB4P_VOTk8PoILgPsAuth "Short Range Radar Side Right Rear Object Detection and Processing Burst 4 Protected : Vehicle Object Track 8 Point of Interest Longitudinal Position Authenticated";
BA_ "SignalLongName" SG_ 221 SRRSRRODPB4P_VOTk8PoILgPsCAuth "Short Range Radar Side Right Rear Object Detection and Processing Burst 4 Protected : Vehicle Object Track 8 Point of Interest Longitudinal Position Covariance Authenticated";
BA_ "SignalLongName" SG_ 221 SRRSRRODPB4P_VOTk8PoILgVAuth "Short Range Radar Side Right Rear Object Detection and Processing Burst 4 Protected : Vehicle Object Track 8 Point of Interest Longitudinal Velocity Authenticated";
BA_ "SignalLongName" SG_ 221 SRRSRRODPB4P_VOTk8PoILgVCAuth "Short Range Radar Side Right Rear Object Detection and Processing Burst 4 Protected : Vehicle Object Track 8 Point of Interest Longitudinal Velocity Covariance Authenticated";
BA_ "SignalLongName" SG_ 221 SRRSRRODPB4P_VOTk8PoILPsAuth "Short Range Radar Side Right Rear Object Detection and Processing Burst 4 Protected : Vehicle Object Track 8 Point of Interest Lateral Position Authenticated";
BA_ "SignalLongName" SG_ 221 SRRSRRODPB4P_VOTk8PoILPsCAuth "Short Range Radar Side Right Rear Object Detection and Processing Burst 4 Protected : Vehicle Object Track 8 Point of Interest Lateral Position Covariance Authenticated";
BA_ "SignalLongName" SG_ 221 SRRSRRODPB4P_VOTk8PoILVAuth "Short Range Radar Side Right Rear Object Detection and Processing Burst 4 Protected : Vehicle Object Track 8 Point of Interest Lateral Velocity Authenticated";
BA_ "SignalLongName" SG_ 221 SRRSRRODPB4P_VOTk8PoILVCAuth "Short Range Radar Side Right Rear Object Detection and Processing Burst 4 Protected : Vehicle Object Track 8 Point of Interest Lateral Velocity Covariance Authenticated";
BA_ "SignalLongName" SG_ 221 SRRSRRODPB4P_VOTk9CICOPotAuth "Short Range Radar Side Right Rear Object Detection and Processing Burst 4 Protected : Vehicle Object Track 9 Cut In Cut Out Potential Authenticated";
BA_ "SignalType" SG_ 221 SRRSRRODPB4P_VOTk8TypCnfdAuth "ENM";
BA_ "SignalLongName" SG_ 221 SRRSRRODPB4P_VOTk8TypCnfdAuth "Short Range Radar Side Right Rear Object Detection and Processing Burst 4 Protected : Vehicle Object Track 8 Type Confidence Authenticated";
BA_ "SignalType" SG_ 221 SRRSRRODPB4P_VOTk9DynPrpStsAuth "ENM";
BA_ "SignalLongName" SG_ 221 SRRSRRODPB4P_VOTk9DynPrpStsAuth "Short Range Radar Side Right Rear Object Detection and Processing Burst 4 Protected : Vehicle Object Track 9 Dynamic Property Status Authenticated";
BA_ "SignalType" SG_ 221 SRRSRRODPB4P_VOTk9DynPrpAuth "ENM";
BA_ "SignalLongName" SG_ 221 SRRSRRODPB4P_VOTk9DynPrpAuth "Short Range Radar Side Right Rear Object Detection and Processing Burst 4 Protected : Vehicle Object Track 9 Dynamic Property Authenticated";
BA_ "SignalType" SG_ 221 SRRSRRODPB4P_VOTk9CnfdStsAuth "ENM";
BA_ "SignalLongName" SG_ 221 SRRSRRODPB4P_VOTk9CnfdStsAuth "Short Range Radar Side Right Rear Object Detection and Processing Burst 4 Protected : Vehicle Object Track 9 Confidence Status Authenticated";
BA_ "SignalType" SG_ 221 SRRSRRODPB4P_VOTk9MStsAuth "ENM";
BA_ "SignalLongName" SG_ 221 SRRSRRODPB4P_VOTk9MStsAuth "Short Range Radar Side Right Rear Object Detection and Processing Burst 4 Protected : Vehicle Object Track 9 Measurement Status Authenticated";
BA_ "SignalLongName" SG_ 221 SRRSRRODPB4P_VOTk9IDAuth "Short Range Radar Side Right Rear Object Detection and Processing Burst 4 Protected : Vehicle Object Track 9 ID Authenticated";
BA_ "SignalLongName" SG_ 221 SRRSRRODPB4P_VOTk9PoILAAuth "Short Range Radar Side Right Rear Object Detection and Processing Burst 4 Protected : Vehicle Object Track 9 Point of Interest Lateral Acceleration Authenticated";
BA_ "SignalLongName" SG_ 221 SRRSRRODPB4P_VOTk9PoILgAAuth "Short Range Radar Side Right Rear Object Detection and Processing Burst 4 Protected : Vehicle Object Track 9 Point of Interest Longitudinal Acceleration Authenticated";
BA_ "SignalLongName" SG_ 221 SRRSRRODPB4P_VOTk9PoILgPsAuth "Short Range Radar Side Right Rear Object Detection and Processing Burst 4 Protected : Vehicle Object Track 9 Point of Interest Longitudinal Position Authenticated";
BA_ "SignalLongName" SG_ 221 SRRSRRODPB4P_VOTk9PoILgPsCAuth "Short Range Radar Side Right Rear Object Detection and Processing Burst 4 Protected : Vehicle Object Track 9 Point of Interest Longitudinal Position Covariance Authenticated";
BA_ "SignalLongName" SG_ 221 SRRSRRODPB4P_VOTk9PoILgthAuth "Short Range Radar Side Right Rear Object Detection and Processing Burst 4 Protected : Vehicle Object Track 9 Point of Interest Length Authenticated";
BA_ "SignalLongName" SG_ 221 SRRSRRODPB4P_VOTk9PoILgVAuth "Short Range Radar Side Right Rear Object Detection and Processing Burst 4 Protected : Vehicle Object Track 9 Point of Interest Longitudinal Velocity Authenticated";
BA_ "SignalLongName" SG_ 221 SRRSRRODPB4P_VOTk9PoILgVCAuth "Short Range Radar Side Right Rear Object Detection and Processing Burst 4 Protected : Vehicle Object Track 9 Point of Interest Longitudinal Velocity Covariance Authenticated";
BA_ "SignalLongName" SG_ 221 SRRSRRODPB4P_VOTk9PoILPsAuth "Short Range Radar Side Right Rear Object Detection and Processing Burst 4 Protected : Vehicle Object Track 9 Point of Interest Lateral Position Authenticated";
BA_ "SignalLongName" SG_ 221 SRRSRRODPB4P_VOTk9PoILPsCAuth "Short Range Radar Side Right Rear Object Detection and Processing Burst 4 Protected : Vehicle Object Track 9 Point of Interest Lateral Position Covariance Authenticated";
BA_ "SignalLongName" SG_ 221 SRRSRRODPB4P_VOTk9PoILVAuth "Short Range Radar Side Right Rear Object Detection and Processing Burst 4 Protected : Vehicle Object Track 9 Point of Interest Lateral Velocity Authenticated";
BA_ "SignalLongName" SG_ 221 SRRSRRODPB4P_VOTk9PoILVCAuth "Short Range Radar Side Right Rear Object Detection and Processing Burst 4 Protected : Vehicle Object Track 9 Point of Interest Lateral Velocity Covariance Authenticated";
BA_ "SignalType" SG_ 221 SRRSRRODPB4P_VOTk9TypCnfdAuth "ENM";
BA_ "SignalLongName" SG_ 221 SRRSRRODPB4P_VOTk9TypCnfdAuth "Short Range Radar Side Right Rear Object Detection and Processing Burst 4 Protected : Vehicle Object Track 9 Type Confidence Authenticated";
BA_ "SignalLongName" SG_ 222 SRRSRRODPB5P_IOTk10IDAuth "Short Range Radar Side Right Rear Object Detection and Processing Burst 5 Protected : Infrastructure Object Track 10 ID Authenticated";
BA_ "SignalType" SG_ 222 SRRSRRODPB5P_IOTk10ElvtnAuth "ENM";
BA_ "SignalLongName" SG_ 222 SRRSRRODPB5P_IOTk10ElvtnAuth "Short Range Radar Side Right Rear Object Detection and Processing Burst 5 Protected : Infrastructure Object Track 10 Elevation Authenticated";
BA_ "SignalType" SG_ 222 SRRSRRODPB5P_IOTk10CnfdStsAuth "ENM";
BA_ "SignalLongName" SG_ 222 SRRSRRODPB5P_IOTk10CnfdStsAuth "Short Range Radar Side Right Rear Object Detection and Processing Burst 5 Protected : Infrastructure Object Track 10 Confidence Status Authenticated";
BA_ "SignalLongName" SG_ 222 SRRSRRODPB5P_BrstID "Short Range Radar Side Right Rear Object Detection and Processing Burst 5 Protected : Burst ID";
BA_ "SignalLongName" SG_ 222 SRRSRRODPB5P_IOTk10PolLgPsAuth "Short Range Radar Side Right Rear Object Detection and Processing Burst 5 Protected : Infrastructure Object Track 10 Point of Interest Longitudinal Position Authenticated";
BA_ "SignalType" SG_ 222 SRRSRRODPB5P_IOTk10MStsAuth "ENM";
BA_ "SignalLongName" SG_ 222 SRRSRRODPB5P_IOTk10MStsAuth "Short Range Radar Side Right Rear Object Detection and Processing Burst 5 Protected : Infrastructure Object Track 10 Measurement Status Authenticated";
BA_ "SignalType" SG_ 222 SRRSRRODPB5P_IOTk1CnfdStsAuth "ENM";
BA_ "SignalLongName" SG_ 222 SRRSRRODPB5P_IOTk1CnfdStsAuth "Short Range Radar Side Right Rear Object Detection and Processing Burst 5 Protected : Infrastructure Object Track 1 Confidence Status Authenticated";
BA_ "SignalType" SG_ 222 SRRSRRODPB5P_IOTk10TypCnfdAuth "ENM";
BA_ "SignalLongName" SG_ 222 SRRSRRODPB5P_IOTk10TypCnfdAuth "Short Range Radar Side Right Rear Object Detection and Processing Burst 5 Protected : Infrastructure Object Track 10 Type Confidence Authenticated";
BA_ "SignalType" SG_ 222 SRRSRRODPB5P_IOTk10TypAuth "ENM";
BA_ "SignalLongName" SG_ 222 SRRSRRODPB5P_IOTk10TypAuth "Short Range Radar Side Right Rear Object Detection and Processing Burst 5 Protected : Infrastructure Object Track 10 Type Authenticated";
BA_ "SignalLongName" SG_ 222 SRRSRRODPB5P_IOTk1IDAuth "Short Range Radar Side Right Rear Object Detection and Processing Burst 5 Protected : Infrastructure Object Track 1 ID Authenticated";
BA_ "SignalType" SG_ 222 SRRSRRODPB5P_IOTk1ElvtnAuth "ENM";
BA_ "SignalLongName" SG_ 222 SRRSRRODPB5P_IOTk1ElvtnAuth "Short Range Radar Side Right Rear Object Detection and Processing Burst 5 Protected : Infrastructure Object Track 1 Elevation Authenticated";
BA_ "SignalLongName" SG_ 222 SRRSRRODPB5P_IOTk1PoILgPsAuth "Short Range Radar Side Right Rear Object Detection and Processing Burst 5 Protected : Infrastructure Object Track 1 Point of Interest Longitudinal Position Authenticated";
BA_ "SignalType" SG_ 222 SRRSRRODPB5P_IOTk1MStsAuth "ENM";
BA_ "SignalLongName" SG_ 222 SRRSRRODPB5P_IOTk1MStsAuth "Short Range Radar Side Right Rear Object Detection and Processing Burst 5 Protected : Infrastructure Object Track 1 Measurement Status Authenticated";
BA_ "SignalType" SG_ 222 SRRSRRODPB5P_IOTk1TypAuth "ENM";
BA_ "SignalLongName" SG_ 222 SRRSRRODPB5P_IOTk1TypAuth "Short Range Radar Side Right Rear Object Detection and Processing Burst 5 Protected : Infrastructure Object Track 1 Type Authenticated";
BA_ "SignalType" SG_ 222 SRRSRRODPB5P_IOTk2ElvtnAuth "ENM";
BA_ "SignalLongName" SG_ 222 SRRSRRODPB5P_IOTk2ElvtnAuth "Short Range Radar Side Right Rear Object Detection and Processing Burst 5 Protected : Infrastructure Object Track 2 Elevation Authenticated";
BA_ "SignalType" SG_ 222 SRRSRRODPB5P_IOTk2CnfdStsAuth "ENM";
BA_ "SignalLongName" SG_ 222 SRRSRRODPB5P_IOTk2CnfdStsAuth "Short Range Radar Side Right Rear Object Detection and Processing Burst 5 Protected : Infrastructure Object Track 2 Confidence Status Authenticated";
BA_ "SignalType" SG_ 222 SRRSRRODPB5P_IOTk1TypCnfdAuth "ENM";
BA_ "SignalLongName" SG_ 222 SRRSRRODPB5P_IOTk1TypCnfdAuth "Short Range Radar Side Right Rear Object Detection and Processing Burst 5 Protected : Infrastructure Object Track 1 Type Confidence Authenticated";
BA_ "SignalType" SG_ 222 SRRSRRODPB5P_IOTk2MStsAuth "ENM";
BA_ "SignalLongName" SG_ 222 SRRSRRODPB5P_IOTk2MStsAuth "Short Range Radar Side Right Rear Object Detection and Processing Burst 5 Protected : Infrastructure Object Track 2 Measurement Status Authenticated";
BA_ "SignalLongName" SG_ 222 SRRSRRODPB5P_IOTk2IDAuth "Short Range Radar Side Right Rear Object Detection and Processing Burst 5 Protected : Infrastructure Object Track 2 ID Authenticated";
BA_ "SignalLongName" SG_ 222 SRRSRRODPB5P_IOTk2PolLgPsAuth "Short Range Radar Side Right Rear Object Detection and Processing Burst 5 Protected : Infrastructure Object Track 2 Point of Interest Longitudinal Position Authenticated";
BA_ "SignalType" SG_ 222 SRRSRRODPB5P_IOTk2TypCnfdAuth "ENM";
BA_ "SignalLongName" SG_ 222 SRRSRRODPB5P_IOTk2TypCnfdAuth "Short Range Radar Side Right Rear Object Detection and Processing Burst 5 Protected : Infrastructure Object Track 2 Type Confidence Authenticated";
BA_ "SignalType" SG_ 222 SRRSRRODPB5P_IOTk2TypAuth "ENM";
BA_ "SignalLongName" SG_ 222 SRRSRRODPB5P_IOTk2TypAuth "Short Range Radar Side Right Rear Object Detection and Processing Burst 5 Protected : Infrastructure Object Track 2 Type Authenticated";
BA_ "SignalLongName" SG_ 222 SRRSRRODPB5P_IOTk3IDAuth "Short Range Radar Side Right Rear Object Detection and Processing Burst 5 Protected : Infrastructure Object Track 3 ID Authenticated";
BA_ "SignalType" SG_ 222 SRRSRRODPB5P_IOTk3ElvtnAuth "ENM";
BA_ "SignalLongName" SG_ 222 SRRSRRODPB5P_IOTk3ElvtnAuth "Short Range Radar Side Right Rear Object Detection and Processing Burst 5 Protected : Infrastructure Object Track 3 Elevation Authenticated";
BA_ "SignalType" SG_ 222 SRRSRRODPB5P_IOTk3CnfdStsAuth "ENM";
BA_ "SignalLongName" SG_ 222 SRRSRRODPB5P_IOTk3CnfdStsAuth "Short Range Radar Side Right Rear Object Detection and Processing Burst 5 Protected : Infrastructure Object Track 3 Confidence Status Authenticated";
BA_ "SignalLongName" SG_ 222 SRRSRRODPB5P_IOTk3PolLgPsAuth "Short Range Radar Side Right Rear Object Detection and Processing Burst 5 Protected : Infrastructure Object Track 3 Point of Interest Longitudinal Position Authenticated";
BA_ "SignalType" SG_ 222 SRRSRRODPB5P_IOTk3MStsAuth "ENM";
BA_ "SignalLongName" SG_ 222 SRRSRRODPB5P_IOTk3MStsAuth "Short Range Radar Side Right Rear Object Detection and Processing Burst 5 Protected : Infrastructure Object Track 3 Measurement Status Authenticated";
BA_ "SignalType" SG_ 222 SRRSRRODPB5P_IOTk4CnfdStsAuth "ENM";
BA_ "SignalLongName" SG_ 222 SRRSRRODPB5P_IOTk4CnfdStsAuth "Short Range Radar Side Right Rear Object Detection and Processing Burst 5 Protected : Infrastructure Object Track 4 Confidence Status Authenticated";
BA_ "SignalType" SG_ 222 SRRSRRODPB5P_IOTk3TypCnfdAuth "ENM";
BA_ "SignalLongName" SG_ 222 SRRSRRODPB5P_IOTk3TypCnfdAuth "Short Range Radar Side Right Rear Object Detection and Processing Burst 5 Protected : Infrastructure Object Track 3 Type Confidence Authenticated";
BA_ "SignalType" SG_ 222 SRRSRRODPB5P_IOTk3TypAuth "ENM";
BA_ "SignalLongName" SG_ 222 SRRSRRODPB5P_IOTk3TypAuth "Short Range Radar Side Right Rear Object Detection and Processing Burst 5 Protected : Infrastructure Object Track 3 Type Authenticated";
BA_ "SignalLongName" SG_ 222 SRRSRRODPB5P_IOTk4IDAuth "Short Range Radar Side Right Rear Object Detection and Processing Burst 5 Protected : Infrastructure Object Track 4 ID Authenticated";
BA_ "SignalType" SG_ 222 SRRSRRODPB5P_IOTk4ElvtnAuth "ENM";
BA_ "SignalLongName" SG_ 222 SRRSRRODPB5P_IOTk4ElvtnAuth "Short Range Radar Side Right Rear Object Detection and Processing Burst 5 Protected : Infrastructure Object Track 4 Elevation Authenticated";
BA_ "SignalLongName" SG_ 222 SRRSRRODPB5P_IOTk4PolLgPsAuth "Short Range Radar Side Right Rear Object Detection and Processing Burst 5 Protected : Infrastructure Object Track 4 Point of Interest Longitudinal Position Authenticated";
BA_ "SignalType" SG_ 222 SRRSRRODPB5P_IOTk4MStsAuth "ENM";
BA_ "SignalLongName" SG_ 222 SRRSRRODPB5P_IOTk4MStsAuth "Short Range Radar Side Right Rear Object Detection and Processing Burst 5 Protected : Infrastructure Object Track 4 Measurement Status Authenticated";
BA_ "SignalType" SG_ 222 SRRSRRODPB5P_IOTk4TypAuth "ENM";
BA_ "SignalLongName" SG_ 222 SRRSRRODPB5P_IOTk4TypAuth "Short Range Radar Side Right Rear Object Detection and Processing Burst 5 Protected : Infrastructure Object Track 4 Type Authenticated";
BA_ "SignalLongName" SG_ 222 SRRSRRODPB5P_IOTk5IDAuth "Short Range Radar Side Right Rear Object Detection and Processing Burst 5 Protected : Infrastructure Object Track 5 ID Authenticated";
BA_ "SignalType" SG_ 222 SRRSRRODPB5P_IOTk5ElvtnAuth "ENM";
BA_ "SignalLongName" SG_ 222 SRRSRRODPB5P_IOTk5ElvtnAuth "Short Range Radar Side Right Rear Object Detection and Processing Burst 5 Protected : Infrastructure Object Track 5 Elevation Authenticated";
BA_ "SignalType" SG_ 222 SRRSRRODPB5P_IOTk5CnfdStsAuth "ENM";
BA_ "SignalLongName" SG_ 222 SRRSRRODPB5P_IOTk5CnfdStsAuth "Short Range Radar Side Right Rear Object Detection and Processing Burst 5 Protected : Infrastructure Object Track 5 Confidence Status Authenticated";
BA_ "SignalType" SG_ 222 SRRSRRODPB5P_IOTk4TypCnfdAuth "ENM";
BA_ "SignalLongName" SG_ 222 SRRSRRODPB5P_IOTk4TypCnfdAuth "Short Range Radar Side Right Rear Object Detection and Processing Burst 5 Protected : Infrastructure Object Track 4 Type Confidence Authenticated";
BA_ "SignalType" SG_ 222 SRRSRRODPB5P_IOTk5MStsAuth "ENM";
BA_ "SignalLongName" SG_ 222 SRRSRRODPB5P_IOTk5MStsAuth "Short Range Radar Side Right Rear Object Detection and Processing Burst 5 Protected : Infrastructure Object Track 5 Measurement Status Authenticated";
BA_ "SignalLongName" SG_ 222 SRRSRRODPB5P_IOTk5PolLgPsAuth "Short Range Radar Side Right Rear Object Detection and Processing Burst 5 Protected : Infrastructure Object Track 5 Point of Interest Longitudinal Position Authenticated";
BA_ "SignalType" SG_ 222 SRRSRRODPB5P_IOTk5TypCnfdAuth "ENM";
BA_ "SignalLongName" SG_ 222 SRRSRRODPB5P_IOTk5TypCnfdAuth "Short Range Radar Side Right Rear Object Detection and Processing Burst 5 Protected : Infrastructure Object Track 5 Type Confidence Authenticated";
BA_ "SignalType" SG_ 222 SRRSRRODPB5P_IOTk5TypAuth "ENM";
BA_ "SignalLongName" SG_ 222 SRRSRRODPB5P_IOTk5TypAuth "Short Range Radar Side Right Rear Object Detection and Processing Burst 5 Protected : Infrastructure Object Track 5 Type Authenticated";
BA_ "SignalLongName" SG_ 222 SRRSRRODPB5P_IOTk6IDAuth "Short Range Radar Side Right Rear Object Detection and Processing Burst 5 Protected : Infrastructure Object Track 6 ID Authenticated";
BA_ "SignalType" SG_ 222 SRRSRRODPB5P_IOTk6ElvtnAuth "ENM";
BA_ "SignalLongName" SG_ 222 SRRSRRODPB5P_IOTk6ElvtnAuth "Short Range Radar Side Right Rear Object Detection and Processing Burst 5 Protected : Infrastructure Object Track 6 Elevation Authenticated";
BA_ "SignalType" SG_ 222 SRRSRRODPB5P_IOTk6CnfdStsAuth "ENM";
BA_ "SignalLongName" SG_ 222 SRRSRRODPB5P_IOTk6CnfdStsAuth "Short Range Radar Side Right Rear Object Detection and Processing Burst 5 Protected : Infrastructure Object Track 6 Confidence Status Authenticated";
BA_ "SignalLongName" SG_ 222 SRRSRRODPB5P_IOTk6PolLgPsAuth "Short Range Radar Side Right Rear Object Detection and Processing Burst 5 Protected : Infrastructure Object Track 6 Point of Interest Longitudinal Position Authenticated";
BA_ "SignalType" SG_ 222 SRRSRRODPB5P_IOTk6MStsAuth "ENM";
BA_ "SignalLongName" SG_ 222 SRRSRRODPB5P_IOTk6MStsAuth "Short Range Radar Side Right Rear Object Detection and Processing Burst 5 Protected : Infrastructure Object Track 6 Measurement Status Authenticated";
BA_ "SignalType" SG_ 222 SRRSRRODPB5P_IOTk7ElvtnAuth "ENM";
BA_ "SignalLongName" SG_ 222 SRRSRRODPB5P_IOTk7ElvtnAuth "Short Range Radar Side Right Rear Object Detection and Processing Burst 5 Protected : Infrastructure Object Track 7 Elevation Authenticated";
BA_ "SignalType" SG_ 222 SRRSRRODPB5P_IOTk7CnfdStsAuth "ENM";
BA_ "SignalLongName" SG_ 222 SRRSRRODPB5P_IOTk7CnfdStsAuth "Short Range Radar Side Right Rear Object Detection and Processing Burst 5 Protected : Infrastructure Object Track 7 Confidence Status Authenticated";
BA_ "SignalType" SG_ 222 SRRSRRODPB5P_IOTk6TypCnfdAuth "ENM";
BA_ "SignalLongName" SG_ 222 SRRSRRODPB5P_IOTk6TypCnfdAuth "Short Range Radar Side Right Rear Object Detection and Processing Burst 5 Protected : Infrastructure Object Track 6 Type Confidence Authenticated";
BA_ "SignalType" SG_ 222 SRRSRRODPB5P_IOTk6TypAuth "ENM";
BA_ "SignalLongName" SG_ 222 SRRSRRODPB5P_IOTk6TypAuth "Short Range Radar Side Right Rear Object Detection and Processing Burst 5 Protected : Infrastructure Object Track 6 Type Authenticated";
BA_ "SignalLongName" SG_ 222 SRRSRRODPB5P_IOTk7IDAuth "Short Range Radar Side Right Rear Object Detection and Processing Burst 5 Protected : Infrastructure Object Track 7 ID Authenticated";
BA_ "SignalLongName" SG_ 222 SRRSRRODPB5P_IOTk7PolLgPsAuth "Short Range Radar Side Right Rear Object Detection and Processing Burst 5 Protected : Infrastructure Object Track 7 Point of Interest Longitudinal Position Authenticated";
BA_ "SignalType" SG_ 222 SRRSRRODPB5P_IOTk7MStsAuth "ENM";
BA_ "SignalLongName" SG_ 222 SRRSRRODPB5P_IOTk7MStsAuth "Short Range Radar Side Right Rear Object Detection and Processing Burst 5 Protected : Infrastructure Object Track 7 Measurement Status Authenticated";
BA_ "SignalType" SG_ 222 SRRSRRODPB5P_IOTk7TypAuth "ENM";
BA_ "SignalLongName" SG_ 222 SRRSRRODPB5P_IOTk7TypAuth "Short Range Radar Side Right Rear Object Detection and Processing Burst 5 Protected : Infrastructure Object Track 7 Type Authenticated";
BA_ "SignalLongName" SG_ 222 SRRSRRODPB5P_IOTk8IDAuth "Short Range Radar Side Right Rear Object Detection and Processing Burst 5 Protected : Infrastructure Object Track 8 ID Authenticated";
BA_ "SignalType" SG_ 222 SRRSRRODPB5P_IOTk8ElvtnAuth "ENM";
BA_ "SignalLongName" SG_ 222 SRRSRRODPB5P_IOTk8ElvtnAuth "Short Range Radar Side Right Rear Object Detection and Processing Burst 5 Protected : Infrastructure Object Track 8 Elevation Authenticated";
BA_ "SignalType" SG_ 222 SRRSRRODPB5P_IOTk8CnfdStsAuth "ENM";
BA_ "SignalLongName" SG_ 222 SRRSRRODPB5P_IOTk8CnfdStsAuth "Short Range Radar Side Right Rear Object Detection and Processing Burst 5 Protected : Infrastructure Object Track 8 Confidence Status Authenticated";
BA_ "SignalType" SG_ 222 SRRSRRODPB5P_IOTk7TypCnfdAuth "ENM";
BA_ "SignalLongName" SG_ 222 SRRSRRODPB5P_IOTk7TypCnfdAuth "Short Range Radar Side Right Rear Object Detection and Processing Burst 5 Protected : Infrastructure Object Track 7 Type Confidence Authenticated";
BA_ "SignalLongName" SG_ 222 SRRSRRODPB5P_IOTk8PolLgPsAuth "Short Range Radar Side Right Rear Object Detection and Processing Burst 5 Protected : Infrastructure Object Track 8 Point of Interest Longitudinal Position Authenticated";
BA_ "SignalType" SG_ 222 SRRSRRODPB5P_IOTk8MStsAuth "ENM";
BA_ "SignalLongName" SG_ 222 SRRSRRODPB5P_IOTk8MStsAuth "Short Range Radar Side Right Rear Object Detection and Processing Burst 5 Protected : Infrastructure Object Track 8 Measurement Status Authenticated";
BA_ "SignalType" SG_ 222 SRRSRRODPB5P_IOTk9CnfdStsAuth "ENM";
BA_ "SignalLongName" SG_ 222 SRRSRRODPB5P_IOTk9CnfdStsAuth "Short Range Radar Side Right Rear Object Detection and Processing Burst 5 Protected : Infrastructure Object Track 9 Confidence Status Authenticated";
BA_ "SignalType" SG_ 222 SRRSRRODPB5P_IOTk8TypCnfdAuth "ENM";
BA_ "SignalLongName" SG_ 222 SRRSRRODPB5P_IOTk8TypCnfdAuth "Short Range Radar Side Right Rear Object Detection and Processing Burst 5 Protected : Infrastructure Object Track 8 Type Confidence Authenticated";
BA_ "SignalType" SG_ 222 SRRSRRODPB5P_IOTk8TypAuth "ENM";
BA_ "SignalLongName" SG_ 222 SRRSRRODPB5P_IOTk8TypAuth "Short Range Radar Side Right Rear Object Detection and Processing Burst 5 Protected : Infrastructure Object Track 8 Type Authenticated";
BA_ "SignalLongName" SG_ 222 SRRSRRODPB5P_IOTk9IDAuth "Short Range Radar Side Right Rear Object Detection and Processing Burst 5 Protected : Infrastructure Object Track 9 ID Authenticated";
BA_ "SignalType" SG_ 222 SRRSRRODPB5P_IOTk9ElvtnAuth "ENM";
BA_ "SignalLongName" SG_ 222 SRRSRRODPB5P_IOTk9ElvtnAuth "Short Range Radar Side Right Rear Object Detection and Processing Burst 5 Protected : Infrastructure Object Track 9 Elevation Authenticated";
BA_ "SignalLongName" SG_ 222 SRRSRRODPB5P_IOTk9PolLgPsAuth "Short Range Radar Side Right Rear Object Detection and Processing Burst 5 Protected : Infrastructure Object Track 9 Point of Interest Longitudinal Position Authenticated";
BA_ "SignalType" SG_ 222 SRRSRRODPB5P_IOTk9MStsAuth "ENM";
BA_ "SignalLongName" SG_ 222 SRRSRRODPB5P_IOTk9MStsAuth "Short Range Radar Side Right Rear Object Detection and Processing Burst 5 Protected : Infrastructure Object Track 9 Measurement Status Authenticated";
BA_ "SignalType" SG_ 222 SRRSRRODPB5P_IOTk9TypAuth "ENM";
BA_ "SignalLongName" SG_ 222 SRRSRRODPB5P_IOTk9TypAuth "Short Range Radar Side Right Rear Object Detection and Processing Burst 5 Protected : Infrastructure Object Track 9 Type Authenticated";
BA_ "SignalLongName" SG_ 222 SRRSRRODPB5P_VOTk9PoI2LgPsAuth "Short Range Radar Side Right Rear Object Detection and Processing Burst 5 Protected : Vehicle Object Track 9 Point of Interest 2nd Longitudinal Position Authenticated";
BA_ "SignalType" SG_ 222 SRRSRRODPB5P_IOTk9TypCnfdAuth "ENM";
BA_ "SignalLongName" SG_ 222 SRRSRRODPB5P_IOTk9TypCnfdAuth "Short Range Radar Side Right Rear Object Detection and Processing Burst 5 Protected : Infrastructure Object Track 9 Type Confidence Authenticated";
BA_ "SignalLongName" SG_ 222 SRRSRRODPB5P_VOTk9PoI2LPsAuth "Short Range Radar Side Right Rear Object Detection and Processing Burst 5 Protected : Vehicle Object Track 9 Point of Interest 2nd Lateral Position Authenticated";
BA_ "SignalLongName" SG_ 222 SRRSRRODPB5P_VOTk1PoI2LgPsAuth "Short Range Radar Side Right Rear Object Detection and Processing Burst 5 Protected : Vehicle Object Track 1 Point of Interest 2nd Longitudinal Position Authenticated";
BA_ "SignalLongName" SG_ 222 SRRSRRODPB5P_VOTk1PoI2LPsAuth "Short Range Radar Side Right Rear Object Detection and Processing Burst 5 Protected : Vehicle Object Track 1 Point of Interest 2nd Lateral Position Authenticated";
BA_ "SignalLongName" SG_ 222 SRRSRRODPB5P_VOTk2PoI2LgPsAuth "Short Range Radar Side Right Rear Object Detection and Processing Burst 5 Protected : Vehicle Object Track 2 Point of Interest 2nd Longitudinal Position Authenticated";
BA_ "SignalLongName" SG_ 222 SRRSRRODPB5P_VOTk2PoI2LPsAuth "Short Range Radar Side Right Rear Object Detection and Processing Burst 5 Protected : Vehicle Object Track 2 Point of Interest 2nd Lateral Position Authenticated";
BA_ "SignalLongName" SG_ 222 SRRSRRODPB5P_VOTk3PoI2LgPsAuth "Short Range Radar Side Right Rear Object Detection and Processing Burst 5 Protected : Vehicle Object Track 3 Point of Interest 2nd Longitudinal Position Authenticated";
BA_ "SignalLongName" SG_ 222 SRRSRRODPB5P_VOTk3PoI2LPsAuth "Short Range Radar Side Right Rear Object Detection and Processing Burst 5 Protected : Vehicle Object Track 3 Point of Interest 2nd Lateral Position Authenticated";
BA_ "SignalLongName" SG_ 222 SRRSRRODPB5P_VOTk4PoI2LgPsAuth "Short Range Radar Side Right Rear Object Detection and Processing Burst 5 Protected : Vehicle Object Track 4 Point of Interest 2nd Longitudinal Position Authenticated";
BA_ "SignalLongName" SG_ 222 SRRSRRODPB5P_VOTk4PoI2LPsAuth "Short Range Radar Side Right Rear Object Detection and Processing Burst 5 Protected : Vehicle Object Track 4 Point of Interest 2nd Lateral Position Authenticated";
BA_ "SignalLongName" SG_ 222 SRRSRRODPB5P_VOTk5Pol2LgPsAuth "Short Range Radar Side Right Rear Object Detection and Processing Burst 5 Protected : Vehicle Object Track 5 Point of Interest 2nd Longitudinal Position Authenticated";
BA_ "SignalLongName" SG_ 222 SRRSRRODPB5P_VOTk5Pol2LPsAuth "Short Range Radar Side Right Rear Object Detection and Processing Burst 5 Protected : Vehicle Object Track 5 Point of Interest 2nd Lateral Position Authenticated";
BA_ "SignalLongName" SG_ 222 SRRSRRODPB5P_VOTk6PoI2LgPsAuth "Short Range Radar Side Right Rear Object Detection and Processing Burst 5 Protected : Vehicle Object Track 6 Point of Interest 2nd Longitudinal Position Authenticated";
BA_ "SignalLongName" SG_ 222 SRRSRRODPB5P_VOTk6PoI2LPsAuth "Short Range Radar Side Right Rear Object Detection and Processing Burst 5 Protected : Vehicle Object Track 6 Point of Interest 2nd Lateral Position Authenticated";
BA_ "SignalLongName" SG_ 222 SRRSRRODPB5P_VOTk7PoI2LgPsAuth "Short Range Radar Side Right Rear Object Detection and Processing Burst 5 Protected : Vehicle Object Track 7 Point of Interest 2nd Longitudinal Position Authenticated";
BA_ "SignalLongName" SG_ 222 SRRSRRODPB5P_VOTk7PoI2LPsAuth "Short Range Radar Side Right Rear Object Detection and Processing Burst 5 Protected : Vehicle Object Track 7 Point of Interest 2nd Lateral Position Authenticated";
BA_ "SignalLongName" SG_ 222 SRRSRRODPB5P_VOTk8PoI2LgPsAuth "Short Range Radar Side Right Rear Object Detection and Processing Burst 5 Protected : Vehicle Object Track 8 Point of Interest 2nd Longitudinal Position Authenticated";
BA_ "SignalLongName" SG_ 222 SRRSRRODPB5P_VOTk8PoI2LPsAuth "Short Range Radar Side Right Rear Object Detection and Processing Burst 5 Protected : Vehicle Object Track 8 Point of Interest 2nd Lateral Position Authenticated";
BA_ "SignalLongName" SG_ 222 SRRSRRODPB5P_VOTk10PoI2LgPsAuth "Short Range Radar Side Right Rear Object Detection and Processing Burst 5 Protected : Vehicle Object Track 10 Point of Interest 2nd Longitudinal Position Authenticated";
BA_ "SignalLongName" SG_ 222 SRRSRRODPB5P_VOTk10PoI2LPsAuth "Short Range Radar Side Right Rear Object Detection and Processing Burst 5 Protected : Vehicle Object Track 10 Point of Interest 2nd Lateral Position Authenticated";
BA_ "SignalLongName" SG_ 218 SRRSRRODPB1P_MAC "Short Range Radar Side Right Rear Object Detection and Processing Burst 1 Protected : MAC";
BA_ "SignalLongName" SG_ 218 SRRSRRODPB1P_FCnt "Short Range Radar Side Right Rear Object Detection and Processing Burst 1 Protected : Freshness Counter";
BA_ "SignalLongName" SG_ 218 SRRSRRODPB1P_AcqTmStmAuth "Short Range Radar Side Right Rear Object Detection and Processing Burst 1 Protected : Acquisition Time Stamp Authenticated";
BA_ "SignalLongName" SG_ 218 SRRSRRODPB1P_BrstID "Short Range Radar Side Right Rear Object Detection and Processing Burst 1 Protected : Burst ID";
BA_ "SignalType" SG_ 218 SRRSRRODPB1P_CnstrArDtnCnfdAuth "ENM";
BA_ "SignalLongName" SG_ 218 SRRSRRODPB1P_CnstrArDtnCnfdAuth "Short Range Radar Side Right Rear Object Detection and Processing Burst 1 Protected : Construction Area Detection Confidence Authenticated";
BA_ "SignalType" SG_ 218 SRRSRRODPB1P_AcqTmStmAuth_Inv "ENM";
BA_ "SignalLongName" SG_ 218 SRRSRRODPB1P_AcqTmStmAuth_Inv "Short Range Radar Side Right Rear Object Detection and Processing Burst 1 Protected : Acquisition Time Stamp Authenticated Invalid";
BA_ "SignalType" SG_ 218 SRRSRRODPB1P_POTk1DynPrpAuth "ENM";
BA_ "SignalLongName" SG_ 218 SRRSRRODPB1P_POTk1DynPrpAuth "Short Range Radar Side Right Rear Object Detection and Processing Burst 1 Protected : Pedestrian Object Track 1 Dynamic Property Authenticated";
BA_ "SignalType" SG_ 218 SRRSRRODPB1P_POTk1CnfdStsAuth "ENM";
BA_ "SignalLongName" SG_ 218 SRRSRRODPB1P_POTk1CnfdStsAuth "Short Range Radar Side Right Rear Object Detection and Processing Burst 1 Protected : Pedestrian Object Track 1 Confidence Status Authenticated";
BA_ "SignalType" SG_ 218 SRRSRRODPB1P_MdCmdStsAuth "ENM";
BA_ "SignalLongName" SG_ 218 SRRSRRODPB1P_MdCmdStsAuth "Short Range Radar Side Right Rear Object Detection and Processing Burst 1 Protected : Mode Command Status Authenticated";
BA_ "SignalType" SG_ 218 SRRSRRODPB1P_CnstrArDtnStsAuth "ENM";
BA_ "SignalLongName" SG_ 218 SRRSRRODPB1P_CnstrArDtnStsAuth "Short Range Radar Side Right Rear Object Detection and Processing Burst 1 Protected : Construction Area Detection Status Authenticated";
BA_ "SignalLongName" SG_ 218 SRRSRRODPB1P_POTk1IDAuth "Short Range Radar Side Right Rear Object Detection and Processing Burst 1 Protected : Pedestrian Object Track 1 ID Authenticated";
BA_ "SignalType" SG_ 218 SRRSRRODPB1P_POTk1MStsAuth "ENM";
BA_ "SignalLongName" SG_ 218 SRRSRRODPB1P_POTk1MStsAuth "Short Range Radar Side Right Rear Object Detection and Processing Burst 1 Protected : Pedestrian Object Track 1 Measurement Status Authenticated";
BA_ "SignalLongName" SG_ 218 SRRSRRODPB1P_POTk1InPthPotAuth "Short Range Radar Side Right Rear Object Detection and Processing Burst 1 Protected : Pedestrian Object Track 1 In Path Potential Authenticated";
BA_ "SignalLongName" SG_ 218 SRRSRRODPB1P_POTk1PoILAAuth "Short Range Radar Side Right Rear Object Detection and Processing Burst 1 Protected : Pedestrian Object Track 1 Point of Interest Lateral Acceleration Authenticated";
BA_ "SignalLongName" SG_ 218 SRRSRRODPB1P_POTk1PoILgAAuth "Short Range Radar Side Right Rear Object Detection and Processing Burst 1 Protected : Pedestrian Object Track 1 Point of Interest Longitudinal Acceleration Authenticated";
BA_ "SignalLongName" SG_ 218 SRRSRRODPB1P_POTk1PoILgPsAuth "Short Range Radar Side Right Rear Object Detection and Processing Burst 1 Protected : Pedestrian Object Track 1 Point of Interest Longitudinal Position Authenticated";
BA_ "SignalLongName" SG_ 218 SRRSRRODPB1P_POTk1PoILgVAuth "Short Range Radar Side Right Rear Object Detection and Processing Burst 1 Protected : Pedestrian Object Track 1 Point of Interest Longitudinal Velocity Authenticated";
BA_ "SignalLongName" SG_ 218 SRRSRRODPB1P_POTk1PoILPsAuth "Short Range Radar Side Right Rear Object Detection and Processing Burst 1 Protected : Pedestrian Object Track 1 Point of Interest Lateral Position Authenticated";
BA_ "SignalLongName" SG_ 218 SRRSRRODPB1P_POTk1PoILVAuth "Short Range Radar Side Right Rear Object Detection and Processing Burst 1 Protected : Pedestrian Object Track 1 Point of Interest Lateral Velocity Authenticated";
BA_ "SignalType" SG_ 218 SRRSRRODPB1P_POTk2CnfdStsAuth "ENM";
BA_ "SignalLongName" SG_ 218 SRRSRRODPB1P_POTk2CnfdStsAuth "Short Range Radar Side Right Rear Object Detection and Processing Burst 1 Protected : Pedestrian Object Track 2 Confidence Status Authenticated";
BA_ "SignalType" SG_ 218 SRRSRRODPB1P_POTk1TypCnfdAuth "ENM";
BA_ "SignalLongName" SG_ 218 SRRSRRODPB1P_POTk1TypCnfdAuth "Short Range Radar Side Right Rear Object Detection and Processing Burst 1 Protected : Pedestrian Object Track 1 Type Confidence Authenticated";
BA_ "SignalType" SG_ 218 SRRSRRODPB1P_POTk1TypAuth "ENM";
BA_ "SignalLongName" SG_ 218 SRRSRRODPB1P_POTk1TypAuth "Short Range Radar Side Right Rear Object Detection and Processing Burst 1 Protected : Pedestrian Object Track 1 Type Authenticated";
BA_ "SignalLongName" SG_ 218 SRRSRRODPB1P_POTk2IDAuth "Short Range Radar Side Right Rear Object Detection and Processing Burst 1 Protected : Pedestrian Object Track 2 ID Authenticated";
BA_ "SignalType" SG_ 218 SRRSRRODPB1P_POTk2DynPrpAuth "ENM";
BA_ "SignalLongName" SG_ 218 SRRSRRODPB1P_POTk2DynPrpAuth "Short Range Radar Side Right Rear Object Detection and Processing Burst 1 Protected : Pedestrian Object Track 2 Dynamic Property Authenticated";
BA_ "SignalLongName" SG_ 218 SRRSRRODPB1P_POTk2InPthPotAuth "Short Range Radar Side Right Rear Object Detection and Processing Burst 1 Protected : Pedestrian Object Track 2 In Path Potential Authenticated";
BA_ "SignalLongName" SG_ 218 SRRSRRODPB1P_POTk2PoILAAuth "Short Range Radar Side Right Rear Object Detection and Processing Burst 1 Protected : Pedestrian Object Track 2 Point of Interest Lateral Acceleration Authenticated";
BA_ "SignalType" SG_ 218 SRRSRRODPB1P_POTk2MStsAuth "ENM";
BA_ "SignalLongName" SG_ 218 SRRSRRODPB1P_POTk2MStsAuth "Short Range Radar Side Right Rear Object Detection and Processing Burst 1 Protected : Pedestrian Object Track 2 Measurement Status Authenticated";
BA_ "SignalLongName" SG_ 218 SRRSRRODPB1P_POTk2PoILgAAuth "Short Range Radar Side Right Rear Object Detection and Processing Burst 1 Protected : Pedestrian Object Track 2 Point of Interest Longitudinal Acceleration Authenticated";
BA_ "SignalLongName" SG_ 218 SRRSRRODPB1P_POTk2PoILgPsAuth "Short Range Radar Side Right Rear Object Detection and Processing Burst 1 Protected : Pedestrian Object Track 2 Point of Interest Longitudinal Position Authenticated";
BA_ "SignalLongName" SG_ 218 SRRSRRODPB1P_POTk2PoILgVAuth "Short Range Radar Side Right Rear Object Detection and Processing Burst 1 Protected : Pedestrian Object Track 2 Point of Interest Longitudinal Velocity Authenticated";
BA_ "SignalLongName" SG_ 218 SRRSRRODPB1P_POTk2PoILPsAuth "Short Range Radar Side Right Rear Object Detection and Processing Burst 1 Protected : Pedestrian Object Track 2 Point of Interest Lateral Position Authenticated";
BA_ "SignalLongName" SG_ 218 SRRSRRODPB1P_POTk2PoILVAuth "Short Range Radar Side Right Rear Object Detection and Processing Burst 1 Protected : Pedestrian Object Track 2 Point of Interest Lateral Velocity Authenticated";
BA_ "SignalType" SG_ 218 SRRSRRODPB1P_POTk2TypCnfdAuth "ENM";
BA_ "SignalLongName" SG_ 218 SRRSRRODPB1P_POTk2TypCnfdAuth "Short Range Radar Side Right Rear Object Detection and Processing Burst 1 Protected : Pedestrian Object Track 2 Type Confidence Authenticated";
BA_ "SignalType" SG_ 218 SRRSRRODPB1P_POTk2TypAuth "ENM";
BA_ "SignalLongName" SG_ 218 SRRSRRODPB1P_POTk2TypAuth "Short Range Radar Side Right Rear Object Detection and Processing Burst 1 Protected : Pedestrian Object Track 2 Type Authenticated";
BA_ "SignalType" SG_ 218 SRRSRRODPB1P_SnsrUnvAuth "ENM";
BA_ "SignalLongName" SG_ 218 SRRSRRODPB1P_SnsrUnvAuth "Short Range Radar Side Right Rear Object Detection and Processing Burst 1 Protected : Sensor Unavailable Authenticated";
BA_ "SignalType" SG_ 218 SRRSRRODPB1P_SnsrBlckdAuth "ENM";
BA_ "SignalLongName" SG_ 218 SRRSRRODPB1P_SnsrBlckdAuth "Short Range Radar Side Right Rear Object Detection and Processing Burst 1 Protected : Sensor Blocked Authenticated";
BA_ "SignalType" SG_ 218 SRRSRRODPB1P_ServRqrdAuth "ENM";
BA_ "SignalLongName" SG_ 218 SRRSRRODPB1P_ServRqrdAuth "Short Range Radar Side Right Rear Object Detection and Processing Burst 1 Protected : Service Required Authenticated";
BA_ "SignalType" SG_ 218 SRRSRRODPB1P_RdTypCnfdAuth "ENM";
BA_ "SignalLongName" SG_ 218 SRRSRRODPB1P_RdTypCnfdAuth "Short Range Radar Side Right Rear Object Detection and Processing Burst 1 Protected : Road Type Confidence Authenticated";
BA_ "SignalType" SG_ 218 SRRSRRODPB1P_RdTypAuth "ENM";
BA_ "SignalLongName" SG_ 218 SRRSRRODPB1P_RdTypAuth "Short Range Radar Side Right Rear Object Detection and Processing Burst 1 Protected : Road Type Authenticated";
BA_ "SignalLongName" SG_ 218 SRRSRRODPB1P_VOTk1CICOPotAuth "Short Range Radar Side Right Rear Object Detection and Processing Burst 1 Protected : Vehicle Object Track 1 Cut In Cut Out Potential Authenticated";
BA_ "SignalType" SG_ 218 SRRSRRODPB1P_SwpBndwdthStsAuth "ENM";
BA_ "SignalLongName" SG_ 218 SRRSRRODPB1P_SwpBndwdthStsAuth "Short Range Radar Side Right Rear Object Detection and Processing Burst 1 Protected : Sweep Bandwidth Status Authenticated";
BA_ "SignalLongName" SG_ 218 SRRSRRODPB1P_VOTk1IDAuth "Short Range Radar Side Right Rear Object Detection and Processing Burst 1 Protected : Vehicle Object Track 1 ID Authenticated";
BA_ "SignalType" SG_ 218 SRRSRRODPB1P_VOTk1DynPrpStsAuth "ENM";
BA_ "SignalLongName" SG_ 218 SRRSRRODPB1P_VOTk1DynPrpStsAuth "Short Range Radar Side Right Rear Object Detection and Processing Burst 1 Protected : Vehicle Object Track 1 Dynamic Property Status Authenticated";
BA_ "SignalType" SG_ 218 SRRSRRODPB1P_VOTk1DynPrpAuth "ENM";
BA_ "SignalLongName" SG_ 218 SRRSRRODPB1P_VOTk1DynPrpAuth "Short Range Radar Side Right Rear Object Detection and Processing Burst 1 Protected : Vehicle Object Track 1 Dynamic Property Authenticated";
BA_ "SignalType" SG_ 218 SRRSRRODPB1P_VOTk1CnfdStsAuth "ENM";
BA_ "SignalLongName" SG_ 218 SRRSRRODPB1P_VOTk1CnfdStsAuth "Short Range Radar Side Right Rear Object Detection and Processing Burst 1 Protected : Vehicle Object Track 1 Confidence Status Authenticated";
BA_ "SignalLongName" SG_ 218 SRRSRRODPB1P_VOTk1PoILAAuth "Short Range Radar Side Right Rear Object Detection and Processing Burst 1 Protected : Vehicle Object Track 1 Point of Interest Lateral Acceleration Authenticated";
BA_ "SignalType" SG_ 218 SRRSRRODPB1P_VOTk1MStsAuth "ENM";
BA_ "SignalLongName" SG_ 218 SRRSRRODPB1P_VOTk1MStsAuth "Short Range Radar Side Right Rear Object Detection and Processing Burst 1 Protected : Vehicle Object Track 1 Measurement Status Authenticated";
BA_ "SignalLongName" SG_ 218 SRRSRRODPB1P_VOTk1PoILgAAuth "Short Range Radar Side Right Rear Object Detection and Processing Burst 1 Protected : Vehicle Object Track 1 Point of Interest Longitudinal Acceleration Authenticated";
BA_ "SignalLongName" SG_ 218 SRRSRRODPB1P_VOTk1PoILgPsAuth "Short Range Radar Side Right Rear Object Detection and Processing Burst 1 Protected : Vehicle Object Track 1 Point of Interest Longitudinal Position Authenticated";
BA_ "SignalLongName" SG_ 218 SRRSRRODPB1P_VOTk1PoILgPsCAuth "Short Range Radar Side Right Rear Object Detection and Processing Burst 1 Protected : Vehicle Object Track 1 Point of Interest Longitudinal Position Covariance Authenticated";
BA_ "SignalLongName" SG_ 218 SRRSRRODPB1P_VOTk1PoILgthAuth "Short Range Radar Side Right Rear Object Detection and Processing Burst 1 Protected : Vehicle Object Track 1 Point of Interest Length Authenticated";
BA_ "SignalLongName" SG_ 218 SRRSRRODPB1P_VOTk1PoILgVAuth "Short Range Radar Side Right Rear Object Detection and Processing Burst 1 Protected : Vehicle Object Track 1 Point of Interest Longitudinal Velocity Authenticated";
BA_ "SignalLongName" SG_ 218 SRRSRRODPB1P_VOTk1PoILgVCAuth "Short Range Radar Side Right Rear Object Detection and Processing Burst 1 Protected : Vehicle Object Track 1 Point of Interest Longitudinal Velocity Covariance Authenticated";
BA_ "SignalLongName" SG_ 218 SRRSRRODPB1P_VOTk1PoILPsAuth "Short Range Radar Side Right Rear Object Detection and Processing Burst 1 Protected : Vehicle Object Track 1 Point of Interest Lateral Position Authenticated";
BA_ "SignalLongName" SG_ 218 SRRSRRODPB1P_VOTk1PoILPsCAuth "Short Range Radar Side Right Rear Object Detection and Processing Burst 1 Protected : Vehicle Object Track 1 Point of Interest Lateral Position Covariance Authenticated";
BA_ "SignalLongName" SG_ 218 SRRSRRODPB1P_VOTk1PoILVAuth "Short Range Radar Side Right Rear Object Detection and Processing Burst 1 Protected : Vehicle Object Track 1 Point of Interest Lateral Velocity Authenticated";
BA_ "SignalLongName" SG_ 218 SRRSRRODPB1P_VOTk1PoILVCAuth "Short Range Radar Side Right Rear Object Detection and Processing Burst 1 Protected : Vehicle Object Track 1 Point of Interest Lateral Velocity Covariance Authenticated";
BA_ "SignalLongName" SG_ 218 SRRSRRODPB1P_VOTk2PoILgthAuth "Short Range Radar Side Right Rear Object Detection and Processing Burst 1 Protected : Vehicle Object Track 2 Point of Interest Length Authenticated";
BA_ "SignalType" SG_ 218 SRRSRRODPB1P_VOTk1TypCnfdAuth "ENM";
BA_ "SignalLongName" SG_ 218 SRRSRRODPB1P_VOTk1TypCnfdAuth "Short Range Radar Side Right Rear Object Detection and Processing Burst 1 Protected : Vehicle Object Track 1 Type Confidence Authenticated";
BA_ "SignalLongName" SG_ 218 SRRSRRODPB1P_ARC "Short Range Radar Side Right Rear Object Detection and Processing Burst 1 Protected : Alive Rolling Count";
BA_ "SignalLongName" SG_ 223 SRRSRRODPB6P_IOTk10PolLPsAuth "Short Range Radar Side Right Rear Object Detection and Processing Burst 6 Protected : Infrastructure Object Track 10 Point of Interest Lateral Position Authenticated";
BA_ "SignalLongName" SG_ 223 SRRSRRODPB6P_BrstID "Short Range Radar Side Right Rear Object Detection and Processing Burst 6 Protected : Burst ID";
BA_ "SignalLongName" SG_ 223 SRRSRRODPB6P_IOTk1PoILPsAuth "Short Range Radar Side Right Rear Object Detection and Processing Burst 6 Protected : Infrastructure Object Track 1 Point of Interest Lateral Position Authenticated";
BA_ "SignalLongName" SG_ 223 SRRSRRODPB6P_IOTk2PolLPsAuth "Short Range Radar Side Right Rear Object Detection and Processing Burst 6 Protected : Infrastructure Object Track 2 Point of Interest Lateral Position Authenticated";
BA_ "SignalLongName" SG_ 223 SRRSRRODPB6P_IOTk3PolLPsAuth "Short Range Radar Side Right Rear Object Detection and Processing Burst 6 Protected : Infrastructure Object Track 3 Point of Interest Lateral Position Authenticated";
BA_ "SignalLongName" SG_ 223 SRRSRRODPB6P_IOTk4PolLPsAuth "Short Range Radar Side Right Rear Object Detection and Processing Burst 6 Protected : Infrastructure Object Track 4 Point of Interest Lateral Position Authenticated";
BA_ "SignalLongName" SG_ 223 SRRSRRODPB6P_IOTk5PolLPsAuth "Short Range Radar Side Right Rear Object Detection and Processing Burst 6 Protected : Infrastructure Object Track 5 Point of Interest Lateral Position Authenticated";
BA_ "SignalLongName" SG_ 223 SRRSRRODPB6P_IOTk6PolLPsAuth "Short Range Radar Side Right Rear Object Detection and Processing Burst 6 Protected : Infrastructure Object Track 6 Point of Interest Lateral Position Authenticated";
BA_ "SignalLongName" SG_ 223 SRRSRRODPB6P_IOTk7PolLPsAuth "Short Range Radar Side Right Rear Object Detection and Processing Burst 6 Protected : Infrastructure Object Track 7 Point of Interest Lateral Position Authenticated";
BA_ "SignalLongName" SG_ 223 SRRSRRODPB6P_IOTk8PolLPsAuth "Short Range Radar Side Right Rear Object Detection and Processing Burst 6 Protected : Infrastructure Object Track 8 Point of Interest Lateral Position Authenticated";
BA_ "SignalLongName" SG_ 223 SRRSRRODPB6P_IOTk9PolLPsAuth "Short Range Radar Side Right Rear Object Detection and Processing Burst 6 Protected : Infrastructure Object Track 9 Point of Interest Lateral Position Authenticated";
BA_ "SignalType" SG_ 223 SRRSRRODPB6P_REOTk1CnfdStsAuth "ENM";
BA_ "SignalLongName" SG_ 223 SRRSRRODPB6P_REOTk1CnfdStsAuth "Short Range Radar Side Right Rear Object Detection and Processing Burst 6 Protected : Road Edge Object Track 1 Confidence Status Authenticated";
BA_ "SignalLongName" SG_ 223 SRRSRRODPB6P_REOTk1CrvAuth "Short Range Radar Side Right Rear Object Detection and Processing Burst 6 Protected : Road Edge Object Track 1 Curvature Authenticated";
BA_ "SignalLongName" SG_ 223 SRRSRRODPB6P_REOTk1CrvDrvtAuth "Short Range Radar Side Right Rear Object Detection and Processing Burst 6 Protected : Road Edge Object Track 1 Curvature Derivative Authenticated";
BA_ "SignalLongName" SG_ 223 SRRSRRODPB6P_REOTk1HdgAuth "Short Range Radar Side Right Rear Object Detection and Processing Burst 6 Protected : Road Edge Object Track 1 Heading Authenticated";
BA_ "SignalLongName" SG_ 223 SRRSRRODPB6P_REOTk1OfstAuth "Short Range Radar Side Right Rear Object Detection and Processing Burst 6 Protected : Road Edge Object Track 1 Offset Authenticated";
BA_ "SignalLongName" SG_ 223 SRRSRRODPB6P_REOTk1PsEndAuth "Short Range Radar Side Right Rear Object Detection and Processing Burst 6 Protected : Road Edge Object Track 1 Position End Authenticated";
BA_ "SignalLongName" SG_ 223 SRRSRRODPB6P_REOTk1PsStrtAuth "Short Range Radar Side Right Rear Object Detection and Processing Burst 6 Protected : Road Edge Object Track 1 Position Start Authenticated";
BA_ "SignalType" SG_ 223 SRRSRRODPB6P_REOTk2CnfdStsAuth "ENM";
BA_ "SignalLongName" SG_ 223 SRRSRRODPB6P_REOTk2CnfdStsAuth "Short Range Radar Side Right Rear Object Detection and Processing Burst 6 Protected : Road Edge Object Track 2 Confidence Status Authenticated";
BA_ "SignalType" SG_ 223 SRRSRRODPB6P_REOTk1TypCnfdAuth "ENM";
BA_ "SignalLongName" SG_ 223 SRRSRRODPB6P_REOTk1TypCnfdAuth "Short Range Radar Side Right Rear Object Detection and Processing Burst 6 Protected : Road Edge Object Track 1 Type Confidence Authenticated";
BA_ "SignalType" SG_ 223 SRRSRRODPB6P_REOTk1TypAuth "ENM";
BA_ "SignalLongName" SG_ 223 SRRSRRODPB6P_REOTk1TypAuth "Short Range Radar Side Right Rear Object Detection and Processing Burst 6 Protected : Road Edge Object Track 1 Type Authenticated";
BA_ "SignalLongName" SG_ 223 SRRSRRODPB6P_REOTk2CrvAuth "Short Range Radar Side Right Rear Object Detection and Processing Burst 6 Protected : Road Edge Object Track 2 Curvature Authenticated";
BA_ "SignalLongName" SG_ 223 SRRSRRODPB6P_REOTk2CrvDrvtAuth "Short Range Radar Side Right Rear Object Detection and Processing Burst 6 Protected : Road Edge Object Track 2 Curvature Derivative Authenticated";
BA_ "SignalLongName" SG_ 223 SRRSRRODPB6P_REOTk2HdgAuth "Short Range Radar Side Right Rear Object Detection and Processing Burst 6 Protected : Road Edge Object Track 2 Heading Authenticated";
BA_ "SignalLongName" SG_ 223 SRRSRRODPB6P_REOTk2OfstAuth "Short Range Radar Side Right Rear Object Detection and Processing Burst 6 Protected : Road Edge Object Track 2 Offset Authenticated";
BA_ "SignalLongName" SG_ 223 SRRSRRODPB6P_REOTk2PsEndAuth "Short Range Radar Side Right Rear Object Detection and Processing Burst 6 Protected : Road Edge Object Track 2 Position End Authenticated";
BA_ "SignalLongName" SG_ 223 SRRSRRODPB6P_REOTk2PsStrtAuth "Short Range Radar Side Right Rear Object Detection and Processing Burst 6 Protected : Road Edge Object Track 2 Position Start Authenticated";
BA_ "SignalType" SG_ 223 SRRSRRODPB6P_REOTk3CnfdStsAuth "ENM";
BA_ "SignalLongName" SG_ 223 SRRSRRODPB6P_REOTk3CnfdStsAuth "Short Range Radar Side Right Rear Object Detection and Processing Burst 6 Protected : Road Edge Object Track 3 Confidence Status Authenticated";
BA_ "SignalType" SG_ 223 SRRSRRODPB6P_REOTk2TypCnfdAuth "ENM";
BA_ "SignalLongName" SG_ 223 SRRSRRODPB6P_REOTk2TypCnfdAuth "Short Range Radar Side Right Rear Object Detection and Processing Burst 6 Protected : Road Edge Object Track 2 Type Confidence Authenticated";
BA_ "SignalType" SG_ 223 SRRSRRODPB6P_REOTk2TypAuth "ENM";
BA_ "SignalLongName" SG_ 223 SRRSRRODPB6P_REOTk2TypAuth "Short Range Radar Side Right Rear Object Detection and Processing Burst 6 Protected : Road Edge Object Track 2 Type Authenticated";
BA_ "SignalLongName" SG_ 223 SRRSRRODPB6P_REOTk3CrvAuth "Short Range Radar Side Right Rear Object Detection and Processing Burst 6 Protected : Road Edge Object Track 3 Curvature Authenticated";
BA_ "SignalLongName" SG_ 223 SRRSRRODPB6P_REOTk3CrvDrvtAuth "Short Range Radar Side Right Rear Object Detection and Processing Burst 6 Protected : Road Edge Object Track 3 Curvature Derivative Authenticated";
BA_ "SignalLongName" SG_ 223 SRRSRRODPB6P_REOTk3HdgAuth "Short Range Radar Side Right Rear Object Detection and Processing Burst 6 Protected : Road Edge Object Track 3 Heading Authenticated";
BA_ "SignalLongName" SG_ 223 SRRSRRODPB6P_REOTk3OfstAuth "Short Range Radar Side Right Rear Object Detection and Processing Burst 6 Protected : Road Edge Object Track 3 Offset Authenticated";
BA_ "SignalLongName" SG_ 223 SRRSRRODPB6P_REOTk3PsEndAuth "Short Range Radar Side Right Rear Object Detection and Processing Burst 6 Protected : Road Edge Object Track 3 Position End Authenticated";
BA_ "SignalLongName" SG_ 223 SRRSRRODPB6P_REOTk3PsStrtAuth "Short Range Radar Side Right Rear Object Detection and Processing Burst 6 Protected : Road Edge Object Track 3 Position Start Authenticated";
BA_ "SignalType" SG_ 223 SRRSRRODPB6P_REOTk3TypCnfdAuth "ENM";
BA_ "SignalLongName" SG_ 223 SRRSRRODPB6P_REOTk3TypCnfdAuth "Short Range Radar Side Right Rear Object Detection and Processing Burst 6 Protected : Road Edge Object Track 3 Type Confidence Authenticated";
BA_ "SignalType" SG_ 223 SRRSRRODPB6P_REOTk3TypAuth "ENM";
BA_ "SignalLongName" SG_ 223 SRRSRRODPB6P_REOTk3TypAuth "Short Range Radar Side Right Rear Object Detection and Processing Burst 6 Protected : Road Edge Object Track 3 Type Authenticated";
BA_ "SignalLongName" SG_ 40 SWIP_StrgWhlAngAuth "Steering Wheel Information Protected : Steering Wheel Angle Authenticated";
BA_ "SignalLongName" SG_ 40 YRP_YawRateAuth "Yaw Rate Protected : Yaw Rate Authenticated";
BA_ "SignalType" SG_ 40 YRP_YawRateAuth_Inv "ENM";
BA_ "SignalLongName" SG_ 40 YRP_YawRateAuth_Inv "Yaw Rate Protected : Yaw Rate Authenticated Invalid";
BA_ "SignalLongName" SG_ 40 BGI3P_BrkPedPstnAuth "Body General Information 3 Protected : Brake Pedal Position Authenticated";
BA_ "SignalType" SG_ 40 SWIP_StrgWhlAngAuth_Inv "ENM";
BA_ "SignalLongName" SG_ 40 SWIP_StrgWhlAngAuth_Inv "Steering Wheel Information Protected : Steering Wheel Angle Authenticated Invalid";
BA_ "SignalType" SG_ 40 SWIP_StrgWhlAngAuth_DuD "ENM";
BA_ "SignalLongName" SG_ 40 SWIP_StrgWhlAngAuth_DuD "Steering Wheel Information Protected : Steering Wheel Angle Authenticated Don't Use Data";
BA_ "SignalLongName" SG_ 607 DRCDNDP_DRCAvgDrvnAuth "ECM General Information 1 Protected : Distance Rolling Count Average Driven Authenticated";
BA_ "SignalType" SG_ 607 DRCDNDP_DRCAvgDrvnAuth_Inv "ENM";
BA_ "SignalLongName" SG_ 607 DRCDNDP_DRCAvgDrvnAuth_Inv "ECM General Information 1 Protected : Distance Rolling Count Average Driven Authenticated Invalid";
BA_ "SignalLongName" SG_ 1116 TmSyncMsg "Time Sync Message";
BA_ "SignalLongName" SG_ 1116 VODVP_VehOdoDispValAuth "Vehicle Odometer Display Value Protected : Vehicle Odometer Display Value Authenticated";
BA_ "SignalLongName" SG_ 1116 CldrYr "Calendar Year";
BA_ "SignalLongName" SG_ 1116 OATP_OtsAirTmpCrValAuth "Outside Air Temperature Protected : Outside Air Temperature Corrected Value Authenticated";
BA_ "SignalLongName" SG_ 1116 MinOfHr "Minute of Hour";
BA_ "SignalLongName" SG_ 1116 SecOfMin "Seconds of Minute";
BA_ "SignalLongName" SG_ 1116 HrOfDay "Hour of Day";
BA_ "SignalLongName" SG_ 1116 CldrDay "Calendar Day";
BA_ "SignalType" SG_ 1116 VODVP_VehOdoDispValAuth_Inv "ENM";
BA_ "SignalLongName" SG_ 1116 VODVP_VehOdoDispValAuth_Inv "Vehicle Odometer Display Value Protected : Vehicle Odometer Display Value Authenticated Invalid";
BA_ "SignalType" SG_ 1116 OATP_OtsAirTmpCrValAuth_Inv "ENM";
BA_ "SignalLongName" SG_ 1116 OATP_OtsAirTmpCrValAuth_Inv "Outside Air Temperature Protected : Outside Air Temperature Corrected Value Authenticated Invalid";
BA_ "SignalType" SG_ 1116 CldrMth "ENM";
BA_ "SignalLongName" SG_ 1116 CldrMth "Calendar Month";
BA_ "SignalType" SG_ 1117 ELWWIP_WprFrtFtrReqAuth "ENM";
BA_ "SignalLongName" SG_ 1117 ELWWIP_WprFrtFtrReqAuth "Exterior Lighting and Wash Wiper Information Protected : Wiper Front Feature Request Authenticated";
BA_ "SignalLongName" SG_ 1118 TrlrLgth "Trailer Length";
BA_ "SignalType" SG_ 1118 VMMP_VehMtnMvmtStatAuth "ENM";
BA_ "SignalLongName" SG_ 1118 VMMP_VehMtnMvmtStatAuth "Vehicle Motion Movement Protected : Vehicle Motion Movement State Authenticated";
BA_ "SignalType" SG_ 1118 SBZVisIndExtrnCktFltPrLtGtd "ENM";
BA_ "SignalLongName" SG_ 1118 SBZVisIndExtrnCktFltPrLtGtd "Side Blind Zone Visual Indication External Circuit Fault Present Left Gated";
BA_ "SignalType" SG_ 1118 SBZVisIndExtrnCktFltPrLtGtd_Inv "ENM";
BA_ "SignalLongName" SG_ 1118 SBZVisIndExtrnCktFltPrLtGtd_Inv "Side Blind Zone Visual Indication External Circuit Fault Present Left Gated Invalid";
BA_ "SignalType" SG_ 1118 DrSlctdSpdLmtAutMdSpdLmtStat "ENM";
BA_ "SignalLongName" SG_ 1118 DrSlctdSpdLmtAutMdSpdLmtStat "Driver Selected Speed Limiter Auto Mode Speed Limit Status";
BA_ "SignalType" SG_ 1118 AutoBmSlctAllwd "ENM";
BA_ "SignalLongName" SG_ 1118 AutoBmSlctAllwd "Automatic Beam Select Allowed";
BA_ "SignalType" SG_ 1118 AutoBmSlctAllwd_Inv "ENM";
BA_ "SignalLongName" SG_ 1118 AutoBmSlctAllwd_Inv "Automatic Beam Select Allowed Invalid";
BA_ "SignalType" SG_ 1118 TrlrHtchTyp "ENM";
BA_ "SignalLongName" SG_ 1118 TrlrHtchTyp "Trailer Hitch Type";
BA_ "SignalType" SG_ 1118 DrvrSeltdTrlrPrsnt "ENM";
BA_ "SignalLongName" SG_ 1118 DrvrSeltdTrlrPrsnt "Driver Selected Trailer Present";
BA_ "SignalType" SG_ 1118 FgLmpFrtRtCmd "ENM";
BA_ "SignalLongName" SG_ 1118 FgLmpFrtRtCmd "Fog Lamp Front Right Command";
BA_ "SignalType" SG_ 1118 FgLmpFrtLftCmd "ENM";
BA_ "SignalLongName" SG_ 1118 FgLmpFrtLftCmd "Fog Lamp Front Left Command";
BA_ "SignalType" SG_ 1118 LogisticModeStatus "ENM";
BA_ "SignalLongName" SG_ 1118 LogisticModeStatus "Logistic Mode Status";
BA_ "SignalType" SG_ 1118 SBZVisIndExtrnCktFltPrRtGtd "ENM";
BA_ "SignalLongName" SG_ 1118 SBZVisIndExtrnCktFltPrRtGtd "Side Blind Zone Visual Indication External Circuit Fault Present Right Gated";
BA_ "SignalType" SG_ 1118 SBZVisIndExtrnCktFltPrRtGtd_Inv "ENM";
BA_ "SignalLongName" SG_ 1118 SBZVisIndExtrnCktFltPrRtGtd_Inv "Side Blind Zone Visual Indication External Circuit Fault Present Right Gated Invalid";
BA_ "SignalType" SG_ 1118 SBZAlrtCstChngSetReq "ENM";
BA_ "SignalLongName" SG_ 1118 SBZAlrtCstChngSetReq "Side Blind Zone Alert Customization Change Setting Request";
BA_ "SignalType" SG_ 1118 LnChgAlrtCstChngSetReq "ENM";
BA_ "SignalLongName" SG_ 1118 LnChgAlrtCstChngSetReq "Lane Change Alert Customization Change Setting Request";
BA_ "SignalType" SG_ 1121 APASP_APAStsAuth "ENM";
BA_ "SignalLongName" SG_ 1121 APASP_APAStsAuth "APA Status Protected : Advanced Park Assist Status Authenticated";
BA_ "SignalType" SG_ 1121 HSP_DrvAlrtTypCstCurrSetValAuth "ENM";
BA_ "SignalLongName" SG_ 1121 HSP_DrvAlrtTypCstCurrSetValAuth "Haptic Seat Protected : Driver Alert Type Customization Current Setting Value Authenticated";
BA_ "SignalType" SG_ 1121 HSP_HptcStOprtlStsAuth "ENM";
BA_ "SignalLongName" SG_ 1121 HSP_HptcStOprtlStsAuth "Haptic Seat Protected : Haptic Seat Operational Status Authenticated";
BA_ "SignalType" SG_ 1121 TrffcLgtAsstCstChgSetReq "ENM";
BA_ "SignalLongName" SG_ 1121 TrffcLgtAsstCstChgSetReq "Traffic Light Assist Customization Change Setting Request";
BA_ "SignalType" SG_ 1121 RrCrsTrfcAlrtCstChngSetReq "ENM";
BA_ "SignalLongName" SG_ 1121 RrCrsTrfcAlrtCstChngSetReq "Rear Cross Traffic Alert Customization Change Setting Request";
BA_ "SignalType" SG_ 1121 GlrFrHgBmRspTypCstChgSetReq "ENM";
BA_ "SignalLongName" SG_ 1121 GlrFrHgBmRspTypCstChgSetReq "Glare Free High Beam Response Type Customization Change Setting Request";
BA_ "SignalType" SG_ 1121 TSMWrngPopUpSts "ENM";
BA_ "SignalLongName" SG_ 1121 TSMWrngPopUpSts "Traffic Sign Memory Warning Pop Up Status";
BA_ "SignalType" SG_ 1121 TSMSgnNtfnWrnDispd "ENM";
BA_ "SignalLongName" SG_ 1121 TSMSgnNtfnWrnDispd "Traffic Sign Memory Sign Notification Warning Displayed";
BA_ "SignalType" SG_ 1121 TSMPageDispActv "ENM";
BA_ "SignalLongName" SG_ 1121 TSMPageDispActv "Traffic Sign Memory Page Display Active";
BA_ "SignalType" SG_ 1121 TSMCustRstReq "ENM";
BA_ "SignalLongName" SG_ 1121 TSMCustRstReq "Traffic Sign Memory Customer Reset Request";
BA_ "SignalType" SG_ 1121 RstrCstDfltReq "ENM";
BA_ "SignalLongName" SG_ 1121 RstrCstDfltReq "Restore Customization Defaults Request";
BA_ "SignalType" SG_ 1121 DispMeasSysExtnd "ENM";
BA_ "SignalLongName" SG_ 1121 DispMeasSysExtnd "Display Measurement System Extended";
BA_ "SignalType" SG_ 1121 BGI1P_OutsdAmbtLgtLvlStsAuth "ENM";
BA_ "SignalLongName" SG_ 1121 BGI1P_OutsdAmbtLgtLvlStsAuth "Body General Information 1 Protected : Outside Ambient Light Level Status Authenticated";
BA_ "SignalType" SG_ 1121 LowBmAct "ENM";
BA_ "SignalLongName" SG_ 1121 LowBmAct "Low Beams Active";
BA_ "SignalType" SG_ 1121 HighBmAct "ENM";
BA_ "SignalLongName" SG_ 1121 HighBmAct "High Beams Active";
BA_ "SignalType" SG_ 1121 TrnSigSwRtActv "ENM";
BA_ "SignalLongName" SG_ 1121 TrnSigSwRtActv "Turn Signal Switch Right Active";
BA_ "SignalType" SG_ 1121 TrnSigSwLtActv "ENM";
BA_ "SignalLongName" SG_ 1121 TrnSigSwLtActv "Turn Signal Switch Left Active";
BA_ "SignalType" SG_ 1121 TrlrConnStat "ENM";
BA_ "SignalLongName" SG_ 1121 TrlrConnStat "Trailer Connection Status";
BA_ "SignalType" SG_ 1121 TimeDispFormat "ENM";
BA_ "SignalLongName" SG_ 1121 TimeDispFormat "Time Display Format";
BA_ "SignalType" SG_ 1121 TDAP_TeenDrvrActvAuth "ENM";
BA_ "SignalLongName" SG_ 1121 TDAP_TeenDrvrActvAuth "Teen Driver Active Protected : Teen Driver Active Authenticated";
BA_ "SignalType" SG_ 1121 RrCrsTrfcBrkgSysSts "ENM";
BA_ "SignalLongName" SG_ 1121 RrCrsTrfcBrkgSysSts "Rear Cross Traffic Braking System Status";
BA_ "SignalType" SG_ 1121 TDAP_DrvrIdfrAuth "ENM";
BA_ "SignalLongName" SG_ 1121 TDAP_DrvrIdfrAuth "Teen Driver Active Protected : Driver Identifier Authenticated";
BA_ "SignalLongName" SG_ 608 VSANDP_VehSpdAvgNDrvnAuth "Vehicle Speed Average Non Driven Protected : Vehicle Speed Average NonDriven Authenticated";
BA_ "SignalType" SG_ 609 BkUpPwrMdRnCrnkOutSt "ENM";
BA_ "SignalLongName" SG_ 609 BkUpPwrMdRnCrnkOutSt "Backup Power Mode RUN ACCESSORY Output State";
VAL_ 212 SRRSLRODPB1P_CnstrArDtnCnfdAuth 0 "Highly Speculative" 1 "Speculative" 2 "Confident" 3 "Highly Confident" ;
VAL_ 212 SRRSLRODPB1P_AcqTmStmAuth_Inv 0 "FALSE" 1 "TRUE" ;
VAL_ 212 SRRSLRODPB1P_POTk1DynPrpAuth 0 "Has Never Moved" 1 "Has Moved But Currently Stopped" 2 "Moving In Same Direction As Host" 3 "Moving In Opposite Direction As Host" 4 "Crossing Path" ;
VAL_ 212 SRRSLRODPB1P_POTk1CnfdStsAuth 0 "Highly Speculative" 1 "Speculative" 2 "Confident" 3 "Highly Confident" ;
VAL_ 212 SRRSLRODPB1P_MdCmdStsAuth 0 "Not Radiating" 1 "Reporting Object Data" 2 "Not Reporting Object Data" ;
VAL_ 212 SRRSLRODPB1P_CnstrArDtnStsAuth 0 "Not Detected" 1 "Detected" 2 "Unknown" ;
VAL_ 212 SRRSLRODPB1P_POTk1MStsAuth 0 "No Object" 1 "New Object" 2 "Latent Track Not Detected this Cycle" 3 "Measured this Cycle" ;
VAL_ 212 SRRSLRODPB1P_POTk2CnfdStsAuth 0 "Highly Speculative" 1 "Speculative" 2 "Confident" 3 "Highly Confident" ;
VAL_ 212 SRRSLRODPB1P_POTk1TypCnfdAuth 0 "Highly Speculative" 1 "Speculative" 2 "Confident" 3 "Highly Confident" ;
VAL_ 212 SRRSLRODPB1P_POTk1TypAuth 0 "Unknown" 1 "Pedestrian" 2 "Bicycle" ;
VAL_ 212 SRRSLRODPB1P_POTk2DynPrpAuth 0 "Has Never Moved" 1 "Has Moved But Currently Stopped" 2 "Moving In Same Direction As Host" 3 "Moving In Opposite Direction As Host" 4 "Crossing Path" ;
VAL_ 212 SRRSLRODPB1P_POTk2MStsAuth 0 "No Object" 1 "New Object" 2 "Latent Track Not Detected this Cycle" 3 "Measured this Cycle" ;
VAL_ 212 SRRSLRODPB1P_POTk2TypCnfdAuth 0 "Highly Speculative" 1 "Speculative" 2 "Confident" 3 "Highly Confident" ;
VAL_ 212 SRRSLRODPB1P_POTk2TypAuth 0 "Unknown" 1 "Pedestrian" 2 "Bicycle" ;
VAL_ 212 SRRSLRODPB1P_SnsrUnvAuth 0 "FALSE" 1 "TRUE" ;
VAL_ 212 SRRSLRODPB1P_SnsrBlckdAuth 0 "FALSE" 1 "TRUE" ;
VAL_ 212 SRRSLRODPB1P_ServRqrdAuth 0 "FALSE" 1 "TRUE" ;
VAL_ 212 SRRSLRODPB1P_RdTypCnfdAuth 0 "Highly Speculative" 1 "Speculative" 2 "Confident" 3 "Highly Confident" ;
VAL_ 212 SRRSLRODPB1P_RdTypAuth 0 "Unknown" 1 "City" 2 "Secondary Road" 3 "Highway" 4 "Construction" 5 "Zone Entry" 6 "Construction" 7 "Zone Exit" ;
VAL_ 212 SRRSLRODPB1P_SwpBndwdthStsAuth 0 "Mode A" 1 "Mode B" 2 "Mode C" 3 "Mode D" ;
VAL_ 212 SRRSLRODPB1P_VOTk1DynPrpStsAuth 0 "Stopped" 1 "Not Stopped" ;
VAL_ 212 SRRSLRODPB1P_VOTk1DynPrpAuth 0 "Has Never Moved" 1 "Moving In Same Direction As Host" 2 "Moving In Opposite Direction As Host" 3 "Crossing From Left To Right" 4 "Crossing From Right To Left" ;
VAL_ 212 SRRSLRODPB1P_VOTk1CnfdStsAuth 0 "Highly Speculative" 1 "Speculative" 2 "Confident" 3 "Highly Confident" ;
VAL_ 212 SRRSLRODPB1P_VOTk1MStsAuth 0 "No Object" 1 "New Object" 2 "Latent Track Not Detected this Cycle" 3 "Measured this Cycle" ;
VAL_ 212 SRRSLRODPB1P_VOTk1TypCnfdAuth 0 "Highly Speculative" 1 "Speculative" 2 "Confident" 3 "Highly Confident" ;
VAL_ 217 SRRSLRODPB6P_REOTk1CnfdStsAuth 0 "Highly Speculative" 1 "Speculative" 2 "Confident" 3 "Highly Confident" ;
VAL_ 217 SRRSLRODPB6P_REOTk2CnfdStsAuth 0 "Highly Speculative" 1 "Speculative" 2 "Confident" 3 "Highly Confident" ;
VAL_ 217 SRRSLRODPB6P_REOTk1TypCnfdAuth 0 "Highly Speculative" 1 "Speculative" 2 "Confident" 3 "Highly Confident" ;
VAL_ 217 SRRSLRODPB6P_REOTk1TypAuth 0 "Unknown" 1 "Barriers" 2 "Guard Rails" 3 "Bridge Abutments" 4 "Edge of Road" 5 "Open Area" ;
VAL_ 217 SRRSLRODPB6P_REOTk3CnfdStsAuth 0 "Highly Speculative" 1 "Speculative" 2 "Confident" 3 "Highly Confident" ;
VAL_ 217 SRRSLRODPB6P_REOTk2TypCnfdAuth 0 "Highly Speculative" 1 "Speculative" 2 "Confident" 3 "Highly Confident" ;
VAL_ 217 SRRSLRODPB6P_REOTk2TypAuth 0 "Unknown" 1 "Barriers" 2 "Guard Rails" 3 "Bridge Abutments" 4 "Edge of Road" 5 "Open Area" ;
VAL_ 217 SRRSLRODPB6P_REOTk3TypCnfdAuth 0 "Highly Speculative" 1 "Speculative" 2 "Confident" 3 "Highly Confident" ;
VAL_ 217 SRRSLRODPB6P_REOTk3TypAuth 0 "Unknown" 1 "Barriers" 2 "Guard Rails" 3 "Bridge Abutments" 4 "Edge of Road" 5 "Open Area" ;
VAL_ 219 SRRSRRODPB2P_POTk3DynPrpAuth 0 "Has Never Moved" 1 "Has Moved But Currently Stopped" 2 "Moving In Same Direction As Host" 3 "Moving In Opposite Direction As Host" 4 "Crossing Path" ;
VAL_ 219 SRRSRRODPB2P_POTk3CnfdStsAuth 0 "Highly Speculative" 1 "Speculative" 2 "Confident" 3 "Highly Confident" ;
VAL_ 219 SRRSRRODPB2P_POTk3MStsAuth 0 "No Object" 1 "New Object" 2 "Latent Track Not Detected this Cycle" 3 "Measured this Cycle" ;
VAL_ 219 SRRSRRODPB2P_POTk3TypCnfdAuth 0 "Highly Speculative" 1 "Speculative" 2 "Confident" 3 "Highly Confident" ;
VAL_ 219 SRRSRRODPB2P_POTk3TypAuth 0 "Unknown" 1 "Pedestrian" 2 "Bicycle" ;
VAL_ 219 SRRSRRODPB2P_VOTk2DynPrpStsAuth 0 "Stopped" 1 "Not Stopped" ;
VAL_ 219 SRRSRRODPB2P_VOTk2DynPrpAuth 0 "Has Never Moved" 1 "Moving In Same Direction As Host" 2 "Moving In Opposite Direction As Host" 3 "Crossing From Left To Right" 4 "Crossing From Right To Left" ;
VAL_ 219 SRRSRRODPB2P_VOTk2CnfdStsAuth 0 "Highly Speculative" 1 "Speculative" 2 "Confident" 3 "Highly Confident" ;
VAL_ 219 SRRSRRODPB2P_VOTk2MStsAuth 0 "No Object" 1 "New Object" 2 "Latent Track Not Detected this Cycle" 3 "Measured this Cycle" ;
VAL_ 219 SRRSRRODPB2P_VOTk2TypCnfdAuth 0 "Highly Speculative" 1 "Speculative" 2 "Confident" 3 "Highly Confident" ;
VAL_ 219 SRRSRRODPB2P_VOTk3CnfdStsAuth 0 "Highly Speculative" 1 "Speculative" 2 "Confident" 3 "Highly Confident" ;
VAL_ 219 SRRSRRODPB2P_VOTk3DynPrpStsAuth 0 "Stopped" 1 "Not Stopped" ;
VAL_ 219 SRRSRRODPB2P_VOTk3DynPrpAuth 0 "Has Never Moved" 1 "Moving In Same Direction As Host" 2 "Moving In Opposite Direction As Host" 3 "Crossing From Left To Right" 4 "Crossing From Right To Left" ;
VAL_ 219 SRRSRRODPB2P_VOTk3MStsAuth 0 "No Object" 1 "New Object" 2 "Latent Track Not Detected this Cycle" 3 "Measured this Cycle" ;
VAL_ 219 SRRSRRODPB2P_VOTk3TypCnfdAuth 0 "Highly Speculative" 1 "Speculative" 2 "Confident" 3 "Highly Confident" ;
VAL_ 219 SRRSRRODPB2P_VOTk4DynPrpStsAuth 0 "Stopped" 1 "Not Stopped" ;
VAL_ 219 SRRSRRODPB2P_VOTk4DynPrpAuth 0 "Has Never Moved" 1 "Moving In Same Direction As Host" 2 "Moving In Opposite Direction As Host" 3 "Crossing From Left To Right" 4 "Crossing From Right To Left" ;
VAL_ 219 SRRSRRODPB2P_VOTk4CnfdStsAuth 0 "Highly Speculative" 1 "Speculative" 2 "Confident" 3 "Highly Confident" ;
VAL_ 219 SRRSRRODPB2P_VOTk4MStsAuth 0 "No Object" 1 "New Object" 2 "Latent Track Not Detected this Cycle" 3 "Measured this Cycle" ;
VAL_ 219 SRRSRRODPB2P_VOTk4TypCnfdAuth 0 "Highly Speculative" 1 "Speculative" 2 "Confident" 3 "Highly Confident" ;
VAL_ 220 SRRSRRODPB3P_POTk4DynPrpAuth 0 "Has Never Moved" 1 "Has Moved But Currently Stopped" 2 "Moving In Same Direction As Host" 3 "Moving In Opposite Direction As Host" 4 "Crossing Path" ;
VAL_ 220 SRRSRRODPB3P_POTk4CnfdStsAuth 0 "Highly Speculative" 1 "Speculative" 2 "Confident" 3 "Highly Confident" ;
VAL_ 220 SRRSRRODPB3P_POTk4MStsAuth 0 "No Object" 1 "New Object" 2 "Latent Track Not Detected this Cycle" 3 "Measured this Cycle" ;
VAL_ 220 SRRSRRODPB3P_POTk4TypCnfdAuth 0 "Highly Speculative" 1 "Speculative" 2 "Confident" 3 "Highly Confident" ;
VAL_ 220 SRRSRRODPB3P_POTk4TypAuth 0 "Unknown" 1 "Pedestrian" 2 "Bicycle" ;
VAL_ 220 SRRSRRODPB3P_VOTk5DynPrpStsAuth 0 "Stopped" 1 "Not Stopped" ;
VAL_ 220 SRRSRRODPB3P_VOTk5DynPrpAuth 0 "Has Never Moved" 1 "Moving In Same Direction As Host" 2 "Moving In Opposite Direction As Host" 3 "Crossing From Left To Right" 4 "Crossing From Right To Left" ;
VAL_ 220 SRRSRRODPB3P_VOTk5CnfdStsAuth 0 "Highly Speculative" 1 "Speculative" 2 "Confident" 3 "Highly Confident" ;
VAL_ 220 SRRSRRODPB3P_VOTk5MStsAuth 0 "No Object" 1 "New Object" 2 "Latent Track Not Detected this Cycle" 3 "Measured this Cycle" ;
VAL_ 220 SRRSRRODPB3P_VOTk5TypCnfdAuth 0 "Highly Speculative" 1 "Speculative" 2 "Confident" 3 "Highly Confident" ;
VAL_ 220 SRRSRRODPB3P_VOTk6CnfdStsAuth 0 "Highly Speculative" 1 "Speculative" 2 "Confident" 3 "Highly Confident" ;
VAL_ 220 SRRSRRODPB3P_VOTk6DynPrpStsAuth 0 "Stopped" 1 "Not Stopped" ;
VAL_ 220 SRRSRRODPB3P_VOTk6DynPrpAuth 0 "Has Never Moved" 1 "Moving In Same Direction As Host" 2 "Moving In Opposite Direction As Host" 3 "Crossing From Left To Right" 4 "Crossing From Right To Left" ;
VAL_ 220 SRRSRRODPB3P_VOTk6MStsAuth 0 "No Object" 1 "New Object" 2 "Latent Track Not Detected this Cycle" 3 "Measured this Cycle" ;
VAL_ 220 SRRSRRODPB3P_VOTk6TypCnfdAuth 0 "Highly Speculative" 1 "Speculative" 2 "Confident" 3 "Highly Confident" ;
VAL_ 220 SRRSRRODPB3P_VOTk7DynPrpStsAuth 0 "Stopped" 1 "Not Stopped" ;
VAL_ 220 SRRSRRODPB3P_VOTk7DynPrpAuth 0 "Has Never Moved" 1 "Moving In Same Direction As Host" 2 "Moving In Opposite Direction As Host" 3 "Crossing From Left To Right" 4 "Crossing From Right To Left" ;
VAL_ 220 SRRSRRODPB3P_VOTk7CnfdStsAuth 0 "Highly Speculative" 1 "Speculative" 2 "Confident" 3 "Highly Confident" ;
VAL_ 220 SRRSRRODPB3P_VOTk7MStsAuth 0 "No Object" 1 "New Object" 2 "Latent Track Not Detected this Cycle" 3 "Measured this Cycle" ;
VAL_ 220 SRRSRRODPB3P_VOTk7TypCnfdAuth 0 "Highly Speculative" 1 "Speculative" 2 "Confident" 3 "Highly Confident" ;
VAL_ 221 SRRSRRODPB4P_POTk5DynPrpAuth 0 "Has Never Moved" 1 "Has Moved But Currently Stopped" 2 "Moving In Same Direction As Host" 3 "Moving In Opposite Direction As Host" 4 "Crossing Path" ;
VAL_ 221 SRRSRRODPB4P_POTk5CnfdStsAuth 0 "Highly Speculative" 1 "Speculative" 2 "Confident" 3 "Highly Confident" ;
VAL_ 221 SRRSRRODPB4P_POTk5MStsAuth 0 "No Object" 1 "New Object" 2 "Latent Track Not Detected this Cycle" 3 "Measured this Cycle" ;
VAL_ 221 SRRSRRODPB4P_POTk5TypCnfdAuth 0 "Highly Speculative" 1 "Speculative" 2 "Confident" 3 "Highly Confident" ;
VAL_ 221 SRRSRRODPB4P_POTk5TypAuth 0 "Unknown" 1 "Pedestrian" 2 "Bicycle" ;
VAL_ 221 SRRSRRODPB4P_VOTk10DynPrpStAuth 0 "Stopped" 1 "Not Stopped" ;
VAL_ 221 SRRSRRODPB4P_VOTk10DynPrpAuth 0 "Has Never Moved" 1 "Moving In Same Direction As Host" 2 "Moving In Opposite Direction As Host" 3 "Crossing From Left To Right" 4 "Crossing From Right To Left" ;
VAL_ 221 SRRSRRODPB4P_VOTk10CnfdStsAuth 0 "Highly Speculative" 1 "Speculative" 2 "Confident" 3 "Highly Confident" ;
VAL_ 221 SRRSRRODPB4P_VOTk10MStsAuth 0 "No Object" 1 "New Object" 2 "Latent Track Not Detected this Cycle" 3 "Measured this Cycle" ;
VAL_ 221 SRRSRRODPB4P_VOTk10TypCnfdAuth 0 "Highly Speculative" 1 "Speculative" 2 "Confident" 3 "Highly Confident" ;
VAL_ 221 SRRSRRODPB4P_VOTk8CnfdStsAuth 0 "Highly Speculative" 1 "Speculative" 2 "Confident" 3 "Highly Confident" ;
VAL_ 221 SRRSRRODPB4P_VOTk8DynPrpStsAuth 0 "Stopped" 1 "Not Stopped" ;
VAL_ 221 SRRSRRODPB4P_VOTk8DynPrpAuth 0 "Has Never Moved" 1 "Moving In Same Direction As Host" 2 "Moving In Opposite Direction As Host" 3 "Crossing From Left To Right" 4 "Crossing From Right To Left" ;
VAL_ 221 SRRSRRODPB4P_VOTk8MStsAuth 0 "No Object" 1 "New Object" 2 "Latent Track Not Detected this Cycle" 3 "Measured this Cycle" ;
VAL_ 221 SRRSRRODPB4P_VOTk8TypCnfdAuth 0 "Highly Speculative" 1 "Speculative" 2 "Confident" 3 "Highly Confident" ;
VAL_ 221 SRRSRRODPB4P_VOTk9DynPrpStsAuth 0 "Stopped" 1 "Not Stopped" ;
VAL_ 221 SRRSRRODPB4P_VOTk9DynPrpAuth 0 "Has Never Moved" 1 "Moving In Same Direction As Host" 2 "Moving In Opposite Direction As Host" 3 "Crossing From Left To Right" 4 "Crossing From Right To Left" ;
VAL_ 221 SRRSRRODPB4P_VOTk9CnfdStsAuth 0 "Highly Speculative" 1 "Speculative" 2 "Confident" 3 "Highly Confident" ;
VAL_ 221 SRRSRRODPB4P_VOTk9MStsAuth 0 "No Object" 1 "New Object" 2 "Latent Track Not Detected this Cycle" 3 "Measured this Cycle" ;
VAL_ 221 SRRSRRODPB4P_VOTk9TypCnfdAuth 0 "Highly Speculative" 1 "Speculative" 2 "Confident" 3 "Highly Confident" ;
VAL_ 222 SRRSRRODPB5P_IOTk10ElvtnAuth 0 "Not Elevated Elevation" 1 "Speculative Elevation" 2 "Confident Elevation" 3 "Very Confident" ;
VAL_ 222 SRRSRRODPB5P_IOTk10CnfdStsAuth 0 "Highly Speculative" 1 "Speculative" 2 "Confident" 3 "Highly Confident" ;
VAL_ 222 SRRSRRODPB5P_IOTk10MStsAuth 0 "No Object" 1 "New Object" 2 "Latent Track Not Detected this Cycle" 3 "Measured this Cycle" ;
VAL_ 222 SRRSRRODPB5P_IOTk1CnfdStsAuth 0 "Highly Speculative" 1 "Speculative" 2 "Confident" 3 "Highly Confident" ;
VAL_ 222 SRRSRRODPB5P_IOTk10TypCnfdAuth 0 "Highly Speculative" 1 "Speculative" 2 "Confident" 3 "Highly Confident" ;
VAL_ 222 SRRSRRODPB5P_IOTk10TypAuth 0 "Unknown" 1 "Guard Rail" 2 "Tunnel" 3 "Traffic Sign" 4 "Bridge" 5 "Pole" ;
VAL_ 222 SRRSRRODPB5P_IOTk1ElvtnAuth 0 "Not Elevated Elevation" 1 "Speculative Elevation" 2 "Confident Elevation" 3 "Very Confident" ;
VAL_ 222 SRRSRRODPB5P_IOTk1MStsAuth 0 "No Object" 1 "New Object" 2 "Latent Track Not Detected this Cycle" 3 "Measured this Cycle" ;
VAL_ 222 SRRSRRODPB5P_IOTk1TypAuth 0 "Unknown" 1 "Guard Rail" 2 "Tunnel" 3 "Traffic Sign" 4 "Bridge" 5 "Pole" ;
VAL_ 222 SRRSRRODPB5P_IOTk2ElvtnAuth 0 "Not Elevated Elevation" 1 "Speculative Elevation" 2 "Confident Elevation" 3 "Very Confident" ;
VAL_ 222 SRRSRRODPB5P_IOTk2CnfdStsAuth 0 "Highly Speculative" 1 "Speculative" 2 "Confident" 3 "Highly Confident" ;
VAL_ 222 SRRSRRODPB5P_IOTk1TypCnfdAuth 0 "Highly Speculative" 1 "Speculative" 2 "Confident" 3 "Highly Confident" ;
VAL_ 222 SRRSRRODPB5P_IOTk2MStsAuth 0 "No Object" 1 "New Object" 2 "Latent Track Not Detected this Cycle" 3 "Measured this Cycle" ;
VAL_ 222 SRRSRRODPB5P_IOTk2TypCnfdAuth 0 "Highly Speculative" 1 "Speculative" 2 "Confident" 3 "Highly Confident" ;
VAL_ 222 SRRSRRODPB5P_IOTk2TypAuth 0 "Unknown" 1 "Guard Rail" 2 "Tunnel" 3 "Traffic Sign" 4 "Bridge" 5 "Pole" ;
VAL_ 222 SRRSRRODPB5P_IOTk3ElvtnAuth 0 "Not Elevated Elevation" 1 "Speculative Elevation" 2 "Confident Elevation" 3 "Very Confident" ;
VAL_ 222 SRRSRRODPB5P_IOTk3CnfdStsAuth 0 "Highly Speculative" 1 "Speculative" 2 "Confident" 3 "Highly Confident" ;
VAL_ 222 SRRSRRODPB5P_IOTk3MStsAuth 0 "No Object" 1 "New Object" 2 "Latent Track Not Detected this Cycle" 3 "Measured this Cycle" ;
VAL_ 222 SRRSRRODPB5P_IOTk4CnfdStsAuth 0 "Highly Speculative" 1 "Speculative" 2 "Confident" 3 "Highly Confident" ;
VAL_ 222 SRRSRRODPB5P_IOTk3TypCnfdAuth 0 "Highly Speculative" 1 "Speculative" 2 "Confident" 3 "Highly Confident" ;
VAL_ 222 SRRSRRODPB5P_IOTk3TypAuth 0 "Unknown" 1 "Guard Rail" 2 "Tunnel" 3 "Traffic Sign" 4 "Bridge" 5 "Pole" ;
VAL_ 222 SRRSRRODPB5P_IOTk4ElvtnAuth 0 "Not Elevated Elevation" 1 "Speculative Elevation" 2 "Confident Elevation" 3 "Very Confident" ;
VAL_ 222 SRRSRRODPB5P_IOTk4MStsAuth 0 "No Object" 1 "New Object" 2 "Latent Track Not Detected this Cycle" 3 "Measured this Cycle" ;
VAL_ 222 SRRSRRODPB5P_IOTk4TypAuth 0 "Unknown" 1 "Guard Rail" 2 "Tunnel" 3 "Traffic Sign" 4 "Bridge" 5 "Pole" ;
VAL_ 222 SRRSRRODPB5P_IOTk5ElvtnAuth 0 "Not Elevated Elevation" 1 "Speculative Elevation" 2 "Confident Elevation" 3 "Very Confident" ;
VAL_ 222 SRRSRRODPB5P_IOTk5CnfdStsAuth 0 "Highly Speculative" 1 "Speculative" 2 "Confident" 3 "Highly Confident" ;
VAL_ 222 SRRSRRODPB5P_IOTk4TypCnfdAuth 0 "Highly Speculative" 1 "Speculative" 2 "Confident" 3 "Highly Confident" ;
VAL_ 222 SRRSRRODPB5P_IOTk5MStsAuth 0 "No Object" 1 "New Object" 2 "Latent Track Not Detected this Cycle" 3 "Measured this Cycle" ;
VAL_ 222 SRRSRRODPB5P_IOTk5TypCnfdAuth 0 "Highly Speculative" 1 "Speculative" 2 "Confident" 3 "Highly Confident" ;
VAL_ 222 SRRSRRODPB5P_IOTk5TypAuth 0 "Unknown" 1 "Guard Rail" 2 "Tunnel" 3 "Traffic Sign" 4 "Bridge" 5 "Pole" ;
VAL_ 222 SRRSRRODPB5P_IOTk6ElvtnAuth 0 "Not Elevated Elevation" 1 "Speculative Elevation" 2 "Confident Elevation" 3 "Very Confident" ;
VAL_ 222 SRRSRRODPB5P_IOTk6CnfdStsAuth 0 "Highly Speculative" 1 "Speculative" 2 "Confident" 3 "Highly Confident" ;
VAL_ 222 SRRSRRODPB5P_IOTk6MStsAuth 0 "No Object" 1 "New Object" 2 "Latent Track Not Detected this Cycle" 3 "Measured this Cycle" ;
VAL_ 222 SRRSRRODPB5P_IOTk7ElvtnAuth 0 "Not Elevated Elevation" 1 "Speculative Elevation" 2 "Confident Elevation" 3 "Very Confident" ;
VAL_ 222 SRRSRRODPB5P_IOTk7CnfdStsAuth 0 "Highly Speculative" 1 "Speculative" 2 "Confident" 3 "Highly Confident" ;
VAL_ 222 SRRSRRODPB5P_IOTk6TypCnfdAuth 0 "Highly Speculative" 1 "Speculative" 2 "Confident" 3 "Highly Confident" ;
VAL_ 222 SRRSRRODPB5P_IOTk6TypAuth 0 "Unknown" 1 "Guard Rail" 2 "Tunnel" 3 "Traffic Sign" 4 "Bridge" 5 "Pole" ;
VAL_ 222 SRRSRRODPB5P_IOTk7MStsAuth 0 "No Object" 1 "New Object" 2 "Latent Track Not Detected this Cycle" 3 "Measured this Cycle" ;
VAL_ 222 SRRSRRODPB5P_IOTk7TypAuth 0 "Unknown" 1 "Guard Rail" 2 "Tunnel" 3 "Traffic Sign" 4 "Bridge" 5 "Pole" ;
VAL_ 222 SRRSRRODPB5P_IOTk8ElvtnAuth 0 "Not Elevated Elevation" 1 "Speculative Elevation" 2 "Confident Elevation" 3 "Very Confident" ;
VAL_ 222 SRRSRRODPB5P_IOTk8CnfdStsAuth 0 "Highly Speculative" 1 "Speculative" 2 "Confident" 3 "Highly Confident" ;
VAL_ 222 SRRSRRODPB5P_IOTk7TypCnfdAuth 0 "Highly Speculative" 1 "Speculative" 2 "Confident" 3 "Highly Confident" ;
VAL_ 222 SRRSRRODPB5P_IOTk8MStsAuth 0 "No Object" 1 "New Object" 2 "Latent Track Not Detected this Cycle" 3 "Measured this Cycle" ;
VAL_ 222 SRRSRRODPB5P_IOTk9CnfdStsAuth 0 "Highly Speculative" 1 "Speculative" 2 "Confident" 3 "Highly Confident" ;
VAL_ 222 SRRSRRODPB5P_IOTk8TypCnfdAuth 0 "Highly Speculative" 1 "Speculative" 2 "Confident" 3 "Highly Confident" ;
VAL_ 222 SRRSRRODPB5P_IOTk8TypAuth 0 "Unknown" 1 "Guard Rail" 2 "Tunnel" 3 "Traffic Sign" 4 "Bridge" 5 "Pole" ;
VAL_ 222 SRRSRRODPB5P_IOTk9ElvtnAuth 0 "Not Elevated Elevation" 1 "Speculative Elevation" 2 "Confident Elevation" 3 "Very Confident" ;
VAL_ 222 SRRSRRODPB5P_IOTk9MStsAuth 0 "No Object" 1 "New Object" 2 "Latent Track Not Detected this Cycle" 3 "Measured this Cycle" ;
VAL_ 222 SRRSRRODPB5P_IOTk9TypAuth 0 "Unknown" 1 "Guard Rail" 2 "Tunnel" 3 "Traffic Sign" 4 "Bridge" 5 "Pole" ;
VAL_ 222 SRRSRRODPB5P_IOTk9TypCnfdAuth 0 "Highly Speculative" 1 "Speculative" 2 "Confident" 3 "Highly Confident" ;
VAL_ 218 SRRSRRODPB1P_CnstrArDtnCnfdAuth 0 "Highly Speculative" 1 "Speculative" 2 "Confident" 3 "Highly Confident" ;
VAL_ 218 SRRSRRODPB1P_AcqTmStmAuth_Inv 0 "FALSE" 1 "TRUE" ;
VAL_ 218 SRRSRRODPB1P_POTk1DynPrpAuth 0 "Has Never Moved" 1 "Has Moved But Currently Stopped" 2 "Moving In Same Direction As Host" 3 "Moving In Opposite Direction As Host" 4 "Crossing Path" ;
VAL_ 218 SRRSRRODPB1P_POTk1CnfdStsAuth 0 "Highly Speculative" 1 "Speculative" 2 "Confident" 3 "Highly Confident" ;
VAL_ 218 SRRSRRODPB1P_MdCmdStsAuth 0 "Not Radiating" 1 "Reporting Object Data" 2 "Not Reporting Object Data" ;
VAL_ 218 SRRSRRODPB1P_CnstrArDtnStsAuth 0 "Not Detected" 1 "Detected" 2 "Unknown" ;
VAL_ 218 SRRSRRODPB1P_POTk1MStsAuth 0 "No Object" 1 "New Object" 2 "Latent Track Not Detected this Cycle" 3 "Measured this Cycle" ;
VAL_ 218 SRRSRRODPB1P_POTk2CnfdStsAuth 0 "Highly Speculative" 1 "Speculative" 2 "Confident" 3 "Highly Confident" ;
VAL_ 218 SRRSRRODPB1P_POTk1TypCnfdAuth 0 "Highly Speculative" 1 "Speculative" 2 "Confident" 3 "Highly Confident" ;
VAL_ 218 SRRSRRODPB1P_POTk1TypAuth 0 "Unknown" 1 "Pedestrian" 2 "Bicycle" ;
VAL_ 218 SRRSRRODPB1P_POTk2DynPrpAuth 0 "Has Never Moved" 1 "Has Moved But Currently Stopped" 2 "Moving In Same Direction As Host" 3 "Moving In Opposite Direction As Host" 4 "Crossing Path" ;
VAL_ 218 SRRSRRODPB1P_POTk2MStsAuth 0 "No Object" 1 "New Object" 2 "Latent Track Not Detected this Cycle" 3 "Measured this Cycle" ;
VAL_ 218 SRRSRRODPB1P_POTk2TypCnfdAuth 0 "Highly Speculative" 1 "Speculative" 2 "Confident" 3 "Highly Confident" ;
VAL_ 218 SRRSRRODPB1P_POTk2TypAuth 0 "Unknown" 1 "Pedestrian" 2 "Bicycle" ;
VAL_ 218 SRRSRRODPB1P_SnsrUnvAuth 0 "FALSE" 1 "TRUE" ;
VAL_ 218 SRRSRRODPB1P_SnsrBlckdAuth 0 "FALSE" 1 "TRUE" ;
VAL_ 218 SRRSRRODPB1P_ServRqrdAuth 0 "FALSE" 1 "TRUE" ;
VAL_ 218 SRRSRRODPB1P_RdTypCnfdAuth 0 "Highly Speculative" 1 "Speculative" 2 "Confident" 3 "Highly Confident" ;
VAL_ 218 SRRSRRODPB1P_RdTypAuth 0 "Unknown" 1 "City" 2 "Secondary Road" 3 "Highway" 4 "Construction" 5 "Zone Entry" 6 "Construction" 7 "Zone Exit" ;
VAL_ 218 SRRSRRODPB1P_SwpBndwdthStsAuth 0 "Mode A" 1 "Mode B" 2 "Mode C" 3 "Mode D" ;
VAL_ 218 SRRSRRODPB1P_VOTk1DynPrpStsAuth 0 "Stopped" 1 "Not Stopped" ;
VAL_ 218 SRRSRRODPB1P_VOTk1DynPrpAuth 0 "Has Never Moved" 1 "Moving In Same Direction As Host" 2 "Moving In Opposite Direction As Host" 3 "Crossing From Left To Right" 4 "Crossing From Right To Left" ;
VAL_ 218 SRRSRRODPB1P_VOTk1CnfdStsAuth 0 "Highly Speculative" 1 "Speculative" 2 "Confident" 3 "Highly Confident" ;
VAL_ 218 SRRSRRODPB1P_VOTk1MStsAuth 0 "No Object" 1 "New Object" 2 "Latent Track Not Detected this Cycle" 3 "Measured this Cycle" ;
VAL_ 218 SRRSRRODPB1P_VOTk1TypCnfdAuth 0 "Highly Speculative" 1 "Speculative" 2 "Confident" 3 "Highly Confident" ;
VAL_ 223 SRRSRRODPB6P_REOTk1CnfdStsAuth 0 "Highly Speculative" 1 "Speculative" 2 "Confident" 3 "Highly Confident" ;
VAL_ 223 SRRSRRODPB6P_REOTk2CnfdStsAuth 0 "Highly Speculative" 1 "Speculative" 2 "Confident" 3 "Highly Confident" ;
VAL_ 223 SRRSRRODPB6P_REOTk1TypCnfdAuth 0 "Highly Speculative" 1 "Speculative" 2 "Confident" 3 "Highly Confident" ;
VAL_ 223 SRRSRRODPB6P_REOTk1TypAuth 0 "Unknown" 1 "Barriers" 2 "Guard Rails" 3 "Bridge Abutments" 4 "Edge of Road" 5 "Open Area" ;
VAL_ 223 SRRSRRODPB6P_REOTk3CnfdStsAuth 0 "Highly Speculative" 1 "Speculative" 2 "Confident" 3 "Highly Confident" ;
VAL_ 223 SRRSRRODPB6P_REOTk2TypCnfdAuth 0 "Highly Speculative" 1 "Speculative" 2 "Confident" 3 "Highly Confident" ;
VAL_ 223 SRRSRRODPB6P_REOTk2TypAuth 0 "Unknown" 1 "Barriers" 2 "Guard Rails" 3 "Bridge Abutments" 4 "Edge of Road" 5 "Open Area" ;
VAL_ 223 SRRSRRODPB6P_REOTk3TypCnfdAuth 0 "Highly Speculative" 1 "Speculative" 2 "Confident" 3 "Highly Confident" ;
VAL_ 223 SRRSRRODPB6P_REOTk3TypAuth 0 "Unknown" 1 "Barriers" 2 "Guard Rails" 3 "Bridge Abutments" 4 "Edge of Road" 5 "Open Area" ;
VAL_ 40 YRP_YawRateAuth_Inv 0 "FALSE" 1 "TRUE" ;
VAL_ 40 SWIP_StrgWhlAngAuth_Inv 0 "FALSE" 1 "TRUE" ;
VAL_ 40 SWIP_StrgWhlAngAuth_DuD 0 "FALSE" 1 "TRUE" ;
VAL_ 607 DRCDNDP_DRCAvgDrvnAuth_Inv 0 "FALSE" 1 "TRUE" ;
VAL_ 1116 VODVP_VehOdoDispValAuth_Inv 0 "FALSE" 1 "TRUE" ;
VAL_ 1116 OATP_OtsAirTmpCrValAuth_Inv 0 "FALSE" 1 "TRUE" ;
VAL_ 1116 CldrMth 0 "Unknown" 1 "January" 2 "February" 3 "March" 4 "April" 5 "May" 6 "June" 7 "July" 8 "August" 9 "September" 10 "October" 11 "November" 12 "December" ;
VAL_ 1117 ELWWIP_WprFrtFtrReqAuth 0 "Wiper Front Stop" 1 "Wiper Front Crank Suspend" 2 "Wiper Front Depressed Park" 3 "Wiper Front Park" 4 "Wiper Front Winter Park" 5 "Wiper Front Service Park" 6 "Wiper Front Intermittent 5" 7 "Wiper Front Intermittent 4" 8 "Wiper Front Intermittent 3" 9 "Wiper Front Intermittent 2" 10 "Wiper Front Intermittent 1" 11 "Wiper Front Low Wipe" 12 "Wiper Front High Wipe" ;
VAL_ 1118 VMMP_VehMtnMvmtStatAuth 0 "Parked" 1 "Neutral" 2 "Forward" 3 "Reverse" 4 "Invalid" ;
VAL_ 1118 SBZVisIndExtrnCktFltPrLtGtd 0 "FALSE" 1 "TRUE" ;
VAL_ 1118 SBZVisIndExtrnCktFltPrLtGtd_Inv 0 "FALSE" 1 "TRUE" ;
VAL_ 1118 DrSlctdSpdLmtAutMdSpdLmtStat 0 "No Set Speed Change" 1 "Proposed Speed Limit Change" 2 "Accepted Speed Limit Change" 3 "Declined Speed Limit Change" ;
VAL_ 1118 AutoBmSlctAllwd 0 "FALSE" 1 "TRUE" ;
VAL_ 1118 AutoBmSlctAllwd_Inv 0 "FALSE" 1 "TRUE" ;
VAL_ 1118 TrlrHtchTyp 0 "Unknown" 1 "Conventional" 2 "5th Wheel" 3 "Gooseneck" ;
VAL_ 1118 DrvrSeltdTrlrPrsnt 0 "Trailer Present" 1 "No Trailer" ;
VAL_ 1118 FgLmpFrtRtCmd 0 "FALSE" 1 "TRUE" ;
VAL_ 1118 FgLmpFrtLftCmd 0 "FALSE" 1 "TRUE" ;
VAL_ 1118 LogisticModeStatus 0 "Off" 1 "Plant" 2 "Transport Mode" 3 "Storage Mode" ;
VAL_ 1118 SBZVisIndExtrnCktFltPrRtGtd 0 "FALSE" 1 "TRUE" ;
VAL_ 1118 SBZVisIndExtrnCktFltPrRtGtd_Inv 0 "FALSE" 1 "TRUE" ;
VAL_ 1118 SBZAlrtCstChngSetReq 0 "NO_ACTION" 1 "OFF" 2 "ON" 3 "RESERVED_3" 4 "RESERVED_4" 5 "RESERVED_5" 6 "RESERVED_6" 7 "RESERVED_7" ;
VAL_ 1118 LnChgAlrtCstChngSetReq 0 "NO_ACTION" 1 "OFF" 2 "ON" 3 "RESERVED_3" 4 "RESERVED_4" 5 "RESERVED_5" 6 "RESERVED_6" 7 "RESERVED_7" ;
VAL_ 1121 APASP_APAStsAuth 0 "Off" 1 "Standby" 2 "Search_Phase" 3 "Exit_Park" 4 "Enabled" 5 "Guidance_Phase" 6 "Finished" 7 "Error" ;
VAL_ 1121 HSP_DrvAlrtTypCstCurrSetValAuth 0 "SETTING_UNKNOWN" 1 "CHIME" 2 "SEAT" ;
VAL_ 1121 HSP_HptcStOprtlStsAuth 0 "Normal Operation" 1 "Unknown" 2 "Failed" ;
VAL_ 1121 TrffcLgtAsstCstChgSetReq 0 "NO_ACTION" 1 "OFF" 2 "ALERT" 3 "RESERVED_3" 4 "RESERVED_4" 5 "RESERVED_5" 6 "RESERVED_6" 7 "RESERVED_7" ;
VAL_ 1121 RrCrsTrfcAlrtCstChngSetReq 0 "NO_ACTION" 1 "OFF" 2 "ALERT" 3 "ALERT AND BRAKE" 4 "RESERVED_4" 5 "RESERVED_5" 6 "RESERVED_6" 7 "RESERVED_7" ;
VAL_ 1121 GlrFrHgBmRspTypCstChgSetReq 0 "NO_ACTION" 1 "AUTOMATIC_HIGH_BEAM" 2 "GLARE_FREE_HIGH_BEAM" 3 "RESERVED_3" 4 "RESERVED_4" 5 "RESERVED_5" 6 "RESERVED_6" 7 "RESERVED_7" ;
VAL_ 1121 TSMWrngPopUpSts 0 "TSM Warning Off" 1 "TSM Warning On" ;
VAL_ 1121 TSMSgnNtfnWrnDispd 0 "FALSE" 1 "TRUE" ;
VAL_ 1121 TSMPageDispActv 0 "FALSE" 1 "TRUE" ;
VAL_ 1121 TSMCustRstReq 0 "FALSE" 1 "TRUE" ;
VAL_ 1121 RstrCstDfltReq 0 "FALSE" 1 "TRUE" ;
VAL_ 1121 DispMeasSysExtnd 0 "US" 1 "IMPERIAL" 2 "Metric KM/L" 3 "Metric L/100KM" ;
VAL_ 1121 BGI1P_OutsdAmbtLgtLvlStsAuth 0 "Unknown" 1 "Day" 2 "Night" ;
VAL_ 1121 LowBmAct 0 "FALSE" 1 "TRUE" ;
VAL_ 1121 HighBmAct 0 "FALSE" 1 "TRUE" ;
VAL_ 1121 TrnSigSwRtActv 0 "FALSE" 1 "TRUE" ;
VAL_ 1121 TrnSigSwLtActv 0 "FALSE" 1 "TRUE" ;
VAL_ 1121 TrlrConnStat 0 "Not Connected" 1 "Connected" ;
VAL_ 1121 TimeDispFormat 0 "12 Hour Mode" 1 "24 Hour Mode" ;
VAL_ 1121 TDAP_TeenDrvrActvAuth 0 "FALSE" 1 "TRUE" ;
VAL_ 1121 RrCrsTrfcBrkgSysSts 0 "Not Active" 1 "Active" 2 "Failed" ;
VAL_ 1121 TDAP_DrvrIdfrAuth 0 "Driver 1" 1 "Driver 2" 2 "Driver 3" 3 "Driver 4" 4 "Driver 5" 5 "Driver 6" 6 "Driver 7" 7 "Unknown" ;
VAL_ 609 BkUpPwrMdRnCrnkOutSt 0 "FALSE" 1 "TRUE" ;
